VERSION ""

NS_ :

BS_:

BU_: Vector__XXX

BO_ 2566698238 SPOS: 8 Vector__XXX
SG_ SwitchedOutput4 : 0|2@1+ (1,0) [0|3] "" Vector__XXX
SG_ SwitchedOutput3 : 2|2@1+ (1,0) [0|3] "" Vector__XXX
SG_ SwitchedOutput2 : 4|2@1+ (1,0) [0|3] "" Vector__XXX
SG_ SwitchedOutput1 : 6|2@1+ (1,0) [0|3] "" Vector__XXX
SG_ SwitchedOutput8 : 8|2@1+ (1,0) [0|3] "" Vector__XXX
SG_ SwitchedOutput7 : 10|2@1+ (1,0) [0|3] "" Vector__XXX
SG_ SwitchedOutput6 : 12|2@1+ (1,0) [0|3] "" Vector__XXX
SG_ SwitchedOutput5 : 14|2@1+ (1,0) [0|3] "" Vector__XXX
SG_ SwitchedOutput12 : 16|2@1+ (1,0) [0|3] "" Vector__XXX
SG_ SwitchedOutput11 : 18|2@1+ (1,0) [0|3] "" Vector__XXX
SG_ SwitchedOutput10 : 20|2@1+ (1,0) [0|3] "" Vector__XXX
SG_ SwitchedOutput9 : 22|2@1+ (1,0) [0|3] "" Vector__XXX
SG_ SwitchedOutput16 : 24|2@1+ (1,0) [0|3] "" Vector__XXX
SG_ SwitchedOutput15 : 26|2@1+ (1,0) [0|3] "" Vector__XXX
SG_ SwitchedOutput14 : 28|2@1+ (1,0) [0|3] "" Vector__XXX
SG_ SwitchedOutput13 : 30|2@1+ (1,0) [0|3] "" Vector__XXX
SG_ SwitchedOutput20 : 32|2@1+ (1,0) [0|3] "" Vector__XXX
SG_ SwitchedOutput19 : 34|2@1+ (1,0) [0|3] "" Vector__XXX
SG_ SwitchedOutput18 : 36|2@1+ (1,0) [0|3] "" Vector__XXX
SG_ SwitchedOutput17 : 38|2@1+ (1,0) [0|3] "" Vector__XXX
SG_ SwitchedOutput24 : 40|2@1+ (1,0) [0|3] "" Vector__XXX
SG_ SwitchedOutput23 : 42|2@1+ (1,0) [0|3] "" Vector__XXX
SG_ SwitchedOutput22 : 44|2@1+ (1,0) [0|3] "" Vector__XXX
SG_ SwitchedOutput21 : 46|2@1+ (1,0) [0|3] "" Vector__XXX
SG_ SwitchedOutput28 : 48|2@1+ (1,0) [0|3] "" Vector__XXX
SG_ SwitchedOutput27 : 50|2@1+ (1,0) [0|3] "" Vector__XXX
SG_ SwitchedOutput26 : 52|2@1+ (1,0) [0|3] "" Vector__XXX
SG_ SwitchedOutput25 : 54|2@1+ (1,0) [0|3] "" Vector__XXX
SG_ SwitchedOutput32 : 56|2@1+ (1,0) [0|3] "" Vector__XXX
SG_ SwitchedOutput31 : 58|2@1+ (1,0) [0|3] "" Vector__XXX
SG_ SwitchedOutput30 : 60|2@1+ (1,0) [0|3] "" Vector__XXX
SG_ SwitchedOutput29 : 62|2@1+ (1,0) [0|3] "" Vector__XXX

BO_ 2566698494 FPOS: 8 Vector__XXX
SG_ FusedOutput4 : 0|2@1+ (1,0) [0|3] "" Vector__XXX
SG_ FusedOutput3 : 2|2@1+ (1,0) [0|3] "" Vector__XXX
SG_ FusedOutput2 : 4|2@1+ (1,0) [0|3] "" Vector__XXX
SG_ FusedOutput1 : 6|2@1+ (1,0) [0|3] "" Vector__XXX
SG_ FusedOutput8 : 8|2@1+ (1,0) [0|3] "" Vector__XXX
SG_ FusedOutput7 : 10|2@1+ (1,0) [0|3] "" Vector__XXX
SG_ FusedOutput6 : 12|2@1+ (1,0) [0|3] "" Vector__XXX
SG_ FusedOutput5 : 14|2@1+ (1,0) [0|3] "" Vector__XXX
SG_ FusedOutput12 : 16|2@1+ (1,0) [0|3] "" Vector__XXX
SG_ FusedOutput11 : 18|2@1+ (1,0) [0|3] "" Vector__XXX
SG_ FusedOutput10 : 20|2@1+ (1,0) [0|3] "" Vector__XXX
SG_ FusedOutput9 : 22|2@1+ (1,0) [0|3] "" Vector__XXX
SG_ FusedOutput16 : 24|2@1+ (1,0) [0|3] "" Vector__XXX
SG_ FusedOutput15 : 26|2@1+ (1,0) [0|3] "" Vector__XXX
SG_ FusedOutput14 : 28|2@1+ (1,0) [0|3] "" Vector__XXX
SG_ FusedOutput13 : 30|2@1+ (1,0) [0|3] "" Vector__XXX
SG_ FusedOutput20 : 32|2@1+ (1,0) [0|3] "" Vector__XXX
SG_ FusedOutput19 : 34|2@1+ (1,0) [0|3] "" Vector__XXX
SG_ FusedOutput18 : 36|2@1+ (1,0) [0|3] "" Vector__XXX
SG_ FusedOutput17 : 38|2@1+ (1,0) [0|3] "" Vector__XXX
SG_ FusedOutput24 : 40|2@1+ (1,0) [0|3] "" Vector__XXX
SG_ FusedOutput23 : 42|2@1+ (1,0) [0|3] "" Vector__XXX
SG_ FusedOutput22 : 44|2@1+ (1,0) [0|3] "" Vector__XXX
SG_ FusedOutput21 : 46|2@1+ (1,0) [0|3] "" Vector__XXX
SG_ FusedOutput28 : 48|2@1+ (1,0) [0|3] "" Vector__XXX
SG_ FusedOutput27 : 50|2@1+ (1,0) [0|3] "" Vector__XXX
SG_ FusedOutput26 : 52|2@1+ (1,0) [0|3] "" Vector__XXX
SG_ FusedOutput25 : 54|2@1+ (1,0) [0|3] "" Vector__XXX
SG_ FusedOutput32 : 56|2@1+ (1,0) [0|3] "" Vector__XXX
SG_ FusedOutput31 : 58|2@1+ (1,0) [0|3] "" Vector__XXX
SG_ FusedOutput30 : 60|2@1+ (1,0) [0|3] "" Vector__XXX
SG_ FusedOutput29 : 62|2@1+ (1,0) [0|3] "" Vector__XXX

BO_ 2566698750 VEP5: 8 Vector__XXX
SG_ SLIBatteryPackStateOfCharge : 0|16@1+ (0.0025,0) [0|160.6375] "%" Vector__XXX
SG_ SLIBatteryPackCapacity : 16|16@1+ (1,0) [0|64255] "Ah" Vector__XXX
SG_ SLIBatteryPackHealth : 32|8@1+ (0.5,0) [0|125] "%" Vector__XXX
SG_ SLICrnkngPredictMinBattryVoltage : 40|8@1+ (0.2,0) [0|50] "V" Vector__XXX

BO_ 2566699006 HSS2: 8 Vector__XXX
SG_ HybridBatteryPackRemainingCharge : 0|16@1+ (0.0025,0) [0|160.6375] "%" Vector__XXX
SG_ HybridSysEngStopStrtRemnPrcntage : 16|8@1+ (0.4,0) [0|100] "%" Vector__XXX

BO_ 2566699262 AT2S2: 8 Vector__XXX
SG_ Aft2DslPFTmeToNextActvRegen : 0|32@1+ (1,0) [0|4211081215] "s" Vector__XXX
SG_ Aft2SCRSysTmeSncLastSysCleanEvnt : 32|32@1+ (1,0) [0|4211081215] "s" Vector__XXX

BO_ 2566699518 AT1S2: 8 Vector__XXX
SG_ Aft1DslPFTmeToNextActvRegen : 0|32@1+ (1,0) [0|4211081215] "s" Vector__XXX
SG_ Aft1SCRSysTmeSncLastSysCleanEvnt : 32|32@1+ (1,0) [0|4211081215] "s" Vector__XXX

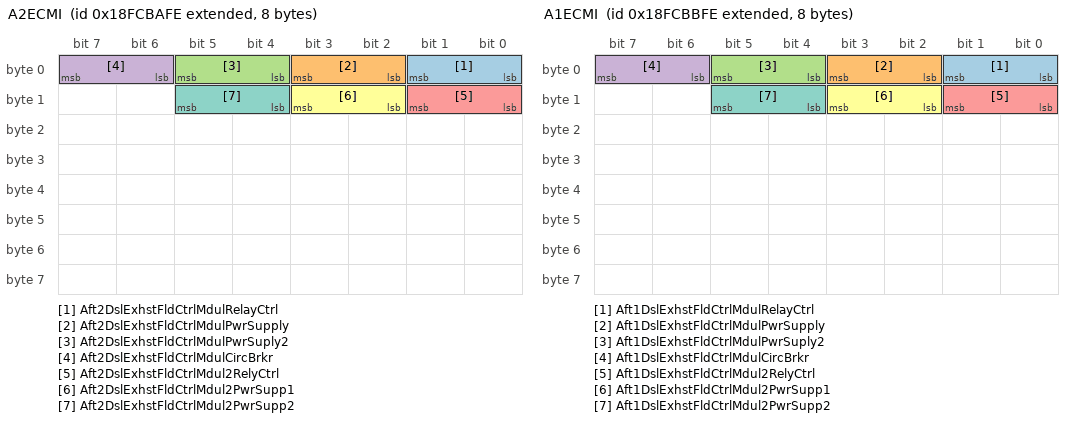
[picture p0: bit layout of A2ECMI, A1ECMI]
BO_ 2566699774 A2ECMI: 8 Vector__XXX
SG_ Aft2DslExhstFldCtrlMdulRelayCtrl : 0|2@1+ (1,0) [0|3] "" Vector__XXX
SG_ Aft2DslExhstFldCtrlMdulPwrSupply : 2|2@1+ (1,0) [0|3] "" Vector__XXX
SG_ Aft2DslExhstFldCtrlMdulPwrSuply2 : 4|2@1+ (1,0) [0|3] "" Vector__XXX
SG_ Aft2DslExhstFldCtrlMdulCircBrkr : 6|2@1+ (1,0) [0|3] "" Vector__XXX
SG_ Aft2DslExhstFldCtrlMdul2RelyCtrl : 8|2@1+ (1,0) [0|3] "" Vector__XXX
SG_ Aft2DslExhstFldCtrlMdul2PwrSupp1 : 10|2@1+ (1,0) [0|3] "" Vector__XXX
SG_ Aft2DslExhstFldCtrlMdul2PwrSupp2 : 12|2@1+ (1,0) [0|3] "" Vector__XXX

BO_ 2566700030 A1ECMI: 8 Vector__XXX
SG_ Aft1DslExhstFldCtrlMdulRelayCtrl : 0|2@1+ (1,0) [0|3] "" Vector__XXX
SG_ Aft1DslExhstFldCtrlMdulPwrSupply : 2|2@1+ (1,0) [0|3] "" Vector__XXX
SG_ Aft1DslExhstFldCtrlMdulPwrSuply2 : 4|2@1+ (1,0) [0|3] "" Vector__XXX
SG_ Aft1DslExhstFldCtrlMdulCircBrkr : 6|2@1+ (1,0) [0|3] "" Vector__XXX
SG_ Aft1DslExhstFldCtrlMdul2RelyCtrl : 8|2@1+ (1,0) [0|3] "" Vector__XXX
SG_ Aft1DslExhstFldCtrlMdul2PwrSupp1 : 10|2@1+ (1,0) [0|3] "" Vector__XXX
SG_ Aft1DslExhstFldCtrlMdul2PwrSupp2 : 12|2@1+ (1,0) [0|3] "" Vector__XXX

BO_ 2566700286 A2SCRSI2: 8 Vector__XXX
SG_ Aftrtrtmnt2TotalDslExhstFldUsed : 0|32@1+ (0.5,0) [0|2105540607.5] "l" Vector__XXX

BO_ 2566700542 A1SCRSI2: 8 Vector__XXX
SG_ Aftrtrtmnt1TotalDslExhstFldUsed : 0|32@1+ (0.5,0) [0|2105540607.5] "l" Vector__XXX
SG_ AftrtrtmntTripDieselExhaustFluid : 32|32@1+ (0.05,0) [0|210554060.75] "l" Vector__XXX

BO_ 2365374206 ETC9: 8 Vector__XXX
SG_ DualCltchTrnsmInputShft1Spd : 0|16@1+ (0.125,0) [0|8031.875] "rpm" Vector__XXX
SG_ DualCltchTrnsmInputShft2Spd : 16|16@1+ (0.125,0) [0|8031.875] "rpm" Vector__XXX
SG_ DualCltchTrnsmSelPreSelctionGear : 32|8@1+ (1,-125) [-125|125] "" Vector__XXX
SG_ DualCltchTrnsmCurrPreSlctionGear : 40|8@1+ (1,-125) [-125|125] "" Vector__XXX

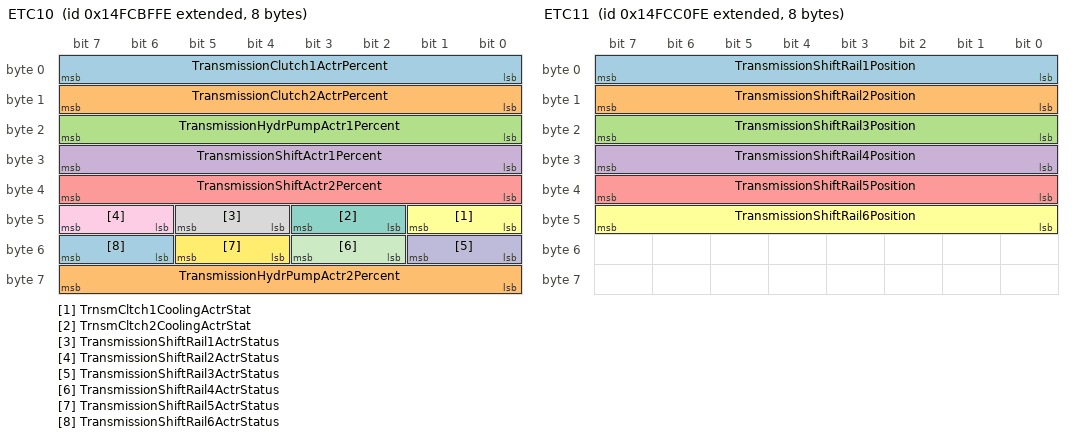
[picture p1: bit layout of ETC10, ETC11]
BO_ 2499592190 ETC10: 8 Vector__XXX
SG_ TransmissionClutch1ActrPercent : 0|8@1+ (0.4,0) [0|100] "%" Vector__XXX
SG_ TransmissionClutch2ActrPercent : 8|8@1+ (0.4,0) [0|100] "%" Vector__XXX
SG_ TransmissionHydrPumpActr1Percent : 16|8@1+ (0.4,0) [0|100] "%" Vector__XXX
SG_ TransmissionShiftActr1Percent : 24|8@1+ (0.4,0) [0|100] "%" Vector__XXX
SG_ TransmissionShiftActr2Percent : 32|8@1+ (0.4,0) [0|100] "%" Vector__XXX
SG_ TrnsmCltch1CoolingActrStat : 40|2@1+ (1,0) [0|3] "" Vector__XXX
SG_ TrnsmCltch2CoolingActrStat : 42|2@1+ (1,0) [0|3] "" Vector__XXX
SG_ TransmissionShiftRail1ActrStatus : 44|2@1+ (1,0) [0|3] "" Vector__XXX
SG_ TransmissionShiftRail2ActrStatus : 46|2@1+ (1,0) [0|3] "" Vector__XXX
SG_ TransmissionShiftRail3ActrStatus : 48|2@1+ (1,0) [0|3] "" Vector__XXX
SG_ TransmissionShiftRail4ActrStatus : 50|2@1+ (1,0) [0|3] "" Vector__XXX
SG_ TransmissionShiftRail5ActrStatus : 52|2@1+ (1,0) [0|3] "" Vector__XXX
SG_ TransmissionShiftRail6ActrStatus : 54|2@1+ (1,0) [0|3] "" Vector__XXX
SG_ TransmissionHydrPumpActr2Percent : 56|8@1+ (0.4,0) [0|100] "%" Vector__XXX

BO_ 2499592446 ETC11: 8 Vector__XXX
SG_ TransmissionShiftRail1Position : 0|8@1+ (0.4,0) [0|100] "%" Vector__XXX
SG_ TransmissionShiftRail2Position : 8|8@1+ (0.4,0) [0|100] "%" Vector__XXX
SG_ TransmissionShiftRail3Position : 16|8@1+ (0.4,0) [0|100] "%" Vector__XXX
SG_ TransmissionShiftRail4Position : 24|8@1+ (0.4,0) [0|100] "%" Vector__XXX
SG_ TransmissionShiftRail5Position : 32|8@1+ (0.4,0) [0|100] "%" Vector__XXX
SG_ TransmissionShiftRail6Position : 40|8@1+ (0.4,0) [0|100] "%" Vector__XXX

BO_ 2566701566 TRF3: 8 Vector__XXX
SG_ TransmissionClutch2Pressure : 0|8@1+ (16,0) [0|4000] "kPa" Vector__XXX
SG_ TrnsmOilTransmissionCoolOtltTemp : 8|8@1+ (1,-40) [-40|210] "deg C" Vector__XXX

BO_ 2566701822 HSS: 8 Vector__XXX
SG_ HybridSystemWarningIndicator : 0|2@1+ (1,0) [0|3] "" Vector__XXX
SG_ HybridSystemOverheatIndicator : 2|2@1+ (1,0) [0|3] "" Vector__XXX
SG_ HybridSystemStopIndicator : 4|2@1+ (1,0) [0|3] "" Vector__XXX
SG_ HybridSystemOBDRelatedDTCStatus : 6|2@1+ (1,0) [0|3] "" Vector__XXX
SG_ PropulsionSystemActive : 8|2@1+ (1,0) [0|3] "" Vector__XXX
SG_ HybridSystemEngineAssistStatus : 10|2@1+ (1,0) [0|3] "" Vector__XXX
SG_ HybridSystemServiceIndicator : 12|2@1+ (1,0) [0|3] "" Vector__XXX
SG_ HybridSystemMtrOverspeedIndictr : 14|2@1+ (1,0) [0|3] "" Vector__XXX
SG_ HybridSysMtrOverspdAudibleAlarm : 16|2@1+ (1,0) [0|3] "" Vector__XXX
SG_ HybridSysElectricAltrntrIndictr : 18|2@1+ (1,0) [0|3] "" Vector__XXX
SG_ HybridSystemRegativeBrkngIndictr : 20|2@1+ (1,0) [0|3] "" Vector__XXX
SG_ HybridSystemInitIndictr : 22|2@1+ (1,0) [0|3] "" Vector__XXX
SG_ HybridSysHghVltgExposureIndictr : 24|2@1+ (1,0) [0|3] "" Vector__XXX
SG_ StoredEnergySourceOnlyModeAllwd : 26|2@1+ (1,0) [0|3] "" Vector__XXX
SG_ StoredEnergySrcIncreasngMdeAllwd : 28|2@1+ (1,0) [0|3] "" Vector__XXX
SG_ StoredEnergySourceLevel : 32|8@1+ (0.4,0) [0|100] "%" Vector__XXX
SG_ HybridPropulsionModeStatus : 40|4@1+ (1,0) [0|15] "" Vector__XXX
SG_ HybridProplsnMdeTransitionStatus : 44|4@1+ (1,0) [0|15] "" Vector__XXX
SG_ ExtEnergySourceConnectnStatus : 48|4@1+ (1,0) [0|15] "" Vector__XXX
SG_ HybridSystemProplsnDisablStatus : 52|2@1+ (1,0) [0|3] "" Vector__XXX

BO_ 2566702078 GFI4: 8 Vector__XXX
SG_ SupplyGasMethanePercentage : 0|16@1+ (0.0025,0) [0|160.6375] "%" Vector__XXX

BO_ 2566702334 A2SCREGT2: 8 Vector__XXX
SG_ Aftrtrtmnt2SCRIntrmedTemperature : 0|16@1+ (0.03125,-273) [-273|1734.96875] "deg C" Vector__XXX
SG_ Aft2SCRIntrmedTempPrelimFMI : 16|5@1+ (1,0) [0|31] "" Vector__XXX

BO_ 2566702590 A1SCREGT2: 8 Vector__XXX
SG_ Aftrtrtmnt1SCRIntrmedTemperature : 0|16@1+ (0.03125,-273) [-273|1734.96875] "deg C" Vector__XXX
SG_ Aft1SCRIntrmedTempPrelimFMI : 16|5@1+ (1,0) [0|31] "" Vector__XXX

BO_ 2566702846 DM57: 1 Vector__XXX
SG_ EngineOBDWarmUpSequence : 0|2@1+ (1,0) [0|3] "" Vector__XXX

BO_ 2566703102 DM56: 200 Vector__XXX
SG_ ModelYear : 7|64@0+ (1,0) [0|0] "ASCII" Vector__XXX
SG_ CertificationEngineFamilyName : 7|1600@0+ (1,0) [0|0] "ASCII" Vector__XXX

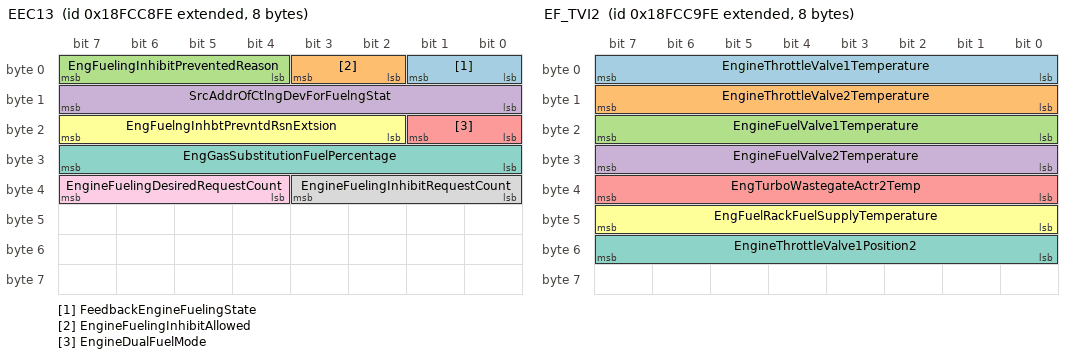
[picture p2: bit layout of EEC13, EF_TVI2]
BO_ 2566703358 EEC13: 8 Vector__XXX
SG_ FeedbackEngineFuelingState : 0|2@1+ (1,0) [0|3] "" Vector__XXX
SG_ EngineFuelingInhibitAllowed : 2|2@1+ (1,0) [0|3] "" Vector__XXX
SG_ EngFuelingInhibitPreventedReason : 4|4@1+ (1,0) [0|15] "" Vector__XXX
SG_ SrcAddrOfCtlngDevForFuelngStat : 8|8@1+ (1,0) [0|255] "" Vector__XXX
SG_ EngineDualFuelMode : 16|2@1+ (1,0) [0|3] "" Vector__XXX
SG_ EngFuelngInhbtPrevntdRsnExtsion : 18|6@1+ (1,0) [0|63] "" Vector__XXX
SG_ EngGasSubstitutionFuelPercentage : 24|8@1+ (0.5,0) [0|125] "%" Vector__XXX
SG_ EngineFuelingInhibitRequestCount : 32|4@1+ (1,0) [0|15] "" Vector__XXX
SG_ EngineFuelingDesiredRequestCount : 36|4@1+ (1,0) [0|15] "" Vector__XXX

BO_ 2566703614 EF_TVI2: 8 Vector__XXX
SG_ EngineThrottleValve1Temperature : 0|8@1+ (1,-40) [-40|210] "deg C" Vector__XXX
SG_ EngineThrottleValve2Temperature : 8|8@1+ (1,-40) [-40|210] "deg C" Vector__XXX
SG_ EngineFuelValve1Temperature : 16|8@1+ (1,-40) [-40|210] "deg C" Vector__XXX
SG_ EngineFuelValve2Temperature : 24|8@1+ (1,-40) [-40|210] "deg C" Vector__XXX
SG_ EngTurboWastegateActr2Temp : 32|8@1+ (1,-40) [-40|210] "deg C" Vector__XXX
SG_ EngFuelRackFuelSupplyTemperature : 40|8@1+ (1,-40) [-40|210] "deg C" Vector__XXX
SG_ EngineThrottleValve1Position2 : 48|8@1+ (0.4,0) [0|100] "%" Vector__XXX

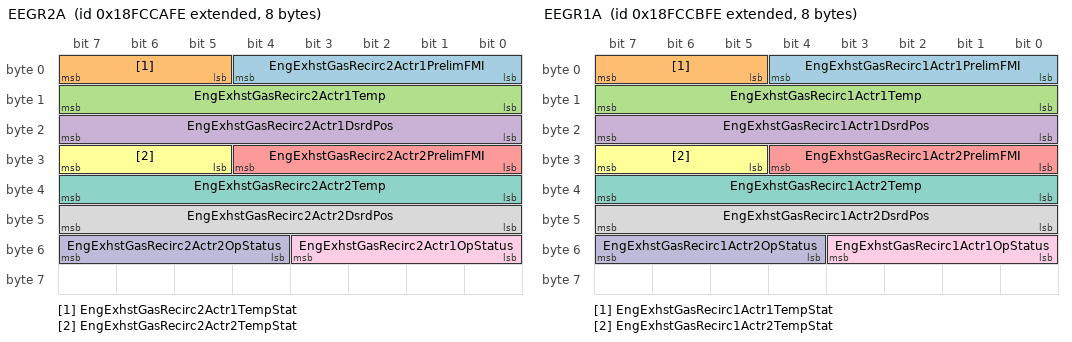
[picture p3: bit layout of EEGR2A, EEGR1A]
BO_ 2566703870 EEGR2A: 8 Vector__XXX
SG_ EngExhstGasRecirc2Actr1PrelimFMI : 0|5@1+ (1,0) [0|31] "" Vector__XXX
SG_ EngExhstGasRecirc2Actr1TempStat : 5|3@1+ (1,0) [0|7] "" Vector__XXX
SG_ EngExhstGasRecirc2Actr1Temp : 8|8@1+ (1,-40) [-40|210] "deg C" Vector__XXX
SG_ EngExhstGasRecirc2Actr1DsrdPos : 16|8@1+ (0.4,0) [0|100] "%" Vector__XXX
SG_ EngExhstGasRecirc2Actr2PrelimFMI : 24|5@1+ (1,0) [0|31] "" Vector__XXX
SG_ EngExhstGasRecirc2Actr2TempStat : 29|3@1+ (1,0) [0|7] "" Vector__XXX
SG_ EngExhstGasRecirc2Actr2Temp : 32|8@1+ (1,-40) [-40|210] "deg C" Vector__XXX
SG_ EngExhstGasRecirc2Actr2DsrdPos : 40|8@1+ (0.4,0) [0|100] "%" Vector__XXX
SG_ EngExhstGasRecirc2Actr1OpStatus : 48|4@1+ (1,0) [0|15] "" Vector__XXX
SG_ EngExhstGasRecirc2Actr2OpStatus : 52|4@1+ (1,0) [0|15] "" Vector__XXX

BO_ 2566704126 EEGR1A: 8 Vector__XXX
SG_ EngExhstGasRecirc1Actr1PrelimFMI : 0|5@1+ (1,0) [0|31] "" Vector__XXX
SG_ EngExhstGasRecirc1Actr1TempStat : 5|3@1+ (1,0) [0|7] "" Vector__XXX
SG_ EngExhstGasRecirc1Actr1Temp : 8|8@1+ (1,-40) [-40|210] "deg C" Vector__XXX
SG_ EngExhstGasRecirc1Actr1DsrdPos : 16|8@1+ (0.4,0) [0|100] "%" Vector__XXX
SG_ EngExhstGasRecirc1Actr2PrelimFMI : 24|5@1+ (1,0) [0|31] "" Vector__XXX
SG_ EngExhstGasRecirc1Actr2TempStat : 29|3@1+ (1,0) [0|7] "" Vector__XXX
SG_ EngExhstGasRecirc1Actr2Temp : 32|8@1+ (1,-40) [-40|210] "deg C" Vector__XXX
SG_ EngExhstGasRecirc1Actr2DsrdPos : 40|8@1+ (0.4,0) [0|100] "%" Vector__XXX
SG_ EngExhstGasRecirc1Actr1OpStatus : 48|4@1+ (1,0) [0|15] "" Vector__XXX
SG_ EngExhstGasRecirc1Actr2OpStatus : 52|4@1+ (1,0) [0|15] "" Vector__XXX

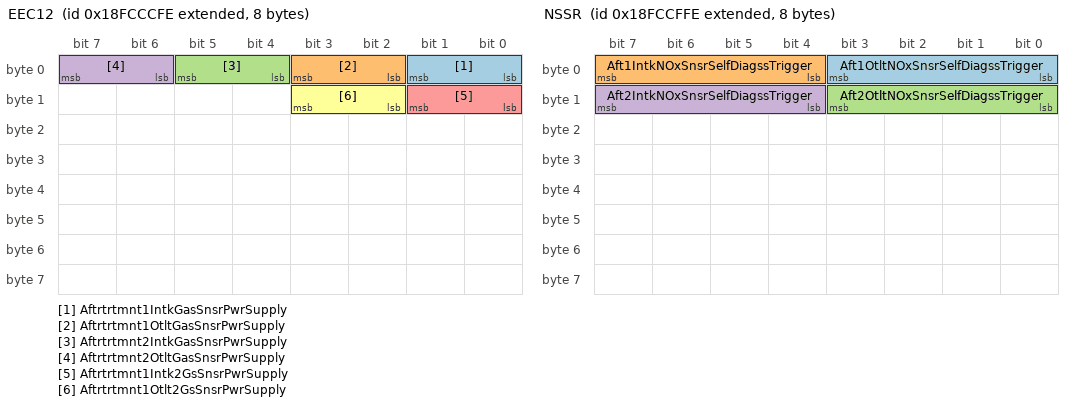
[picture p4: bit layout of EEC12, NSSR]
BO_ 2566704382 EEC12: 8 Vector__XXX
SG_ Aftrtrtmnt1IntkGasSnsrPwrSupply : 0|2@1+ (1,0) [0|3] "" Vector__XXX
SG_ Aftrtrtmnt1OtltGasSnsrPwrSupply : 2|2@1+ (1,0) [0|3] "" Vector__XXX
SG_ Aftrtrtmnt2IntkGasSnsrPwrSupply : 4|2@1+ (1,0) [0|3] "" Vector__XXX
SG_ Aftrtrtmnt2OtltGasSnsrPwrSupply : 6|2@1+ (1,0) [0|3] "" Vector__XXX
SG_ Aftrtrtmnt1Intk2GsSnsrPwrSupply : 8|2@1+ (1,0) [0|3] "" Vector__XXX
SG_ Aftrtrtmnt1Otlt2GsSnsrPwrSupply : 10|2@1+ (1,0) [0|3] "" Vector__XXX

BO_ 2566705150 NSSR: 8 Vector__XXX
SG_ Aft1OtltNOxSnsrSelfDiagssTrigger : 0|4@1+ (1,0) [0|15] "" Vector__XXX
SG_ Aft1IntkNOxSnsrSelfDiagssTrigger : 4|4@1+ (1,0) [0|15] "" Vector__XXX
SG_ Aft2OtltNOxSnsrSelfDiagssTrigger : 8|4@1+ (1,0) [0|15] "" Vector__XXX
SG_ Aft2IntkNOxSnsrSelfDiagssTrigger : 12|4@1+ (1,0) [0|15] "" Vector__XXX

BO_ 2566705406 EPSI: 8 Vector__XXX
SG_ Aftertreatment1ParticulateSensor : 0|16@1+ (0.0125,0) [0|803.1875] "mg/m^3" Vector__XXX
SG_ Aftertreatment2ParticulateSensor : 16|16@1+ (0.0125,0) [0|803.1875] "mg/m^3" Vector__XXX
SG_ Aftrtrtmnt1ParticulateSensorCurr : 32|16@1+ (0.00390625,0) [0|250.99609375] "uA" Vector__XXX

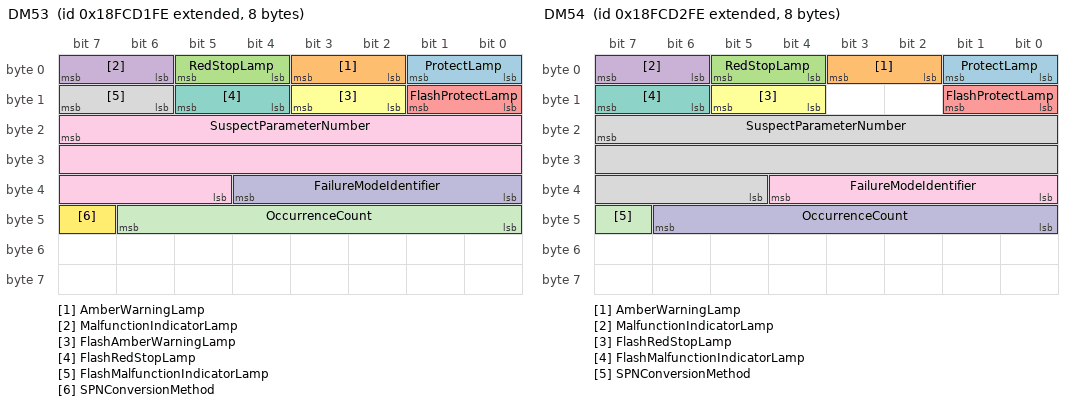
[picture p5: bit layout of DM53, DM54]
BO_ 2566705662 DM53: 8 Vector__XXX
SG_ ProtectLamp : 0|2@1+ (1,0) [0|3] "" Vector__XXX
SG_ AmberWarningLamp : 2|2@1+ (1,0) [0|3] "" Vector__XXX
SG_ RedStopLamp : 4|2@1+ (1,0) [0|3] "" Vector__XXX
SG_ MalfunctionIndicatorLamp : 6|2@1+ (1,0) [0|3] "" Vector__XXX
SG_ FlashProtectLamp : 8|2@1+ (1,0) [0|3] "" Vector__XXX
SG_ FlashAmberWarningLamp : 10|2@1+ (1,0) [0|3] "" Vector__XXX
SG_ FlashRedStopLamp : 12|2@1+ (1,0) [0|3] "" Vector__XXX
SG_ FlashMalfunctionIndicatorLamp : 14|2@1+ (1,0) [0|3] "" Vector__XXX
SG_ SuspectParameterNumber : 23|19@0+ (1,0) [0|524287] "" Vector__XXX
SG_ FailureModeIdentifier : 32|5@1+ (1,0) [0|31] "" Vector__XXX
SG_ OccurrenceCount : 40|7@1+ (1,0) [0|127] "" Vector__XXX
SG_ SPNConversionMethod : 47|1@1+ (1,0) [0|1] "" Vector__XXX

BO_ 2566705918 DM54: 8 Vector__XXX
SG_ ProtectLamp : 0|2@1+ (1,0) [0|3] "" Vector__XXX
SG_ AmberWarningLamp : 2|2@1+ (1,0) [0|3] "" Vector__XXX
SG_ RedStopLamp : 4|2@1+ (1,0) [0|3] "" Vector__XXX
SG_ MalfunctionIndicatorLamp : 6|2@1+ (1,0) [0|3] "" Vector__XXX
SG_ FlashProtectLamp : 8|2@1+ (1,0) [0|3] "" Vector__XXX
SG_ FlashRedStopLamp : 12|2@1+ (1,0) [0|3] "" Vector__XXX
SG_ FlashMalfunctionIndicatorLamp : 14|2@1+ (1,0) [0|3] "" Vector__XXX
SG_ SuspectParameterNumber : 23|19@0+ (1,0) [0|524287] "" Vector__XXX
SG_ FailureModeIdentifier : 32|5@1+ (1,0) [0|31] "" Vector__XXX
SG_ OccurrenceCount : 40|7@1+ (1,0) [0|127] "" Vector__XXX
SG_ SPNConversionMethod : 47|1@1+ (1,0) [0|1] "" Vector__XXX

BO_ 2566706174 DM55: 0 Vector__XXX

BO_ 2566706430 XCP_ID: 0 Vector__XXX

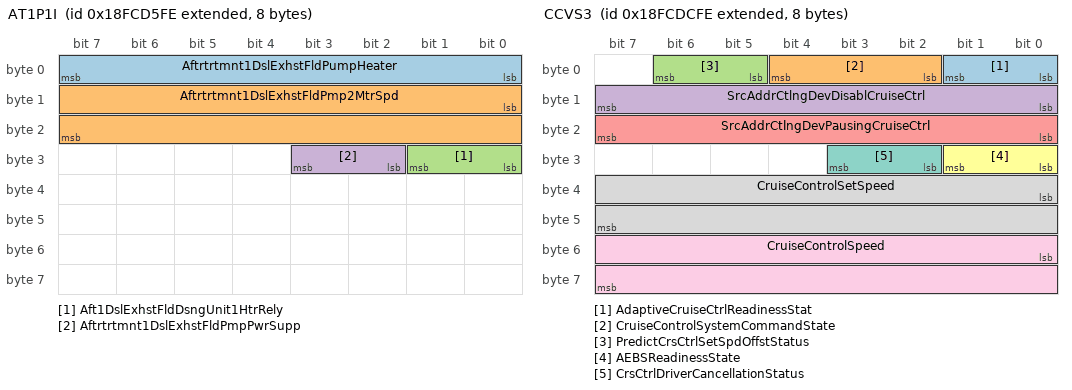
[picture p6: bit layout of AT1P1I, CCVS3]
BO_ 2566706686 AT1P1I: 8 Vector__XXX
SG_ Aftrtrtmnt1DslExhstFldPumpHeater : 0|8@1+ (0.4,0) [0|100] "%" Vector__XXX
SG_ Aftrtrtmnt1DslExhstFldPmp2MtrSpd : 8|16@1+ (0.5,0) [0|32127.5] "rpm" Vector__XXX
SG_ Aft1DslExhstFldDsngUnit1HtrRely : 24|2@1+ (1,0) [0|3] "" Vector__XXX
SG_ Aftrtrtmnt1DslExhstFldPmpPwrSupp : 26|2@1+ (1,0) [0|3] "" Vector__XXX

BO_ 2566706942 AT1DPF2S5: 8 Vector__XXX
SG_ Aft1DslPF2SootSnsrAnalyFreq3 : 0|16@1+ (0.1,0) [0|6425.5] "MHz" Vector__XXX
SG_ Aft1DslPF2SootSnsrFreq3SootSig : 16|16@1+ (0.0025,0) [0|160.6375] "%" Vector__XXX
SG_ Aft1DslPF2SootSnsrAnalyFreq4 : 32|16@1+ (0.1,0) [0|6425.5] "MHz" Vector__XXX
SG_ Aft1DslPF2SootSnsrFreq4SootSig : 48|16@1+ (0.0025,0) [0|160.6375] "%" Vector__XXX

BO_ 2566707198 AT1DPF2S4: 8 Vector__XXX
SG_ Aft1DslPF2SootSnsrAnalyFreq1 : 0|16@1+ (0.1,0) [0|6425.5] "MHz" Vector__XXX
SG_ Aft1DslPF2SootSnsrFreq1SootSig : 16|16@1+ (0.0025,0) [0|160.6375] "%" Vector__XXX
SG_ Aft1DslPF2SootSnsrAnalyFreq2 : 32|16@1+ (0.1,0) [0|6425.5] "MHz" Vector__XXX
SG_ Aft1DslPF2SootSnsrFreq2SootSig : 48|16@1+ (0.0025,0) [0|160.6375] "%" Vector__XXX

BO_ 2566707454 AT1DPF2S3: 8 Vector__XXX
SG_ Aft1DslPF2SootSnsrAnalyRqFreq1 : 0|16@1+ (0.1,0) [0|6425.5] "MHz" Vector__XXX
SG_ Aft1DslPF2SootSnsrAnalyRqFreq2 : 16|16@1+ (0.1,0) [0|6425.5] "MHz" Vector__XXX
SG_ Aft1DslPF2SootSnsrAnalyRqFreq3 : 32|16@1+ (0.1,0) [0|6425.5] "MHz" Vector__XXX
SG_ Aft1DslPF2SootSnsrAnalyRqFreq4 : 48|16@1+ (0.1,0) [0|6425.5] "MHz" Vector__XXX

BO_ 2566707710 AT1DPF1S5: 8 Vector__XXX
SG_ Aft1DslPF1SootSnsrAnalyFreq3 : 0|16@1+ (0.1,0) [0|6425.5] "MHz" Vector__XXX
SG_ Aft1DslPF1SootSnsrFreq3SootSig : 16|16@1+ (0.0025,0) [0|160.6375] "%" Vector__XXX
SG_ Aft1DslPF1SootSnsrAnalyFreq4 : 32|16@1+ (0.1,0) [0|6425.5] "MHz" Vector__XXX
SG_ Aft1DslPF1SootSnsrFreq4SootSig : 48|16@1+ (0.0025,0) [0|160.6375] "%" Vector__XXX

BO_ 2566707966 AT1DPF1S4: 8 Vector__XXX
SG_ Aft1DslPF1SootSnsrAnalyFreq1 : 0|16@1+ (0.1,0) [0|6425.5] "MHz" Vector__XXX
SG_ Aft1DslPF1SootSnsrFreq1SootSig : 16|16@1+ (0.0025,0) [0|160.6375] "%" Vector__XXX
SG_ Aft1DslPF1SootSnsrAnalyFreq2 : 32|16@1+ (0.1,0) [0|6425.5] "MHz" Vector__XXX
SG_ Aft1DslPF1SootSnsrFreq2SootSig : 48|16@1+ (0.0025,0) [0|160.6375] "%" Vector__XXX

BO_ 2566708222 AT1DPF1S3: 8 Vector__XXX
SG_ Aft1DslPF1SootSnsrAnalyRqFreq1 : 0|16@1+ (0.1,0) [0|6425.5] "MHz" Vector__XXX
SG_ Aft1DslPF1SootSnsrAnalyRqFreq2 : 16|16@1+ (0.1,0) [0|6425.5] "MHz" Vector__XXX
SG_ Aft1DslPF1SootSnsrAnalyRqFreq3 : 32|16@1+ (0.1,0) [0|6425.5] "MHz" Vector__XXX
SG_ Aft1DslPF1SootSnsrAnalyRqFreq4 : 48|16@1+ (0.1,0) [0|6425.5] "MHz" Vector__XXX

BO_ 2566708478 CCVS3: 8 Vector__XXX
SG_ AdaptiveCruiseCtrlReadinessStat : 0|2@1+ (1,0) [0|3] "" Vector__XXX
SG_ CruiseControlSystemCommandState : 2|3@1+ (1,0) [0|7] "" Vector__XXX
SG_ PredictCrsCtrlSetSpdOffstStatus : 5|2@1+ (1,0) [0|3] "" Vector__XXX
SG_ SrcAddrCtlngDevDisablCruiseCtrl : 8|8@1+ (1,0) [0|255] "" Vector__XXX
SG_ SrcAddrCtlngDevPausingCruiseCtrl : 16|8@1+ (1,0) [0|255] "" Vector__XXX
SG_ AEBSReadinessState : 24|2@1+ (1,0) [0|3] "" Vector__XXX
SG_ CrsCtrlDriverCancellationStatus : 26|2@1+ (1,0) [0|3] "" Vector__XXX
SG_ CruiseControlSetSpeed : 32|16@1+ (0.00390625,0) [0|250.996] "km/h" Vector__XXX
SG_ CruiseControlSpeed : 48|16@1+ (0.00390625,0) [0|250.996] "km/h" Vector__XXX

BO_ 2566708734 AT2AC3: 8 Vector__XXX
SG_ Aftrtrtmnt2SecondaryAirAbsPress : 0|16@1+ (0.1,0) [0|6425.5] "kPa" Vector__XXX

BO_ 2566708990 AT1AC3: 8 Vector__XXX
SG_ Aftrtrtmnt1SecondaryAirAbsPress : 0|16@1+ (0.1,0) [0|6425.5] "kPa" Vector__XXX

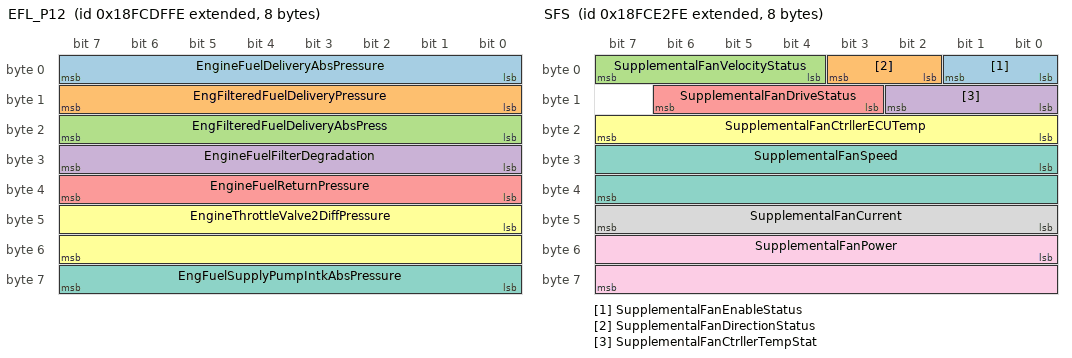
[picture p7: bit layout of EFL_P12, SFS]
BO_ 2566709246 EFL_P12: 8 Vector__XXX
SG_ EngineFuelDeliveryAbsPressure : 0|8@1+ (4,0) [0|1000] "kPa" Vector__XXX
SG_ EngFilteredFuelDeliveryPressure : 8|8@1+ (4,0) [0|1000] "kPa" Vector__XXX
SG_ EngFilteredFuelDeliveryAbsPress : 16|8@1+ (4,0) [0|1000] "kPa" Vector__XXX
SG_ EngineFuelFilterDegradation : 24|8@1+ (1,0) [0|250] "%" Vector__XXX
SG_ EngineFuelReturnPressure : 32|8@1+ (1.64,-7) [-7|403] "kPa" Vector__XXX
SG_ EngineThrottleValve2DiffPressure : 40|16@1+ (0.1,0) [0|6425.5] "kPa" Vector__XXX
SG_ EngFuelSupplyPumpIntkAbsPressure : 56|8@1+ (5,0) [0|1250] "kPa" Vector__XXX

BO_ 2566709502 DPFC2: 8 Vector__XXX
SG_ Aft1DslPFIntkTemperatuRstPoint : 0|16@1+ (0.03125,-273) [-273|1734.96875] "deg C" Vector__XXX
SG_ EngineUnburnedFuelPercentage : 16|16@1+ (0.0025,0) [0|160.6375] "%" Vector__XXX
SG_ Aftertreatment1FuelMassRate : 32|16@1+ (0.05,0) [0|3212.75] "g/m" Vector__XXX
SG_ Aftertreatment2FuelMassRate : 48|16@1+ (0.05,0) [0|3212.75] "g/m" Vector__XXX

BO_ 2566709758 LFE2: 8 Vector__XXX
SG_ EngineFuelRate : 0|32@1+ (0.001,0) [0|4211081.215] "l/h" Vector__XXX
SG_ EngineDieselFuelDemandRate : 32|16@1+ (0.05,0) [0|3212.75] "l/h" Vector__XXX

BO_ 2566710014 SFS: 8 Vector__XXX
SG_ SupplementalFanEnableStatus : 0|2@1+ (1,0) [0|3] "" Vector__XXX
SG_ SupplementalFanDirectionStatus : 2|2@1+ (1,0) [0|3] "" Vector__XXX
SG_ SupplementalFanVelocityStatus : 4|4@1+ (1,0) [0|15] "" Vector__XXX
SG_ SupplementalFanCtrllerTempStat : 8|3@1+ (1,0) [0|7] "" Vector__XXX
SG_ SupplementalFanDriveStatus : 11|4@1+ (1,0) [0|15] "" Vector__XXX
SG_ SupplementalFanCtrllerECUTemp : 16|8@1+ (1,-40) [-40|210] "deg C" Vector__XXX
SG_ SupplementalFanSpeed : 24|16@1+ (0.5,0) [0|32127.5] "rpm" Vector__XXX
SG_ SupplementalFanCurrent : 40|8@1+ (1,-125) [-125|125] "A" Vector__XXX
SG_ SupplementalFanPower : 48|16@1+ (0.5,0) [0|32127.5] "W" Vector__XXX

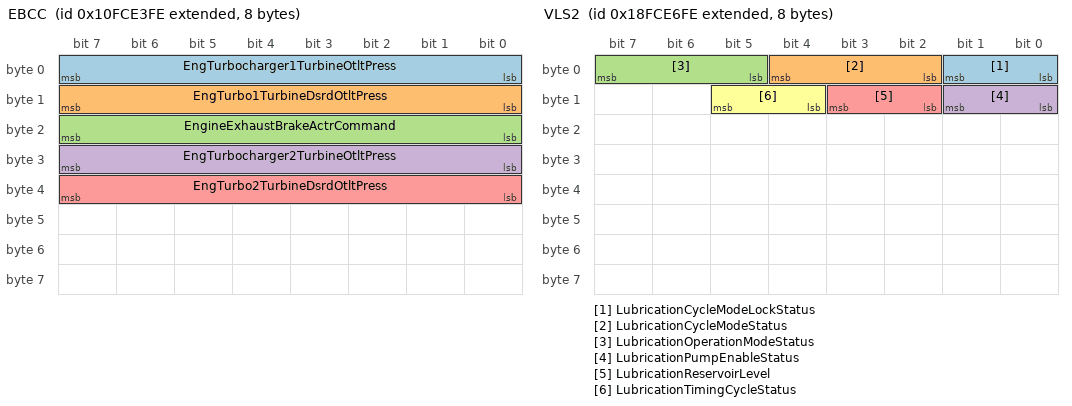
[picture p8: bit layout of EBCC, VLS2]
BO_ 2432492542 EBCC: 8 Vector__XXX
SG_ EngTurbocharger1TurbineOtltPress : 0|8@1+ (2,0) [0|500] "kPa" Vector__XXX
SG_ EngTurbo1TurbineDsrdOtltPress : 8|8@1+ (2,0) [0|500] "kPa" Vector__XXX
SG_ EngineExhaustBrakeActrCommand : 16|8@1+ (0.4,0) [0|100] "%" Vector__XXX
SG_ EngTurbocharger2TurbineOtltPress : 24|8@1+ (2,0) [0|500] "kPa" Vector__XXX
SG_ EngTurbo2TurbineDsrdOtltPress : 32|8@1+ (2,0) [0|500] "kPa" Vector__XXX

BO_ 2566710526 EFP: 8 Vector__XXX
SG_ EngineFuelDynamicViscosity : 0|16@1+ (0.015625,0) [0|1003.984375] "Cp" Vector__XXX
SG_ EngineFuelDensity : 16|16@1+ (3.052E-005,0) [0|1.961] "g/cc" Vector__XXX
SG_ EngineFuelDielectricity : 32|16@1+ (0.0001220703125,0) [0|7.844] "" Vector__XXX
SG_ EngineFuelTemperature : 48|16@1+ (0.03125,-273) [-273|1734.96875] "deg C" Vector__XXX

BO_ 2566710782 HOP: 8 Vector__XXX
SG_ HydraulicOilDynamicViscosity : 0|16@1+ (0.015625,0) [0|1003.984375] "Cp" Vector__XXX
SG_ HydraulicOilDensity : 16|16@1+ (3.052E-005,0) [0|1.961] "g/cc" Vector__XXX
SG_ HydrOilRelativeDielectricity : 32|16@1+ (0.0001220703125,0) [0|7.844] "" Vector__XXX
SG_ HydraulicOilTemperature : 48|16@1+ (0.03125,-273) [-273|1734.96875] "deg C" Vector__XXX

BO_ 2566711038 VLS2: 8 Vector__XXX
SG_ LubricationCycleModeLockStatus : 0|2@1+ (1,0) [0|3] "" Vector__XXX
SG_ LubricationCycleModeStatus : 2|3@1+ (1,0) [0|7] "" Vector__XXX
SG_ LubricationOperationModeStatus : 5|3@1+ (1,0) [0|7] "" Vector__XXX
SG_ LubricationPumpEnableStatus : 8|2@1+ (1,0) [0|3] "" Vector__XXX
SG_ LubricationReservoirLevel : 10|2@1+ (1,0) [0|3] "" Vector__XXX
SG_ LubricationTimingCycleStatus : 12|2@1+ (1,0) [0|3] "" Vector__XXX

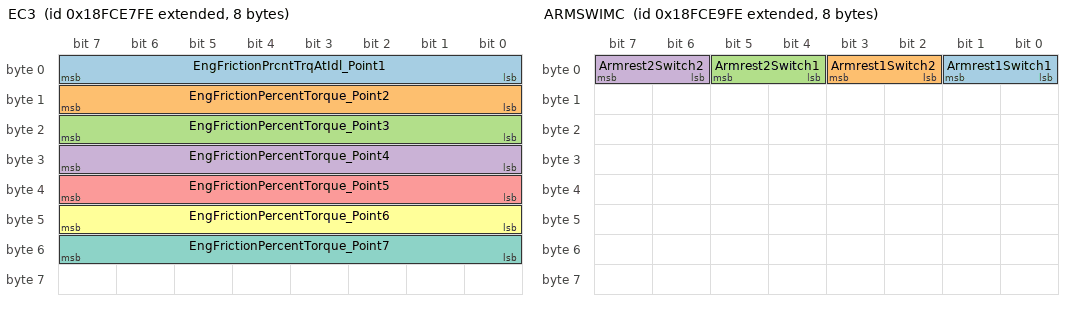
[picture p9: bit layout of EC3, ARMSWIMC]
BO_ 2566711294 EC3: 8 Vector__XXX
SG_ EngFrictionPrcntTrqAtIdl_Point1 : 0|8@1+ (1,-125) [-125|125] "%" Vector__XXX
SG_ EngFrictionPercentTorque_Point2 : 8|8@1+ (1,-125) [-125|125] "%" Vector__XXX
SG_ EngFrictionPercentTorque_Point3 : 16|8@1+ (1,-125) [-125|125] "%" Vector__XXX
SG_ EngFrictionPercentTorque_Point4 : 24|8@1+ (1,-125) [-125|125] "%" Vector__XXX
SG_ EngFrictionPercentTorque_Point5 : 32|8@1+ (1,-125) [-125|125] "%" Vector__XXX
SG_ EngFrictionPercentTorque_Point6 : 40|8@1+ (1,-125) [-125|125] "%" Vector__XXX
SG_ EngFrictionPercentTorque_Point7 : 48|8@1+ (1,-125) [-125|125] "%" Vector__XXX

BO_ 2566711550 IVAC: 8 Vector__XXX
SG_ IntkVlvActSysOilPrs1SolenoidCtrl : 0|2@1+ (1,0) [0|3] "" Vector__XXX
SG_ IntkVlvActSysOilPrs2SolenoidCtrl : 2|2@1+ (1,0) [0|3] "" Vector__XXX

BO_ 2566711806 ARMSWIMC: 8 Vector__XXX
SG_ Armrest1Switch1 : 0|2@1+ (1,0) [0|3] "" Vector__XXX
SG_ Armrest1Switch2 : 2|2@1+ (1,0) [0|3] "" Vector__XXX
SG_ Armrest2Switch1 : 4|2@1+ (1,0) [0|3] "" Vector__XXX
SG_ Armrest2Switch2 : 6|2@1+ (1,0) [0|3] "" Vector__XXX

BO_ 2566712318 AFT2NAI: 8 Vector__XXX
SG_ Aftrtrtmnt2NOxAdsorberRegenStat : 0|2@1+ (1,0) [0|3] "" Vector__XXX
SG_ Aft2NOxAdsorberDesulfationStat : 2|2@1+ (1,0) [0|3] "" Vector__XXX

BO_ 2566712574 AFT1NAI: 8 Vector__XXX
SG_ Aftrtrtmnt1NOxAdsorberRegenStat : 0|2@1+ (1,0) [0|3] "" Vector__XXX
SG_ Aft1NOxAdsorberDesulfationStat : 2|2@1+ (1,0) [0|3] "" Vector__XXX

BO_ 2566712830 AT2WUDOC: 8 Vector__XXX
SG_ Aft2WarmUpDslOxidtnCtlystIntkTmp : 0|16@1+ (0.03125,-273) [-273|1734.96875] "deg C" Vector__XXX
SG_ Aft2WarmUpDslOxidtnCtlystOtltTmp : 16|16@1+ (0.03125,-273) [-273|1734.96875] "deg C" Vector__XXX

BO_ 2499604222 LLRE: 8 Vector__XXX
SG_ BladeElevationDeviationLeft : 0|16@1+ (1,-32000) [-32000|32255] "mm" Vector__XXX
SG_ BladeElevationDeviationRight : 16|16@1+ (1,-32000) [-32000|32255] "mm" Vector__XXX
SG_ BldReferenceElevationOffsetLeft : 32|16@1+ (1,-32000) [-32000|32255] "mm" Vector__XXX
SG_ BldReferenceElevationOffsetRight : 48|16@1+ (1,-32000) [-32000|32255] "mm" Vector__XXX

BO_ 2499604478 EFL_P11: 8 Vector__XXX
SG_ EngExhstGasRecirc1IntkAbsPress : 0|16@1+ (0.1,0) [0|6425.5] "kPa" Vector__XXX
SG_ EngExhstGasRecirc1OtltAbsPress : 16|16@1+ (0.1,0) [0|6425.5] "kPa" Vector__XXX
SG_ EngineOilPressure : 32|16@1+ (0.1,0) [0|6425.5] "kPa" Vector__XXX
SG_ EngineFuelDeliveryPressure : 48|16@1+ (0.1,0) [0|6425.5] "kPa" Vector__XXX

BO_ 2566713598 EFS2: 8 Vector__XXX
SG_ EngFuelFilterIntakeAbsPressure : 0|8@1+ (2,0) [0|500] "kPa" Vector__XXX
SG_ EngineFuelFilterDegradation : 8|8@1+ (1,0) [0|250] "%" Vector__XXX
SG_ FuelTankTransferPump : 16|2@1+ (1,0) [0|3] "" Vector__XXX
SG_ FuelTankTransferPumpPressure : 24|16@1+ (0.1,0) [0|6425.5] "kPa" Vector__XXX

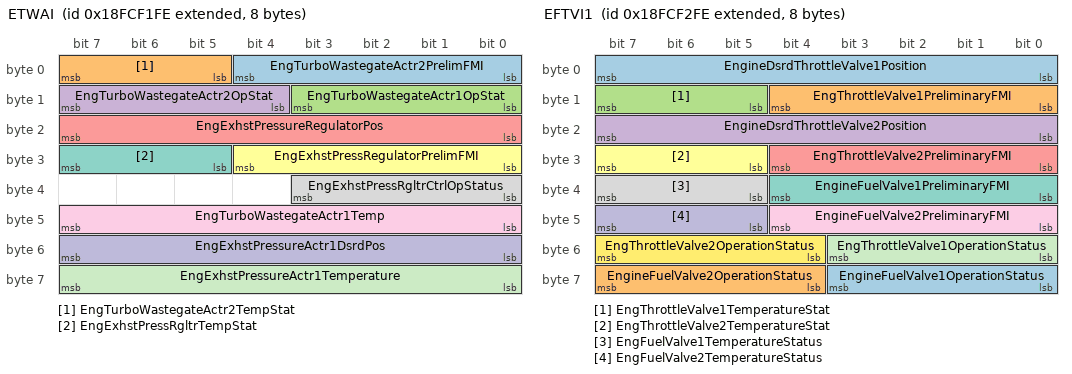
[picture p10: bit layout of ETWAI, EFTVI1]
BO_ 2566713854 ETWAI: 8 Vector__XXX
SG_ EngTurboWastegateActr2PrelimFMI : 0|5@1+ (1,0) [0|31] "" Vector__XXX
SG_ EngTurboWastegateActr2TempStat : 5|3@1+ (1,0) [0|7] "" Vector__XXX
SG_ EngTurboWastegateActr1OpStat : 8|4@1+ (1,0) [0|15] "" Vector__XXX
SG_ EngTurboWastegateActr2OpStat : 12|4@1+ (1,0) [0|15] "" Vector__XXX
SG_ EngExhstPressureRegulatorPos : 16|8@1+ (0.4,0) [0|100] "%" Vector__XXX
SG_ EngExhstPressRegulatorPrelimFMI : 24|5@1+ (1,0) [0|31] "" Vector__XXX
SG_ EngExhstPressRgltrTempStat : 29|3@1+ (1,0) [0|7] "" Vector__XXX
SG_ EngExhstPressRgltrCtrlOpStatus : 32|4@1+ (1,0) [0|15] "" Vector__XXX
SG_ EngTurboWastegateActr1Temp : 40|8@1+ (1,-40) [-40|210] "deg C" Vector__XXX
SG_ EngExhstPressureActr1DsrdPos : 48|8@1+ (0.4,0) [0|100] "%" Vector__XXX
SG_ EngExhstPressureActr1Temperature : 56|8@1+ (1,-40) [-40|210] "deg C" Vector__XXX

BO_ 2566714110 EFTVI1: 8 Vector__XXX
SG_ EngineDsrdThrottleValve1Position : 0|8@1+ (0.4,0) [0|100] "%" Vector__XXX
SG_ EngThrottleValve1PreliminaryFMI : 8|5@1+ (1,0) [0|31] "" Vector__XXX
SG_ EngThrottleValve1TemperatureStat : 13|3@1+ (1,0) [0|7] "" Vector__XXX
SG_ EngineDsrdThrottleValve2Position : 16|8@1+ (0.4,0) [0|100] "%" Vector__XXX
SG_ EngThrottleValve2PreliminaryFMI : 24|5@1+ (1,0) [0|31] "" Vector__XXX
SG_ EngThrottleValve2TemperatureStat : 29|3@1+ (1,0) [0|7] "" Vector__XXX
SG_ EngineFuelValve1PreliminaryFMI : 32|5@1+ (1,0) [0|31] "" Vector__XXX
SG_ EngFuelValve1TemperatureStatus : 37|3@1+ (1,0) [0|7] "" Vector__XXX
SG_ EngineFuelValve2PreliminaryFMI : 40|5@1+ (1,0) [0|31] "" Vector__XXX
SG_ EngFuelValve2TemperatureStatus : 45|3@1+ (1,0) [0|7] "" Vector__XXX
SG_ EngThrottleValve1OperationStatus : 48|4@1+ (1,0) [0|15] "" Vector__XXX
SG_ EngThrottleValve2OperationStatus : 52|4@1+ (1,0) [0|15] "" Vector__XXX
SG_ EngineFuelValve1OperationStatus : 56|4@1+ (1,0) [0|15] "" Vector__XXX
SG_ EngineFuelValve2OperationStatus : 60|4@1+ (1,0) [0|15] "" Vector__XXX

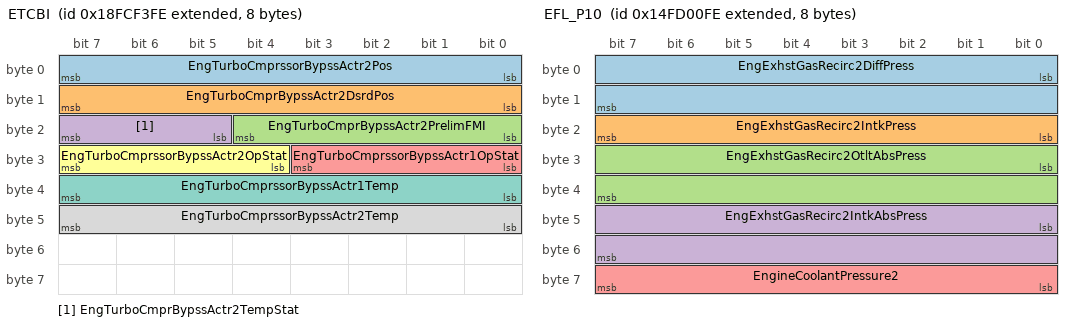
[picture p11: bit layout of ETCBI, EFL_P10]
BO_ 2566714366 ETCBI: 8 Vector__XXX
SG_ EngTurboCmprssorBypssActr2Pos : 0|8@1+ (0.4,0) [0|100] "%" Vector__XXX
SG_ EngTurboCmprBypssActr2DsrdPos : 8|8@1+ (0.4,0) [0|100] "%" Vector__XXX
SG_ EngTurboCmprBypssActr2PrelimFMI : 16|5@1+ (1,0) [0|31] "" Vector__XXX
SG_ EngTurboCmprBypssActr2TempStat : 21|3@1+ (1,0) [0|7] "" Vector__XXX
SG_ EngTurboCmprssorBypssActr1OpStat : 24|4@1+ (1,0) [0|15] "" Vector__XXX
SG_ EngTurboCmprssorBypssActr2OpStat : 28|4@1+ (1,0) [0|15] "" Vector__XXX
SG_ EngTurboCmprssorBypssActr1Temp : 32|8@1+ (1,-40) [-40|210] "deg C" Vector__XXX
SG_ EngTurboCmprssorBypssActr2Temp : 40|8@1+ (1,-40) [-40|210] "deg C" Vector__XXX

BO_ 2566714622 CAC2: 8 Vector__XXX
SG_ EngChargeAirCool2IntkTemperature : 0|16@1+ (0.03125,-273) [-273|1734.96875] "deg C" Vector__XXX
SG_ EngChargeAirCool2OtltTemperature : 16|16@1+ (0.03125,-273) [-273|1734.96875] "deg C" Vector__XXX
SG_ EngChargeAirCool2AmbientAirTemp : 32|16@1+ (0.03125,-273) [-273|1734.96875] "deg C" Vector__XXX
SG_ EngineChargeAirCooler2Efficiency : 48|8@1+ (0.4,0) [0|100] "%" Vector__XXX

BO_ 2566714878 CAC2P: 8 Vector__XXX
SG_ EngChargeAirCool2PreCoolIntkTemp : 0|16@1+ (0.03125,-273) [-273|1734.96875] "deg C" Vector__XXX
SG_ EngChargeAirCool2PreCoolOtltTemp : 16|16@1+ (0.03125,-273) [-273|1734.96875] "deg C" Vector__XXX
SG_ EngineChargeAirCool2PreCoolEff : 32|8@1+ (0.4,0) [0|100] "%" Vector__XXX

BO_ 2566715134 CAC1: 8 Vector__XXX
SG_ EngChargeAirCool1IntkTemperature : 0|16@1+ (0.03125,-273) [-273|1734.96875] "deg C" Vector__XXX
SG_ EngChargeAirCool1AmbientAirTemp : 16|16@1+ (0.03125,-273) [-273|1734.96875] "deg C" Vector__XXX
SG_ EngineChargeAirCooler1Efficiency : 32|8@1+ (0.4,0) [0|100] "%" Vector__XXX

BO_ 2566715390 CAC1P: 8 Vector__XXX
SG_ EngChargeAirCool1PreCoolIntkTemp : 0|16@1+ (0.03125,-273) [-273|1734.96875] "deg C" Vector__XXX
SG_ EngChargeAirCool1PreCoolOtltTemp : 16|16@1+ (0.03125,-273) [-273|1734.96875] "deg C" Vector__XXX
SG_ EngineChargeAirCool1PreCoolEff : 32|8@1+ (0.4,0) [0|100] "%" Vector__XXX

BO_ 2566715646 DPF2S2: 8 Vector__XXX
SG_ Aftrtrtmnt2DslPFSootSigStdDviat : 0|16@1+ (0.0025,0) [0|160.6375] "%" Vector__XXX
SG_ Aftrtrtmnt2DslPFSootSignalMax : 16|16@1+ (0.0025,0) [0|160.6375] "%" Vector__XXX
SG_ Aftrtrtmnt2DslPFSootSignalMin : 32|16@1+ (0.0025,0) [0|160.6375] "%" Vector__XXX

BO_ 2566715902 DPF1S2: 8 Vector__XXX
SG_ Aftrtrtmnt1DslPFSootSigStdDviat : 0|16@1+ (0.0025,0) [0|160.6375] "%" Vector__XXX
SG_ Aftrtrtmnt1DslPFSootSignalMax : 16|16@1+ (0.0025,0) [0|160.6375] "%" Vector__XXX
SG_ Aftrtrtmnt1DslPFSootSignalMin : 32|16@1+ (0.0025,0) [0|160.6375] "%" Vector__XXX

BO_ 2633825022 EEC11: 8 Vector__XXX
SG_ EngExhstGasRecirc2Valve1Ctrl : 0|16@1+ (0.0025,0) [0|160.6375] "%" Vector__XXX
SG_ EngExhstGasRecirc2Valve2Ctrl : 16|16@1+ (0.0025,0) [0|160.6375] "%" Vector__XXX
SG_ EngExhstGasRecirc2Valve1PosError : 32|16@1+ (0.004,-125) [-125|132.02] "%" Vector__XXX
SG_ EngExhstGasRecirc2Valve2PosError : 48|16@1+ (0.004,-125) [-125|132.02] "%" Vector__XXX

BO_ 2499607550 EMAP: 8 Vector__XXX
SG_ EngExhstMnfldBnk1FlwBalVlvActrPs : 0|16@1+ (0.0025,0) [0|160.6375] "%" Vector__XXX
SG_ EngExhstMnfldBnk2FlwBalVlvActrPs : 16|16@1+ (0.0025,0) [0|160.6375] "%" Vector__XXX

BO_ 2633825534 EMAC: 8 Vector__XXX
SG_ EngExhstMfBnk1FlwBalVlvActrCtrl : 0|16@1+ (0.0025,0) [0|160.6375] "%" Vector__XXX
SG_ EngExhstMfBnk2FlwBalVlvActrCtrl : 16|16@1+ (0.0025,0) [0|160.6375] "%" Vector__XXX

BO_ 2432499198 EEC9: 8 Vector__XXX
SG_ EngExhstGasRecirc2ValvePos : 0|16@1+ (0.0025,0) [0|160.6375] "%" Vector__XXX
SG_ EngExhstGasRecirc2Valve2Pos : 16|16@1+ (0.0025,0) [0|160.6375] "%" Vector__XXX
SG_ CommandedEngineFuelRailPressure : 32|16@1+ (0.00390625,0) [0|250.996] "MPa" Vector__XXX
SG_ CmdedEngFuelInjectionCtrlPress : 48|16@1+ (0.00390625,0) [0|250.996] "MPa" Vector__XXX

BO_ 2633826046 EEC10: 8 Vector__XXX
SG_ EngExhstGasRecirc2CoolIntkTemp : 0|16@1+ (0.03125,-273) [-273|1734.96875] "deg C" Vector__XXX
SG_ EngExhstGsRecirc2ClIntkGsAbsPrs : 16|16@1+ (0.5,0) [0|32127.5] "kPa" Vector__XXX
SG_ EngExhstGasRecirculation2CoolEff : 32|8@1+ (0.4,0) [0|100] "%" Vector__XXX
SG_ EngExhstGasRecirc2ClBypssActrPos : 40|8@1+ (0.4,0) [0|100] "%" Vector__XXX

BO_ 2566717438 ET5: 8 Vector__XXX
SG_ EngExhstGasRecirc2Temperature : 0|16@1+ (0.03125,-273) [-273|1734.96875] "deg C" Vector__XXX
SG_ EngExhstGasRecirc2MixerIntkTemp : 16|16@1+ (0.03125,-273) [-273|1734.96875] "deg C" Vector__XXX

BO_ 2499608830 EFL_P10: 8 Vector__XXX
SG_ EngExhstGasRecirc2DiffPress : 0|16@1+ (0.0078125,-250) [-250|251.99] "kPa" Vector__XXX
SG_ EngExhstGasRecirc2IntkPress : 16|8@1+ (2,0) [0|500] "kPa" Vector__XXX
SG_ EngExhstGasRecirc2OtltAbsPress : 24|16@1+ (0.1,0) [0|6425.5] "kPa" Vector__XXX
SG_ EngExhstGasRecirc2IntkAbsPress : 40|16@1+ (0.1,0) [0|6425.5] "kPa" Vector__XXX
SG_ EngineCoolantPressure2 : 56|8@1+ (2,0) [0|500] "kPa" Vector__XXX

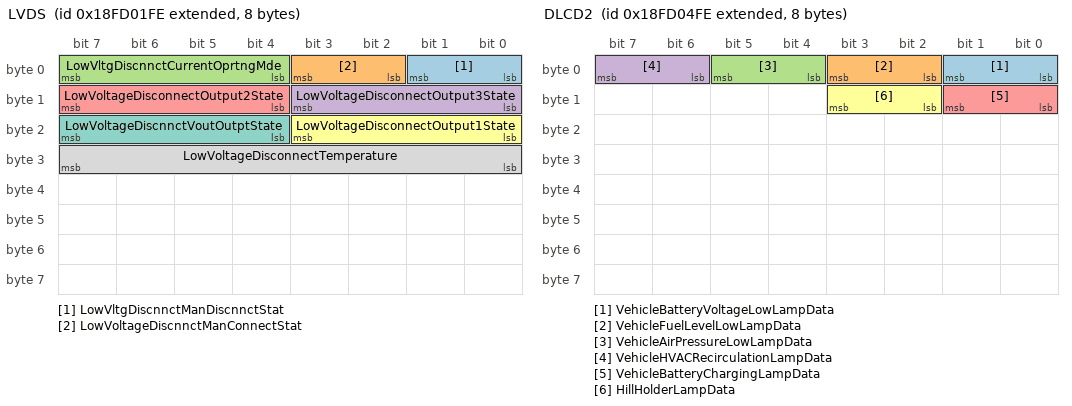
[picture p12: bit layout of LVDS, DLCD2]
BO_ 2566717950 LVDS: 8 Vector__XXX
SG_ LowVltgDiscnnctManDiscnnctStat : 0|2@1+ (1,0) [0|3] "" Vector__XXX
SG_ LowVoltageDiscnnctManConnectStat : 2|2@1+ (1,0) [0|3] "" Vector__XXX
SG_ LowVltgDiscnnctCurrentOprtngMde : 4|4@1+ (1,0) [0|15] "" Vector__XXX
SG_ LowVoltageDisconnectOutput3State : 8|4@1+ (1,0) [0|15] "" Vector__XXX
SG_ LowVoltageDisconnectOutput2State : 12|4@1+ (1,0) [0|15] "" Vector__XXX
SG_ LowVoltageDisconnectOutput1State : 16|4@1+ (1,0) [0|15] "" Vector__XXX
SG_ LowVoltageDiscnnctVoutOutptState : 20|4@1+ (1,0) [0|15] "" Vector__XXX
SG_ LowVoltageDisconnectTemperature : 24|8@1+ (1,-40) [-40|210] "deg C" Vector__XXX

BO_ 2566718718 DLCD2: 8 Vector__XXX
SG_ VehicleBatteryVoltageLowLampData : 0|2@1+ (1,0) [0|3] "" Vector__XXX
SG_ VehicleFuelLevelLowLampData : 2|2@1+ (1,0) [0|3] "" Vector__XXX
SG_ VehicleAirPressureLowLampData : 4|2@1+ (1,0) [0|3] "" Vector__XXX
SG_ VehicleHVACRecirculationLampData : 6|2@1+ (1,0) [0|3] "" Vector__XXX
SG_ VehicleBatteryChargingLampData : 8|2@1+ (1,0) [0|3] "" Vector__XXX
SG_ HillHolderLampData : 10|2@1+ (1,0) [0|3] "" Vector__XXX

BO_ 2566718974 DLCD1: 8 Vector__XXX
SG_ EngineProtectLampData : 0|2@1+ (1,0) [0|3] "" Vector__XXX
SG_ EngineAmberWarningLampData : 2|2@1+ (1,0) [0|3] "" Vector__XXX
SG_ EngineRedStopLampData : 4|2@1+ (1,0) [0|3] "" Vector__XXX
SG_ OBDMalfunctionIndicatorLampData : 6|2@1+ (1,0) [0|3] "" Vector__XXX
SG_ EngineBrakeActiveLampData : 8|2@1+ (1,0) [0|3] "" Vector__XXX
SG_ ComPrsionBrkEnblSwIndictrLampDat : 10|2@1+ (1,0) [0|3] "" Vector__XXX
SG_ EngineOilPressureLowLampData : 12|2@1+ (1,0) [0|3] "" Vector__XXX
SG_ EngCoolntTemperatureHighLampDat : 14|2@1+ (1,0) [0|3] "" Vector__XXX
SG_ EngineCoolantLevelLowLampData : 16|2@1+ (1,0) [0|3] "" Vector__XXX
SG_ EngineIdleManagementActvLampData : 18|2@1+ (1,0) [0|3] "" Vector__XXX
SG_ EngAirFilterRestrictionLampDat : 20|2@1+ (1,0) [0|3] "" Vector__XXX
SG_ EngFuelFilterRestrictedLampDat : 22|2@1+ (1,0) [0|3] "" Vector__XXX
SG_ EngCtrlModule1ReadyForUseLampDat : 24|2@1+ (1,0) [0|3] "" Vector__XXX
SG_ EngCtrlModule2ReadyForUseLampDat : 26|2@1+ (1,0) [0|3] "" Vector__XXX
SG_ EngCtrlModule3ReadyForUseLampDat : 28|2@1+ (1,0) [0|3] "" Vector__XXX
SG_ EngineSpeedHighLampData : 30|2@1+ (1,0) [0|3] "" Vector__XXX
SG_ EngineSpeedVeryHighLampData : 32|2@1+ (1,0) [0|3] "" Vector__XXX
SG_ VehicleAccltnRateLimitLampData : 34|2@1+ (1,0) [0|3] "" Vector__XXX
SG_ EngineWaitToStartLampData : 62|2@1+ (1,0) [0|3] "" Vector__XXX

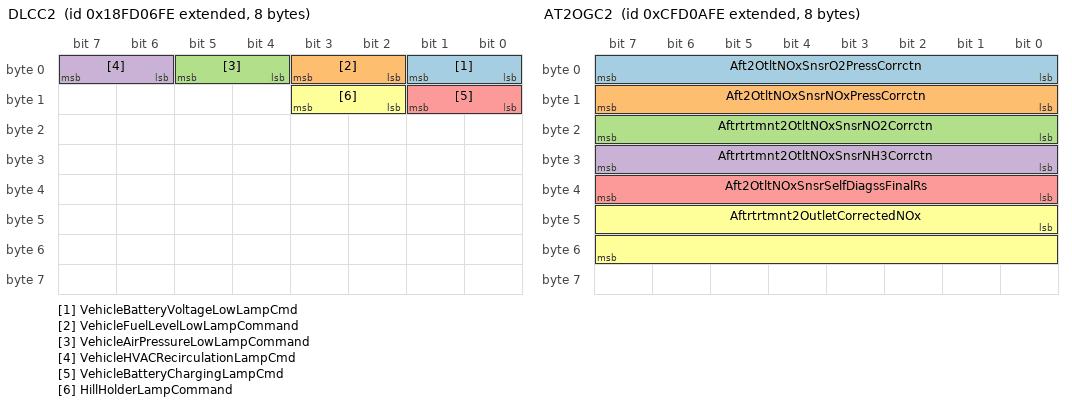
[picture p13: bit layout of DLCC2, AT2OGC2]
BO_ 2566719230 DLCC2: 8 Vector__XXX
SG_ VehicleBatteryVoltageLowLampCmd : 0|2@1+ (1,0) [0|3] "" Vector__XXX
SG_ VehicleFuelLevelLowLampCommand : 2|2@1+ (1,0) [0|3] "" Vector__XXX
SG_ VehicleAirPressureLowLampCommand : 4|2@1+ (1,0) [0|3] "" Vector__XXX
SG_ VehicleHVACRecirculationLampCmd : 6|2@1+ (1,0) [0|3] "" Vector__XXX
SG_ VehicleBatteryChargingLampCmd : 8|2@1+ (1,0) [0|3] "" Vector__XXX
SG_ HillHolderLampCommand : 10|2@1+ (1,0) [0|3] "" Vector__XXX

BO_ 2566719486 DLCC1: 8 Vector__XXX
SG_ EngineProtectLampCommand : 0|2@1+ (1,0) [0|3] "" Vector__XXX
SG_ EngineAmberWarningLampCommand : 2|2@1+ (1,0) [0|3] "" Vector__XXX
SG_ EngineRedStopLampCommand : 4|2@1+ (1,0) [0|3] "" Vector__XXX
SG_ OBDMalfunctionIndicatorLampCmd : 6|2@1+ (1,0) [0|3] "" Vector__XXX
SG_ EngineBrakeActiveLampCommand : 8|2@1+ (1,0) [0|3] "" Vector__XXX
SG_ ComPrsionBrkEnblSwIndictrLampCmd : 10|2@1+ (1,0) [0|3] "" Vector__XXX
SG_ EngineOilPressureLowLampCommand : 12|2@1+ (1,0) [0|3] "" Vector__XXX
SG_ EngCoolntTemperatureHighLampCmd : 14|2@1+ (1,0) [0|3] "" Vector__XXX
SG_ EngineCoolantLevelLowLampCommand : 16|2@1+ (1,0) [0|3] "" Vector__XXX
SG_ EngineIdleManagementActvLampCmd : 18|2@1+ (1,0) [0|3] "" Vector__XXX
SG_ EngAirFilterRestrictionLampCmd : 20|2@1+ (1,0) [0|3] "" Vector__XXX
SG_ EngFuelFilterRestrictedLampCmd : 22|2@1+ (1,0) [0|3] "" Vector__XXX
SG_ EngCtrlModule1ReadyForUseLampCmd : 24|2@1+ (1,0) [0|3] "" Vector__XXX
SG_ EngCtrlModule2ReadyForUseLampCmd : 26|2@1+ (1,0) [0|3] "" Vector__XXX
SG_ EngCtrlModule3ReadyForUseLampCmd : 28|2@1+ (1,0) [0|3] "" Vector__XXX
SG_ EngineSpeedHighLampCommand : 30|2@1+ (1,0) [0|3] "" Vector__XXX
SG_ EngineSpeedVeryHighLampCommand : 32|2@1+ (1,0) [0|3] "" Vector__XXX
SG_ VehicleAccltnRateLimitLampCmd : 34|2@1+ (1,0) [0|3] "" Vector__XXX

BO_ 2633828606 EOM: 8 Vector__XXX
SG_ EngineOilViscosity : 0|16@1+ (0.015625,0) [0|1003.984375] "Cp" Vector__XXX
SG_ EngineOilDensity : 16|16@1+ (3.052E-005,0) [0|1.961] "g/cc" Vector__XXX
SG_ EngineOilRelativeDielectricity : 32|16@1+ (0.0001220703125,0) [0|7.844] "" Vector__XXX
SG_ EngineOilTemperature3 : 48|16@1+ (0.03125,-273) [-273|1734.96875] "deg C" Vector__XXX

BO_ 2566719998 HRLFC: 8 Vector__XXX
SG_ EngineTripFuel : 0|32@1+ (0.001,0) [0|4211081.215] "l" Vector__XXX
SG_ EngineTotalFuelUsed : 32|32@1+ (0.001,0) [0|4211081.215] "l" Vector__XXX

BO_ 2365393662 AT2OGC2: 8 Vector__XXX
SG_ Aft2OtltNOxSnsrO2PressCorrctn : 0|8@1+ (0.5,0) [0|125] "%/bar" Vector__XXX
SG_ Aft2OtltNOxSnsrNOxPressCorrctn : 8|8@1+ (0.5,0) [0|125] "%/bar" Vector__XXX
SG_ Aftrtrtmnt2OtltNOxSnsrNO2Corrctn : 16|8@1+ (0.5,0) [0|125] "%" Vector__XXX
SG_ Aftrtrtmnt2OtltNOxSnsrNH3Corrctn : 24|8@1+ (0.5,0) [0|125] "%" Vector__XXX
SG_ Aft2OtltNOxSnsrSelfDiagssFinalRs : 32|8@1+ (1,0) [0|250] "" Vector__XXX
SG_ Aftrtrtmnt2OutletCorrectedNOx : 40|16@1+ (0.05,-200) [-200|3012.75] "ppm" Vector__XXX

BO_ 2365393918 AT2OGC1: 8 Vector__XXX
SG_ Aftrtrtmnt2OtltNOxSensorHtrRatio : 0|16@1+ (0.001,0) [0|64.255] "" Vector__XXX
SG_ Aft2OtltNOxSnsrNwPrtDviatNOxGain : 16|16@1+ (0.1,-100) [-100|6325.5] "%" Vector__XXX
SG_ Aft2OtltNOxSnsrNPDviatNOxOffst : 32|8@1+ (1,-125) [-125|125] "ppm" Vector__XXX
SG_ Aftrtrtmnt2OtltNOxSensorOpHours : 40|16@1+ (1,0) [0|64255] "h" Vector__XXX

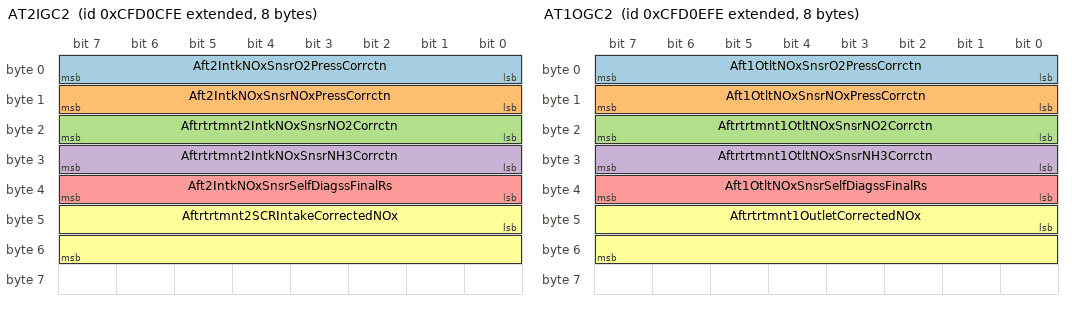
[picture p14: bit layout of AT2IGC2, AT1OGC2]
BO_ 2365394174 AT2IGC2: 8 Vector__XXX
SG_ Aft2IntkNOxSnsrO2PressCorrctn : 0|8@1+ (0.5,0) [0|125] "%/bar" Vector__XXX
SG_ Aft2IntkNOxSnsrNOxPressCorrctn : 8|8@1+ (0.5,0) [0|125] "%/bar" Vector__XXX
SG_ Aftrtrtmnt2IntkNOxSnsrNO2Corrctn : 16|8@1+ (0.5,0) [0|125] "%" Vector__XXX
SG_ Aftrtrtmnt2IntkNOxSnsrNH3Corrctn : 24|8@1+ (0.5,0) [0|125] "%" Vector__XXX
SG_ Aft2IntkNOxSnsrSelfDiagssFinalRs : 32|8@1+ (1,0) [0|250] "" Vector__XXX
SG_ Aftrtrtmnt2SCRIntakeCorrectedNOx : 40|16@1+ (0.05,-200) [-200|3012.75] "ppm" Vector__XXX

BO_ 2365394430 AT2IGC1: 8 Vector__XXX
SG_ Aftrtrtmnt2IntkNOxSensorHtrRatio : 0|16@1+ (0.001,0) [0|64.255] "" Vector__XXX
SG_ Aft2IntkNOxSnsrNwPrtDviatNOxGain : 16|16@1+ (0.1,-100) [-100|6325.5] "%" Vector__XXX
SG_ Aft2IntkNOxSnsrNPDviatNOxOffst : 32|8@1+ (1,-125) [-125|125] "ppm" Vector__XXX
SG_ Aftrtrtmnt2IntkNOxSensorOpHours : 40|16@1+ (1,0) [0|64255] "h" Vector__XXX

BO_ 2365394686 AT1OGC2: 8 Vector__XXX
SG_ Aft1OtltNOxSnsrO2PressCorrctn : 0|8@1+ (0.5,0) [0|125] "%/bar" Vector__XXX
SG_ Aft1OtltNOxSnsrNOxPressCorrctn : 8|8@1+ (0.5,0) [0|125] "%/bar" Vector__XXX
SG_ Aftrtrtmnt1OtltNOxSnsrNO2Corrctn : 16|8@1+ (0.5,0) [0|125] "%" Vector__XXX
SG_ Aftrtrtmnt1OtltNOxSnsrNH3Corrctn : 24|8@1+ (0.5,0) [0|125] "%" Vector__XXX
SG_ Aft1OtltNOxSnsrSelfDiagssFinalRs : 32|8@1+ (1,0) [0|250] "" Vector__XXX
SG_ Aftrtrtmnt1OutletCorrectedNOx : 40|16@1+ (0.05,-200) [-200|3012.75] "ppm" Vector__XXX

BO_ 2365394942 AT1OGC1: 8 Vector__XXX
SG_ Aftrtrtmnt1OtltNOxSensorHtrRatio : 0|16@1+ (0.001,0) [0|64.255] "" Vector__XXX
SG_ Aft1OtltNOxSnsrNwPrtDviatNOxGain : 16|16@1+ (0.1,-100) [-100|6325.5] "%" Vector__XXX
SG_ Aft1OtltNOxSnsrNPDviatNOxOffst : 32|8@1+ (1,-125) [-125|125] "ppm" Vector__XXX
SG_ Aftrtrtmnt1OtltNOxSensorOpHours : 40|16@1+ (1,0) [0|64255] "h" Vector__XXX

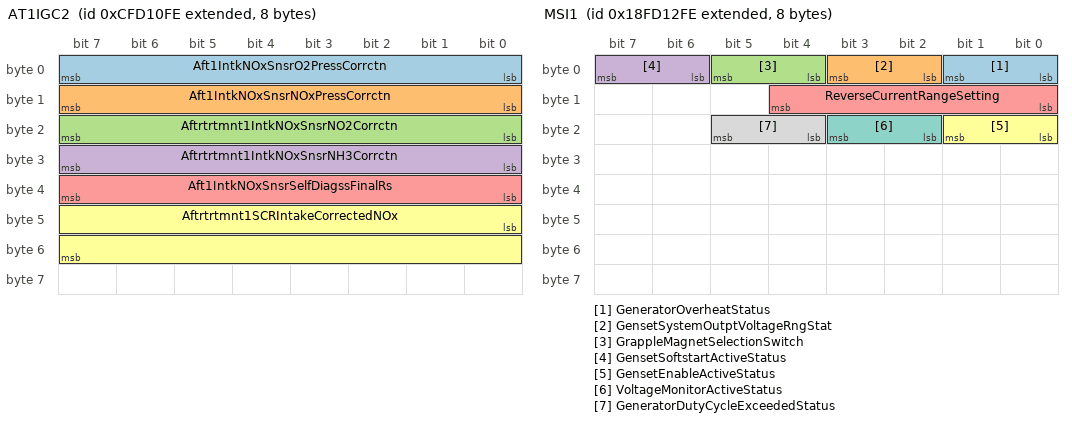
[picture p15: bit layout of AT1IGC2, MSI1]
BO_ 2365395198 AT1IGC2: 8 Vector__XXX
SG_ Aft1IntkNOxSnsrO2PressCorrctn : 0|8@1+ (0.5,0) [0|125] "%/bar" Vector__XXX
SG_ Aft1IntkNOxSnsrNOxPressCorrctn : 8|8@1+ (0.5,0) [0|125] "%/bar" Vector__XXX
SG_ Aftrtrtmnt1IntkNOxSnsrNO2Corrctn : 16|8@1+ (0.5,0) [0|125] "%" Vector__XXX
SG_ Aftrtrtmnt1IntkNOxSnsrNH3Corrctn : 24|8@1+ (0.5,0) [0|125] "%" Vector__XXX
SG_ Aft1IntkNOxSnsrSelfDiagssFinalRs : 32|8@1+ (1,0) [0|250] "" Vector__XXX
SG_ Aftrtrtmnt1SCRIntakeCorrectedNOx : 40|16@1+ (0.05,-200) [-200|3012.75] "ppm" Vector__XXX

BO_ 2365395454 AT1IGC1: 8 Vector__XXX
SG_ Aftrtrtmnt1IntkNOxSensorHtrRatio : 0|16@1+ (0.001,0) [0|64.255] "" Vector__XXX
SG_ Aft1IntkNOxSnsrNwPrtDviatNOxGain : 16|16@1+ (0.1,-100) [-100|6325.5] "%" Vector__XXX
SG_ Aft1IntkNOxSnsrNPDviatNOxOffst : 32|8@1+ (1,-125) [-125|125] "ppm" Vector__XXX
SG_ Aftrtrtmnt1IntkNOxSensorOpHours : 40|16@1+ (1,0) [0|64255] "h" Vector__XXX

BO_ 2566722302 MSI1: 8 Vector__XXX
SG_ GeneratorOverheatStatus : 0|2@1+ (1,0) [0|3] "" Vector__XXX
SG_ GensetSystemOutptVoltageRngStat : 2|2@1+ (1,0) [0|3] "" Vector__XXX
SG_ GrappleMagnetSelectionSwitch : 4|2@1+ (1,0) [0|3] "" Vector__XXX
SG_ GensetSoftstartActiveStatus : 6|2@1+ (1,0) [0|3] "" Vector__XXX
SG_ ReverseCurrentRangeSetting : 8|5@1+ (1,0) [0|31] "" Vector__XXX
SG_ GensetEnableActiveStatus : 16|2@1+ (1,0) [0|3] "" Vector__XXX
SG_ VoltageMonitorActiveStatus : 18|2@1+ (1,0) [0|3] "" Vector__XXX
SG_ GeneratorDutyCycleExceededStatus : 20|2@1+ (1,0) [0|3] "" Vector__XXX

BO_ 2566722558 MSCI: 8 Vector__XXX
SG_ MagnetBoostTime : 0|8@1+ (0.25,0) [0|62.5] "s" Vector__XXX
SG_ MagnetRatedPower : 8|16@1+ (0.5,0) [0|32127.5] "kW" Vector__XXX

BO_ 2566722814 BCH2: 8 Vector__XXX
SG_ BatteryCharger2State : 0|4@1+ (1,0) [0|15] "" Vector__XXX
SG_ BatteryCharger2PowerLineState : 4|2@1+ (1,0) [0|3] "" Vector__XXX
SG_ BatteryCharger2OutputVoltage : 8|16@1+ (0.05,0) [0|3212.75] "V" Vector__XXX
SG_ BatteryCharger2OutputCurrent : 24|16@1+ (0.05,-1600) [-1600|1612.75] "A" Vector__XXX

BO_ 2566723070 BCH1: 8 Vector__XXX
SG_ BatteryCharger1State : 0|4@1+ (1,0) [0|15] "" Vector__XXX
SG_ BatteryCharger1PowerLineState : 4|2@1+ (1,0) [0|3] "" Vector__XXX
SG_ BatteryCharger1OutputVoltage : 8|16@1+ (0.05,0) [0|3212.75] "V" Vector__XXX
SG_ BatteryCharger1OutputCurrent : 24|16@1+ (0.05,-1600) [-1600|1612.75] "A" Vector__XXX

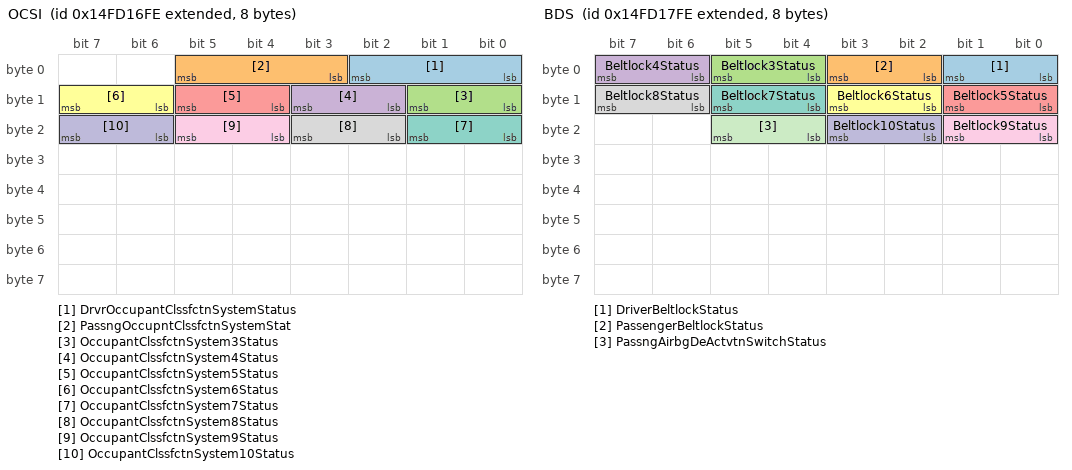
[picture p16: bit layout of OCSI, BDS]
BO_ 2499614462 OCSI: 8 Vector__XXX
SG_ DrvrOccupantClssfctnSystemStatus : 0|3@1+ (1,0) [0|7] "" Vector__XXX
SG_ PassngOccupntClssfctnSystemStat : 3|3@1+ (1,0) [0|7] "" Vector__XXX
SG_ OccupantClssfctnSystem3Status : 8|2@1+ (1,0) [0|3] "" Vector__XXX
SG_ OccupantClssfctnSystem4Status : 10|2@1+ (1,0) [0|3] "" Vector__XXX
SG_ OccupantClssfctnSystem5Status : 12|2@1+ (1,0) [0|3] "" Vector__XXX
SG_ OccupantClssfctnSystem6Status : 14|2@1+ (1,0) [0|3] "" Vector__XXX
SG_ OccupantClssfctnSystem7Status : 16|2@1+ (1,0) [0|3] "" Vector__XXX
SG_ OccupantClssfctnSystem8Status : 18|2@1+ (1,0) [0|3] "" Vector__XXX
SG_ OccupantClssfctnSystem9Status : 20|2@1+ (1,0) [0|3] "" Vector__XXX
SG_ OccupantClssfctnSystem10Status : 22|2@1+ (1,0) [0|3] "" Vector__XXX

BO_ 2499614718 BDS: 8 Vector__XXX
SG_ DriverBeltlockStatus : 0|2@1+ (1,0) [0|3] "" Vector__XXX
SG_ PassengerBeltlockStatus : 2|2@1+ (1,0) [0|3] "" Vector__XXX
SG_ Beltlock3Status : 4|2@1+ (1,0) [0|3] "" Vector__XXX
SG_ Beltlock4Status : 6|2@1+ (1,0) [0|3] "" Vector__XXX
SG_ Beltlock5Status : 8|2@1+ (1,0) [0|3] "" Vector__XXX
SG_ Beltlock6Status : 10|2@1+ (1,0) [0|3] "" Vector__XXX
SG_ Beltlock7Status : 12|2@1+ (1,0) [0|3] "" Vector__XXX
SG_ Beltlock8Status : 14|2@1+ (1,0) [0|3] "" Vector__XXX
SG_ Beltlock9Status : 16|2@1+ (1,0) [0|3] "" Vector__XXX
SG_ Beltlock10Status : 18|2@1+ (1,0) [0|3] "" Vector__XXX
SG_ PassngAirbgDeActvtnSwitchStatus : 20|2@1+ (1,0) [0|3] "" Vector__XXX

BO_ 2633832702 CSI: 9 Vector__XXX
SG_ FrontalCollisionSensor1Type : 0|4@1+ (1,0) [0|15] "" Vector__XXX
SG_ FrontalCollisionSensor2Type : 4|4@1+ (1,0) [0|15] "" Vector__XXX
SG_ FrontalCollisionSensor3Type : 8|4@1+ (1,0) [0|15] "" Vector__XXX
SG_ FrontalCollisionSensor4Type : 12|4@1+ (1,0) [0|15] "" Vector__XXX
SG_ SideCollisionSensorFrontLeftType : 16|4@1+ (1,0) [0|15] "" Vector__XXX
SG_ SideCollsnSensorMidFrontLeftType : 20|4@1+ (1,0) [0|15] "" Vector__XXX
SG_ SideCollsnSensorMidRearLeftType : 24|4@1+ (1,0) [0|15] "" Vector__XXX
SG_ SideCollisionSensorRearLeftType : 28|4@1+ (1,0) [0|15] "" Vector__XXX
SG_ SideCollsnSensorFrontRightType : 32|4@1+ (1,0) [0|15] "" Vector__XXX
SG_ SideCollsnSensorMidFrntRightType : 36|4@1+ (1,0) [0|15] "" Vector__XXX
SG_ SideCollsnSensorMidRearRightType : 40|4@1+ (1,0) [0|15] "" Vector__XXX
SG_ SideCollisionSensorRearRightType : 44|4@1+ (1,0) [0|15] "" Vector__XXX
SG_ RearCollisionSensor1Type : 48|4@1+ (1,0) [0|15] "" Vector__XXX
SG_ RearCollisionSensor2Type : 52|4@1+ (1,0) [0|15] "" Vector__XXX
SG_ RearCollisionSensor3Type : 56|4@1+ (1,0) [0|15] "" Vector__XXX
SG_ RearCollisionSensor4Type : 60|4@1+ (1,0) [0|15] "" Vector__XXX
SG_ RolloverSensorType : 64|4@1+ (1,0) [0|15] "" Vector__XXX

BO_ 2633832958 ILI: 200 Vector__XXX
SG_ DrvrAirbgIgntrLp1stStageResist : 0|16@1+ (0.1,0) [0|6425.5] "ohm" Vector__XXX
SG_ PassngAirbgIgntrLp1stStageResist : 16|16@1+ (0.1,0) [0|6425.5] "ohm" Vector__XXX
SG_ DrvrAirbgIgntrLp2ndStageResist : 32|16@1+ (0.1,0) [0|6425.5] "ohm" Vector__XXX
SG_ PassngAirbgIgntrLp2ndStageResist : 48|16@1+ (0.1,0) [0|6425.5] "ohm" Vector__XXX
SG_ DrvrBeltTensionerIgntrLpResist : 64|16@1+ (0.1,0) [0|6425.5] "ohm" Vector__XXX
SG_ PassngBeltTensionerIgntrLpResist : 80|16@1+ (0.1,0) [0|6425.5] "ohm" Vector__XXX
SG_ SideBagIgntrLoop1LeftResistance : 96|16@1+ (0.1,0) [0|6425.5] "ohm" Vector__XXX
SG_ SideBagIgntrLoop2LeftResistance : 112|16@1+ (0.1,0) [0|6425.5] "ohm" Vector__XXX
SG_ SideBagIgntrLoop1RightResistance : 128|16@1+ (0.1,0) [0|6425.5] "ohm" Vector__XXX
SG_ SideBagIgntrLoop2RightResistance : 144|16@1+ (0.1,0) [0|6425.5] "ohm" Vector__XXX
SG_ SpecialIgnitorLoop1Resistance : 160|16@1+ (0.1,0) [0|6425.5] "ohm" Vector__XXX
SG_ SpecialIgnitorLoop2Resistance : 176|16@1+ (0.1,0) [0|6425.5] "ohm" Vector__XXX
SG_ SpecialIgnitorLoop3Resistance : 192|16@1+ (0.1,0) [0|6425.5] "ohm" Vector__XXX
SG_ SpecialIgnitorLoop4Resistance : 208|16@1+ (0.1,0) [0|6425.5] "ohm" Vector__XXX
SG_ SpecialIgnitorLoop5Resistance : 224|16@1+ (0.1,0) [0|6425.5] "ohm" Vector__XXX
SG_ SpecialIgnitorLoop6Resistance : 240|16@1+ (0.1,0) [0|6425.5] "ohm" Vector__XXX
SG_ SpecialIgnitorLoop7Resistance : 256|16@1+ (0.1,0) [0|6425.5] "ohm" Vector__XXX
SG_ SpecialIgnitorLoop8Resistance : 272|16@1+ (0.1,0) [0|6425.5] "ohm" Vector__XXX
SG_ SpecialIgnitorLoop9Resistance : 288|16@1+ (0.1,0) [0|6425.5] "ohm" Vector__XXX
SG_ SpecialIgnitorLoop10Resistance : 304|16@1+ (0.1,0) [0|6425.5] "ohm" Vector__XXX
SG_ SpecialIgnitorLoop11Resistance : 320|16@1+ (0.1,0) [0|6425.5] "ohm" Vector__XXX
SG_ SpecialIgnitorLoop12Resistance : 336|16@1+ (0.1,0) [0|6425.5] "ohm" Vector__XXX
SG_ SpecialIgnitorLoop13Resistance : 352|16@1+ (0.1,0) [0|6425.5] "ohm" Vector__XXX
SG_ SpecialIgnitorLoop14Resistance : 368|16@1+ (0.1,0) [0|6425.5] "ohm" Vector__XXX
SG_ SpecialIgnitorLoop15Resistance : 384|16@1+ (0.1,0) [0|6425.5] "ohm" Vector__XXX
SG_ SpecialIgnitorLoop16Resistance : 400|16@1+ (0.1,0) [0|6425.5] "ohm" Vector__XXX
SG_ SpecialIgnitorLoop17Resistance : 416|16@1+ (0.1,0) [0|6425.5] "ohm" Vector__XXX
SG_ SpecialIgnitorLoop18Resistance : 432|16@1+ (0.1,0) [0|6425.5] "ohm" Vector__XXX
SG_ SpecialIgnitorLoop19Resistance : 448|16@1+ (0.1,0) [0|6425.5] "ohm" Vector__XXX
SG_ SpecialIgnitorLoop20Resistance : 464|16@1+ (0.1,0) [0|6425.5] "ohm" Vector__XXX
SG_ SpecialIgnitorLoop21Resistance : 480|16@1+ (0.1,0) [0|6425.5] "ohm" Vector__XXX
SG_ SpecialIgnitorLoop22Resistance : 496|16@1+ (0.1,0) [0|6425.5] "ohm" Vector__XXX
SG_ SpecialIgnitorLoop23Resistance : 512|16@1+ (0.1,0) [0|6425.5] "ohm" Vector__XXX
SG_ SpecialIgnitorLoop24Resistance : 528|16@1+ (0.1,0) [0|6425.5] "ohm" Vector__XXX
SG_ SpecialIgnitorLoop25Resistance : 544|16@1+ (0.1,0) [0|6425.5] "ohm" Vector__XXX
SG_ SpecialIgnitorLoop26Resistance : 560|16@1+ (0.1,0) [0|6425.5] "ohm" Vector__XXX
SG_ SpecialIgnitorLoop27Resistance : 576|16@1+ (0.1,0) [0|6425.5] "ohm" Vector__XXX
SG_ SpecialIgnitorLoop28Resistance : 592|16@1+ (0.1,0) [0|6425.5] "ohm" Vector__XXX
SG_ SpecialIgnitorLoop29Resistance : 608|16@1+ (0.1,0) [0|6425.5] "ohm" Vector__XXX
SG_ SpecialIgnitorLoop30Resistance : 624|16@1+ (0.1,0) [0|6425.5] "ohm" Vector__XXX
SG_ SpecialIgnitorLoop31Resistance : 640|16@1+ (0.1,0) [0|6425.5] "ohm" Vector__XXX
SG_ SpecialIgnitorLoop32Resistance : 656|16@1+ (0.1,0) [0|6425.5] "ohm" Vector__XXX
SG_ SpecialIgnitorLoop33Resistance : 672|16@1+ (0.1,0) [0|6425.5] "ohm" Vector__XXX
SG_ SpecialIgnitorLoop34Resistance : 688|16@1+ (0.1,0) [0|6425.5] "ohm" Vector__XXX
SG_ SpecialIgnitorLoop35Resistance : 704|16@1+ (0.1,0) [0|6425.5] "ohm" Vector__XXX
SG_ SpecialIgnitorLoop36Resistance : 720|16@1+ (0.1,0) [0|6425.5] "ohm" Vector__XXX
SG_ SpecialIgnitorLoop37Resistance : 736|16@1+ (0.1,0) [0|6425.5] "ohm" Vector__XXX
SG_ SpecialIgnitorLoop38Resistance : 752|16@1+ (0.1,0) [0|6425.5] "ohm" Vector__XXX
SG_ SpecialIgnitorLoop39Resistance : 768|16@1+ (0.1,0) [0|6425.5] "ohm" Vector__XXX
SG_ SpecialIgnitorLoop40Resistance : 784|16@1+ (0.1,0) [0|6425.5] "ohm" Vector__XXX
SG_ SpecialIgnitorLoop41Resistance : 800|16@1+ (0.1,0) [0|6425.5] "ohm" Vector__XXX
SG_ SpecialIgnitorLoop42Resistance : 816|16@1+ (0.1,0) [0|6425.5] "ohm" Vector__XXX
SG_ SpecialIgnitorLoop43Resistance : 832|16@1+ (0.1,0) [0|6425.5] "ohm" Vector__XXX
SG_ SpecialIgnitorLoop44Resistance : 848|16@1+ (0.1,0) [0|6425.5] "ohm" Vector__XXX
SG_ SpecialIgnitorLoop45Resistance : 864|16@1+ (0.1,0) [0|6425.5] "ohm" Vector__XXX
SG_ SpecialIgnitorLoop46Resistance : 880|16@1+ (0.1,0) [0|6425.5] "ohm" Vector__XXX
SG_ SpecialIgnitorLoop47Resistance : 896|16@1+ (0.1,0) [0|6425.5] "ohm" Vector__XXX
SG_ SpecialIgnitorLoop48Resistance : 912|16@1+ (0.1,0) [0|6425.5] "ohm" Vector__XXX
SG_ SpecialIgnitorLoop49Resistance : 928|16@1+ (0.1,0) [0|6425.5] "ohm" Vector__XXX
SG_ SpecialIgnitorLoop50Resistance : 944|16@1+ (0.1,0) [0|6425.5] "ohm" Vector__XXX
SG_ SpecialIgnitorLoop51Resistance : 960|16@1+ (0.1,0) [0|6425.5] "ohm" Vector__XXX
SG_ SpecialIgnitorLoop52Resistance : 976|16@1+ (0.1,0) [0|6425.5] "ohm" Vector__XXX
SG_ SpecialIgnitorLoop53Resistance : 992|16@1+ (0.1,0) [0|6425.5] "ohm" Vector__XXX
SG_ SpecialIgnitorLoop54Resistance : 1008|16@1+ (0.1,0) [0|6425.5] "ohm" Vector__XXX
SG_ SpecialIgnitorLoop55Resistance : 1024|16@1+ (0.1,0) [0|6425.5] "ohm" Vector__XXX
SG_ SpecialIgnitorLoop56Resistance : 1040|16@1+ (0.1,0) [0|6425.5] "ohm" Vector__XXX
SG_ SpecialIgnitorLoop57Resistance : 1056|16@1+ (0.1,0) [0|6425.5] "ohm" Vector__XXX
SG_ SpecialIgnitorLoop58Resistance : 1072|16@1+ (0.1,0) [0|6425.5] "ohm" Vector__XXX
SG_ SpecialIgnitorLoop59Resistance : 1088|16@1+ (0.1,0) [0|6425.5] "ohm" Vector__XXX
SG_ SpecialIgnitorLoop60Resistance : 1104|16@1+ (0.1,0) [0|6425.5] "ohm" Vector__XXX
SG_ SpecialIgnitorLoop61Resistance : 1120|16@1+ (0.1,0) [0|6425.5] "ohm" Vector__XXX
SG_ SpecialIgnitorLoop62Resistance : 1136|16@1+ (0.1,0) [0|6425.5] "ohm" Vector__XXX
SG_ SpecialIgnitorLoop63Resistance : 1152|16@1+ (0.1,0) [0|6425.5] "ohm" Vector__XXX
SG_ SpecialIgnitorLoop64Resistance : 1168|16@1+ (0.1,0) [0|6425.5] "ohm" Vector__XXX
SG_ SpecialIgnitorLoop65Resistance : 1184|16@1+ (0.1,0) [0|6425.5] "ohm" Vector__XXX
SG_ SpecialIgnitorLoop66Resistance : 1200|16@1+ (0.1,0) [0|6425.5] "ohm" Vector__XXX
SG_ SpecialIgnitorLoop67Resistance : 1216|16@1+ (0.1,0) [0|6425.5] "ohm" Vector__XXX
SG_ SpecialIgnitorLoop68Resistance : 1232|16@1+ (0.1,0) [0|6425.5] "ohm" Vector__XXX
SG_ SpecialIgnitorLoop69Resistance : 1248|16@1+ (0.1,0) [0|6425.5] "ohm" Vector__XXX
SG_ SpecialIgnitorLoop70Resistance : 1264|16@1+ (0.1,0) [0|6425.5] "ohm" Vector__XXX
SG_ SpecialIgnitorLoop71Resistance : 1280|16@1+ (0.1,0) [0|6425.5] "ohm" Vector__XXX
SG_ SpecialIgnitorLoop72Resistance : 1296|16@1+ (0.1,0) [0|6425.5] "ohm" Vector__XXX
SG_ SpecialIgnitorLoop73Resistance : 1312|16@1+ (0.1,0) [0|6425.5] "ohm" Vector__XXX
SG_ SpecialIgnitorLoop74Resistance : 1328|16@1+ (0.1,0) [0|6425.5] "ohm" Vector__XXX
SG_ SpecialIgnitorLoop75Resistance : 1344|16@1+ (0.1,0) [0|6425.5] "ohm" Vector__XXX
SG_ SpecialIgnitorLoop76Resistance : 1360|16@1+ (0.1,0) [0|6425.5] "ohm" Vector__XXX
SG_ SpecialIgnitorLoop77Resistance : 1376|16@1+ (0.1,0) [0|6425.5] "ohm" Vector__XXX
SG_ SpecialIgnitorLoop78Resistance : 1392|16@1+ (0.1,0) [0|6425.5] "ohm" Vector__XXX
SG_ SpecialIgnitorLoop79Resistance : 1408|16@1+ (0.1,0) [0|6425.5] "ohm" Vector__XXX
SG_ SpecialIgnitorLoop80Resistance : 1424|16@1+ (0.1,0) [0|6425.5] "ohm" Vector__XXX
SG_ SpecialIgnitorLoop81Resistance : 1440|16@1+ (0.1,0) [0|6425.5] "ohm" Vector__XXX
SG_ SpecialIgnitorLoop82Resistance : 1456|16@1+ (0.1,0) [0|6425.5] "ohm" Vector__XXX
SG_ SpecialIgnitorLoop83Resistance : 1472|16@1+ (0.1,0) [0|6425.5] "ohm" Vector__XXX
SG_ SpecialIgnitorLoop84Resistance : 1488|16@1+ (0.1,0) [0|6425.5] "ohm" Vector__XXX
SG_ SpecialIgnitorLoop85Resistance : 1504|16@1+ (0.1,0) [0|6425.5] "ohm" Vector__XXX
SG_ SpecialIgnitorLoop86Resistance : 1520|16@1+ (0.1,0) [0|6425.5] "ohm" Vector__XXX
SG_ SpecialIgnitorLoop87Resistance : 1536|16@1+ (0.1,0) [0|6425.5] "ohm" Vector__XXX
SG_ SpecialIgnitorLoop88Resistance : 1552|16@1+ (0.1,0) [0|6425.5] "ohm" Vector__XXX
SG_ SpecialIgnitorLoop89Resistance : 1568|16@1+ (0.1,0) [0|6425.5] "ohm" Vector__XXX
SG_ SpecialIgnitorLoop90Resistance : 1584|16@1+ (0.1,0) [0|6425.5] "ohm" Vector__XXX

BO_ 2566724350 AT1WUDOC: 8 Vector__XXX
SG_ Aft1WarmUpDslOxidtnCtlystIntkTmp : 0|16@1+ (0.03125,-273) [-273|1734.96875] "deg C" Vector__XXX
SG_ Aft1WarmUpDslOxidtnCtlystOtltTmp : 16|16@1+ (0.03125,-273) [-273|1734.96875] "deg C" Vector__XXX

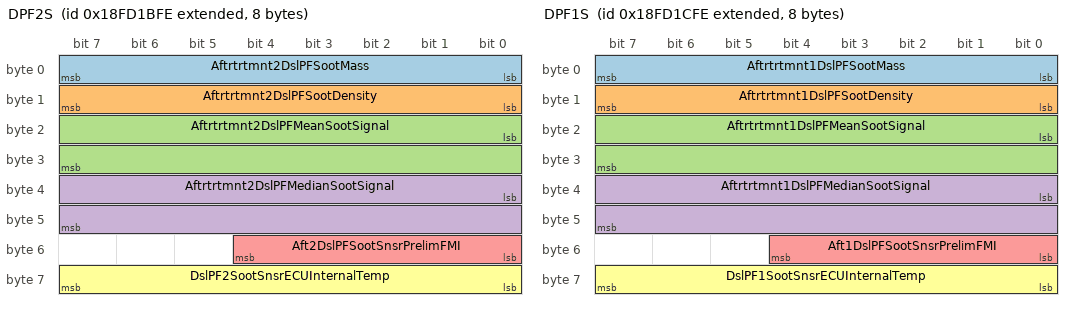
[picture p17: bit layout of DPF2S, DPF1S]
BO_ 2566724606 DPF2S: 8 Vector__XXX
SG_ Aftrtrtmnt2DslPFSootMass : 0|8@1+ (4,0) [0|1000] "g" Vector__XXX
SG_ Aftrtrtmnt2DslPFSootDensity : 8|8@1+ (0.08,0) [0|20] "g/L" Vector__XXX
SG_ Aftrtrtmnt2DslPFMeanSootSignal : 16|16@1+ (0.0025,0) [0|160.6375] "%" Vector__XXX
SG_ Aftrtrtmnt2DslPFMedianSootSignal : 32|16@1+ (0.0025,0) [0|160.6375] "%" Vector__XXX
SG_ Aft2DslPFSootSnsrPrelimFMI : 48|5@1+ (1,0) [0|31] "" Vector__XXX
SG_ DslPF2SootSnsrECUInternalTemp : 56|8@1+ (1,-40) [-40|210] "deg C" Vector__XXX

BO_ 2566724862 DPF1S: 8 Vector__XXX
SG_ Aftrtrtmnt1DslPFSootMass : 0|8@1+ (4,0) [0|1000] "g" Vector__XXX
SG_ Aftrtrtmnt1DslPFSootDensity : 8|8@1+ (0.08,0) [0|20] "g/L" Vector__XXX
SG_ Aftrtrtmnt1DslPFMeanSootSignal : 16|16@1+ (0.0025,0) [0|160.6375] "%" Vector__XXX
SG_ Aftrtrtmnt1DslPFMedianSootSignal : 32|16@1+ (0.0025,0) [0|160.6375] "%" Vector__XXX
SG_ Aft1DslPFSootSnsrPrelimFMI : 48|5@1+ (1,0) [0|31] "" Vector__XXX
SG_ DslPF1SootSnsrECUInternalTemp : 56|8@1+ (1,-40) [-40|210] "deg C" Vector__XXX

BO_ 2566725118 ATDT2: 8 Vector__XXX
SG_ Aftrtrtmnt13WyCtlystDiffTemp : 0|16@1+ (0.03125,-273) [-273|1734.96875] "deg C" Vector__XXX
SG_ Aftrtrtmnt23WyCtlystDiffTemp : 16|16@1+ (0.03125,-273) [-273|1734.96875] "deg C" Vector__XXX

BO_ 2566725374 ATDT1: 8 Vector__XXX
SG_ Aft1GasOxidtnCtlystDiffTemp : 0|16@1+ (0.03125,-273) [-273|1734.96875] "deg C" Vector__XXX
SG_ Aft2GasOxidtnCtlystDiffTemp : 16|16@1+ (0.03125,-273) [-273|1734.96875] "deg C" Vector__XXX

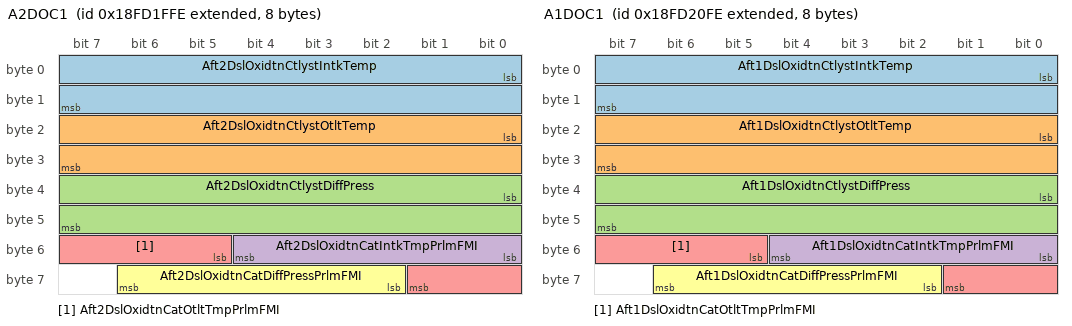
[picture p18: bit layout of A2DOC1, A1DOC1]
BO_ 2566725630 A2DOC1: 8 Vector__XXX
SG_ Aft2DslOxidtnCtlystIntkTemp : 0|16@1+ (0.03125,-273) [-273|1734.96875] "deg C" Vector__XXX
SG_ Aft2DslOxidtnCtlystOtltTemp : 16|16@1+ (0.03125,-273) [-273|1734.96875] "deg C" Vector__XXX
SG_ Aft2DslOxidtnCtlystDiffPress : 32|16@1+ (0.5,0) [0|32127.5] "kPa" Vector__XXX
SG_ Aft2DslOxidtnCatIntkTmpPrlmFMI : 48|5@1+ (1,0) [0|31] "" Vector__XXX
SG_ Aft2DslOxidtnCatOtltTmpPrlmFMI : 53|5@1+ (1,0) [0|31] "" Vector__XXX
SG_ Aft2DslOxidtnCatDiffPressPrlmFMI : 58|5@1+ (1,0) [0|31] "" Vector__XXX

BO_ 2566725886 A1DOC1: 8 Vector__XXX
SG_ Aft1DslOxidtnCtlystIntkTemp : 0|16@1+ (0.03125,-273) [-273|1734.96875] "deg C" Vector__XXX
SG_ Aft1DslOxidtnCtlystOtltTemp : 16|16@1+ (0.03125,-273) [-273|1734.96875] "deg C" Vector__XXX
SG_ Aft1DslOxidtnCtlystDiffPress : 32|16@1+ (0.1,0) [0|6425.5] "kPa" Vector__XXX
SG_ Aft1DslOxidtnCatIntkTmpPrlmFMI : 48|5@1+ (1,0) [0|31] "" Vector__XXX
SG_ Aft1DslOxidtnCatOtltTmpPrlmFMI : 53|5@1+ (1,0) [0|31] "" Vector__XXX
SG_ Aft1DslOxidtnCatDiffPressPrlmFMI : 58|5@1+ (1,0) [0|31] "" Vector__XXX

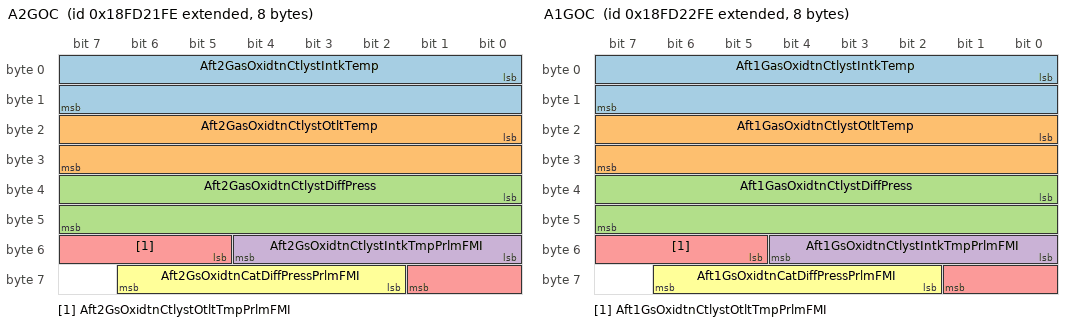
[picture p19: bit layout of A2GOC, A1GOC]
BO_ 2566726142 A2GOC: 8 Vector__XXX
SG_ Aft2GasOxidtnCtlystIntkTemp : 0|16@1+ (0.03125,-273) [-273|1734.96875] "deg C" Vector__XXX
SG_ Aft2GasOxidtnCtlystOtltTemp : 16|16@1+ (0.03125,-273) [-273|1734.96875] "deg C" Vector__XXX
SG_ Aft2GasOxidtnCtlystDiffPress : 32|16@1+ (0.1,0) [0|6425.5] "kPa" Vector__XXX
SG_ Aft2GsOxidtnCtlystIntkTmpPrlmFMI : 48|5@1+ (1,0) [0|31] "" Vector__XXX
SG_ Aft2GsOxidtnCtlystOtltTmpPrlmFMI : 53|5@1+ (1,0) [0|31] "" Vector__XXX
SG_ Aft2GsOxidtnCatDiffPressPrlmFMI : 58|5@1+ (1,0) [0|31] "" Vector__XXX

BO_ 2566726398 A1GOC: 8 Vector__XXX
SG_ Aft1GasOxidtnCtlystIntkTemp : 0|16@1+ (0.03125,-273) [-273|1734.96875] "deg C" Vector__XXX
SG_ Aft1GasOxidtnCtlystOtltTemp : 16|16@1+ (0.03125,-273) [-273|1734.96875] "deg C" Vector__XXX
SG_ Aft1GasOxidtnCtlystDiffPress : 32|16@1+ (0.1,0) [0|6425.5] "kPa" Vector__XXX
SG_ Aft1GsOxidtnCtlystIntkTmpPrlmFMI : 48|5@1+ (1,0) [0|31] "" Vector__XXX
SG_ Aft1GsOxidtnCtlystOtltTmpPrlmFMI : 53|5@1+ (1,0) [0|31] "" Vector__XXX
SG_ Aft1GsOxidtnCatDiffPressPrlmFMI : 58|5@1+ (1,0) [0|31] "" Vector__XXX

BO_ 2365400062 EJM10: 8 Vector__XXX
SG_ Jystck10GrpXAxsNtrlPosStatus : 0|2@1+ (1,0) [0|3] "" Vector__XXX
SG_ Jystck10GrpXAxsLvrLftNegPosStat : 2|2@1+ (1,0) [0|3] "" Vector__XXX
SG_ Jystck10GrpXAxsLvrRghtPstvPsStat : 4|2@1+ (1,0) [0|3] "" Vector__XXX
SG_ Joystick10GripXAxisPosition : 6|10@1+ (0.1,0) [0|102] "%" Vector__XXX
SG_ Jystck10GrpYAxsNtrlPosStatus : 16|2@1+ (1,0) [0|3] "" Vector__XXX
SG_ Jystck10GrpYAxsLvrBackNegPosStat : 18|2@1+ (1,0) [0|3] "" Vector__XXX
SG_ Jystck10GrpYAxsLvrFrwdPstvPsStat : 20|2@1+ (1,0) [0|3] "" Vector__XXX
SG_ Joystick10GripYAxisPosition : 22|10@1+ (0.1,0) [0|102] "%" Vector__XXX
SG_ Jystck10ThetaAxsNtrlPosStatus : 32|2@1+ (1,0) [0|3] "" Vector__XXX
SG_ Jystck10ThtAxsCntrClckwsNgPsStat : 34|2@1+ (1,0) [0|3] "" Vector__XXX
SG_ Jystck10ThtAxsClckwsPstvPosStat : 36|2@1+ (1,0) [0|3] "" Vector__XXX
SG_ Joystick10ThetaAxisPosition : 38|10@1+ (0.1,0) [0|102] "%" Vector__XXX
SG_ Jystck10ThetaAxsDetentPosStatus : 50|2@1+ (1,0) [0|3] "" Vector__XXX
SG_ Jystck10GrpYAxsDetentPosStatus : 52|2@1+ (1,0) [0|3] "" Vector__XXX
SG_ Jystck10GrpXAxsDetentPosStatus : 54|2@1+ (1,0) [0|3] "" Vector__XXX
SG_ Joystick10Button16PressedStatus : 56|2@1+ (1,0) [0|3] "" Vector__XXX
SG_ Joystick10Button15PressedStatus : 58|2@1+ (1,0) [0|3] "" Vector__XXX
SG_ Joystick10Button14PressedStatus : 60|2@1+ (1,0) [0|3] "" Vector__XXX
SG_ Joystick10Button13PressedStatus : 62|2@1+ (1,0) [0|3] "" Vector__XXX

BO_ 2365400318 BJM10: 8 Vector__XXX
SG_ Jystck10XAxsNtrlPositionStatus : 0|2@1+ (1,0) [0|3] "" Vector__XXX
SG_ Jystck10XAxsLvrLftNegPosStatus : 2|2@1+ (1,0) [0|3] "" Vector__XXX
SG_ Jystck10XAxsLvrRghtPstvPosStatus : 4|2@1+ (1,0) [0|3] "" Vector__XXX
SG_ Joystick10XAxisPosition : 6|10@1+ (0.1,0) [0|102] "%" Vector__XXX
SG_ Jystck10YAxsNtrlPositionStatus : 16|2@1+ (1,0) [0|3] "" Vector__XXX
SG_ Jystck10YAxsLvrBackNegPosStatus : 18|2@1+ (1,0) [0|3] "" Vector__XXX
SG_ Jystck10YAxsLvrFrwdPstvPosStatus : 20|2@1+ (1,0) [0|3] "" Vector__XXX
SG_ Joystick10YAxisPosition : 22|10@1+ (0.1,0) [0|102] "%" Vector__XXX
SG_ Jystck10YAxsDetentPositionStatus : 36|2@1+ (1,0) [0|3] "" Vector__XXX
SG_ Jystck10XAxsDetentPositionStatus : 38|2@1+ (1,0) [0|3] "" Vector__XXX
SG_ Joystick10Button4PressedStatus : 40|2@1+ (1,0) [0|3] "" Vector__XXX
SG_ Joystick10Button3PressedStatus : 42|2@1+ (1,0) [0|3] "" Vector__XXX
SG_ Joystick10Button2PressedStatus : 44|2@1+ (1,0) [0|3] "" Vector__XXX
SG_ Joystick10Button1PressedStatus : 46|2@1+ (1,0) [0|3] "" Vector__XXX
SG_ Joystick10Button8PressedStatus : 48|2@1+ (1,0) [0|3] "" Vector__XXX
SG_ Joystick10Button7PressedStatus : 50|2@1+ (1,0) [0|3] "" Vector__XXX
SG_ Joystick10Button6PressedStatus : 52|2@1+ (1,0) [0|3] "" Vector__XXX
SG_ Joystick10Button5PressedStatus : 54|2@1+ (1,0) [0|3] "" Vector__XXX
SG_ Joystick10Button12PressedStatus : 56|2@1+ (1,0) [0|3] "" Vector__XXX
SG_ Joystick10Button11PressedStatus : 58|2@1+ (1,0) [0|3] "" Vector__XXX
SG_ Joystick10Button10PressedStatus : 60|2@1+ (1,0) [0|3] "" Vector__XXX
SG_ Joystick10Button9PressedStatus : 62|2@1+ (1,0) [0|3] "" Vector__XXX

BO_ 2365400574 EJM9: 8 Vector__XXX
SG_ Jystck9GrpXAxsNtrlPositionStatus : 0|2@1+ (1,0) [0|3] "" Vector__XXX
SG_ Jystck9GrpXAxsLvrLftNegPosStatus : 2|2@1+ (1,0) [0|3] "" Vector__XXX
SG_ Jystck9GrpXAxsLvrRghtPstvPosStat : 4|2@1+ (1,0) [0|3] "" Vector__XXX
SG_ Joystick9GripXAxisPosition : 6|10@1+ (0.1,0) [0|102] "%" Vector__XXX
SG_ Jystck9GrpYAxsNtrlPositionStatus : 16|2@1+ (1,0) [0|3] "" Vector__XXX
SG_ Jystck9GrpYAxsLvrBackNegPosStat : 18|2@1+ (1,0) [0|3] "" Vector__XXX
SG_ Jystck9GrpYAxsLvrFrwdPstvPosStat : 20|2@1+ (1,0) [0|3] "" Vector__XXX
SG_ Joystick9GripYAxisPosition : 22|10@1+ (0.1,0) [0|102] "%" Vector__XXX
SG_ Jystck9ThetaAxsNtrlPosStatus : 32|2@1+ (1,0) [0|3] "" Vector__XXX
SG_ Jystck9ThtAxsCntrClckwsNegPsStat : 34|2@1+ (1,0) [0|3] "" Vector__XXX
SG_ Jystck9ThetaAxsClckwsPstvPosStat : 36|2@1+ (1,0) [0|3] "" Vector__XXX
SG_ Joystick9ThetaAxisPosition : 38|10@1+ (0.1,0) [0|102] "%" Vector__XXX
SG_ Jystck9ThetaAxsDetentPosStatus : 50|2@1+ (1,0) [0|3] "" Vector__XXX
SG_ Jystck9GrpYAxsDetentPosStatus : 52|2@1+ (1,0) [0|3] "" Vector__XXX
SG_ Jystck9GrpXAxsDetentPosStatus : 54|2@1+ (1,0) [0|3] "" Vector__XXX
SG_ Joystick9Button16PressedStatus : 56|2@1+ (1,0) [0|3] "" Vector__XXX
SG_ Joystick9Button15PressedStatus : 58|2@1+ (1,0) [0|3] "" Vector__XXX
SG_ Joystick9Button14PressedStatus : 60|2@1+ (1,0) [0|3] "" Vector__XXX
SG_ Joystick9Button13PressedStatus : 62|2@1+ (1,0) [0|3] "" Vector__XXX

BO_ 2365400830 BJM9: 8 Vector__XXX
SG_ Jystck9XAxsNeutralPositionStatus : 0|2@1+ (1,0) [0|3] "" Vector__XXX
SG_ Jystck9XAxsLvrLftNegPosStatus : 2|2@1+ (1,0) [0|3] "" Vector__XXX
SG_ Jystck9XAxsLvrRightPstvPosStatus : 4|2@1+ (1,0) [0|3] "" Vector__XXX
SG_ Joystick9XAxisPosition : 6|10@1+ (0.1,0) [0|102] "%" Vector__XXX
SG_ Jystck9YAxsNeutralPositionStatus : 16|2@1+ (1,0) [0|3] "" Vector__XXX
SG_ Jystck9YAxsLvrBackNegPosStatus : 18|2@1+ (1,0) [0|3] "" Vector__XXX
SG_ Jystck9YAxsLvrFrwdPstvPosStatus : 20|2@1+ (1,0) [0|3] "" Vector__XXX
SG_ Joystick9YAxisPosition : 22|10@1+ (0.1,0) [0|102] "%" Vector__XXX
SG_ Jystck9YAxsDetentPositionStatus : 36|2@1+ (1,0) [0|3] "" Vector__XXX
SG_ Jystck9XAxsDetentPositionStatus : 38|2@1+ (1,0) [0|3] "" Vector__XXX
SG_ Joystick9Button4PressedStatus : 40|2@1+ (1,0) [0|3] "" Vector__XXX
SG_ Joystick9Button3PressedStatus : 42|2@1+ (1,0) [0|3] "" Vector__XXX
SG_ Joystick9Button2PressedStatus : 44|2@1+ (1,0) [0|3] "" Vector__XXX
SG_ Joystick9Button1PressedStatus : 46|2@1+ (1,0) [0|3] "" Vector__XXX
SG_ Joystick9Button8PressedStatus : 48|2@1+ (1,0) [0|3] "" Vector__XXX
SG_ Joystick9Button7PressedStatus : 50|2@1+ (1,0) [0|3] "" Vector__XXX
SG_ Joystick9Button6PressedStatus : 52|2@1+ (1,0) [0|3] "" Vector__XXX
SG_ Joystick9Button5PressedStatus : 54|2@1+ (1,0) [0|3] "" Vector__XXX
SG_ Joystick9Button12PressedStatus : 56|2@1+ (1,0) [0|3] "" Vector__XXX
SG_ Joystick9Button11PressedStatus : 58|2@1+ (1,0) [0|3] "" Vector__XXX
SG_ Joystick9Button10PressedStatus : 60|2@1+ (1,0) [0|3] "" Vector__XXX
SG_ Joystick9Button9PressedStatus : 62|2@1+ (1,0) [0|3] "" Vector__XXX

BO_ 2365401086 EJM8: 8 Vector__XXX
SG_ Jystck8GrpXAxsNtrlPositionStatus : 0|2@1+ (1,0) [0|3] "" Vector__XXX
SG_ Jystck8GrpXAxsLvrLftNegPosStatus : 2|2@1+ (1,0) [0|3] "" Vector__XXX
SG_ Jystck8GrpXAxsLvrRghtPstvPosStat : 4|2@1+ (1,0) [0|3] "" Vector__XXX
SG_ Joystick8GripXAxisPosition : 6|10@1+ (0.1,0) [0|102] "%" Vector__XXX
SG_ Jystck8GrpYAxsNtrlPositionStatus : 16|2@1+ (1,0) [0|3] "" Vector__XXX
SG_ Jystck8GrpYAxsLvrBackNegPosStat : 18|2@1+ (1,0) [0|3] "" Vector__XXX
SG_ Jystck8GrpYAxsLvrFrwdPstvPosStat : 20|2@1+ (1,0) [0|3] "" Vector__XXX
SG_ Joystick8GripYAxisPosition : 22|10@1+ (0.1,0) [0|102] "%" Vector__XXX
SG_ Jystck8ThetaAxsNtrlPosStatus : 32|2@1+ (1,0) [0|3] "" Vector__XXX
SG_ Jystck8ThtAxsCntrClckwsNegPsStat : 34|2@1+ (1,0) [0|3] "" Vector__XXX
SG_ Jystck8ThetaAxsClckwsPstvPosStat : 36|2@1+ (1,0) [0|3] "" Vector__XXX
SG_ Joystick8ThetaAxisPosition : 38|10@1+ (0.1,0) [0|102] "%" Vector__XXX
SG_ Jystck8ThetaAxsDetentPosStatus : 50|2@1+ (1,0) [0|3] "" Vector__XXX
SG_ Jystck8GrpYAxsDetentPosStatus : 52|2@1+ (1,0) [0|3] "" Vector__XXX
SG_ Jystck8GrpXAxsDetentPosStatus : 54|2@1+ (1,0) [0|3] "" Vector__XXX
SG_ Joystick8Button16PressedStatus : 56|2@1+ (1,0) [0|3] "" Vector__XXX
SG_ Joystick8Button15PressedStatus : 58|2@1+ (1,0) [0|3] "" Vector__XXX
SG_ Joystick8Button14PressedStatus : 60|2@1+ (1,0) [0|3] "" Vector__XXX
SG_ Joystick8Button13PressedStatus : 62|2@1+ (1,0) [0|3] "" Vector__XXX

BO_ 2365401342 BJM8: 8 Vector__XXX
SG_ Jystck8XAxsNeutralPositionStatus : 0|2@1+ (1,0) [0|3] "" Vector__XXX
SG_ Jystck8XAxsLvrLftNegPosStatus : 2|2@1+ (1,0) [0|3] "" Vector__XXX
SG_ Jystck8XAxsLvrRightPstvPosStatus : 4|2@1+ (1,0) [0|3] "" Vector__XXX
SG_ Joystick8XAxisPosition : 6|10@1+ (0.1,0) [0|102] "%" Vector__XXX
SG_ Jystck8YAxsNeutralPositionStatus : 16|2@1+ (1,0) [0|3] "" Vector__XXX
SG_ Jystck8YAxsLvrBackNegPosStatus : 18|2@1+ (1,0) [0|3] "" Vector__XXX
SG_ Jystck8YAxsLvrFrwdPstvPosStatus : 20|2@1+ (1,0) [0|3] "" Vector__XXX
SG_ Joystick8YAxisPosition : 22|10@1+ (0.1,0) [0|102] "%" Vector__XXX
SG_ Jystck8YAxsDetentPositionStatus : 36|2@1+ (1,0) [0|3] "" Vector__XXX
SG_ Jystck8XAxsDetentPositionStatus : 38|2@1+ (1,0) [0|3] "" Vector__XXX
SG_ Joystick8Button4PressedStatus : 40|2@1+ (1,0) [0|3] "" Vector__XXX
SG_ Joystick8Button3PressedStatus : 42|2@1+ (1,0) [0|3] "" Vector__XXX
SG_ Joystick8Button2PressedStatus : 44|2@1+ (1,0) [0|3] "" Vector__XXX
SG_ Joystick8Button1PressedStatus : 46|2@1+ (1,0) [0|3] "" Vector__XXX
SG_ Joystick8Button8PressedStatus : 48|2@1+ (1,0) [0|3] "" Vector__XXX
SG_ Joystick8Button7PressedStatus : 50|2@1+ (1,0) [0|3] "" Vector__XXX
SG_ Joystick8Button6PressedStatus : 52|2@1+ (1,0) [0|3] "" Vector__XXX
SG_ Joystick8Button5PressedStatus : 54|2@1+ (1,0) [0|3] "" Vector__XXX
SG_ Joystick8Button12PressedStatus : 56|2@1+ (1,0) [0|3] "" Vector__XXX
SG_ Joystick8Button11PressedStatus : 58|2@1+ (1,0) [0|3] "" Vector__XXX
SG_ Joystick8Button10PressedStatus : 60|2@1+ (1,0) [0|3] "" Vector__XXX
SG_ Joystick8Button9PressedStatus : 62|2@1+ (1,0) [0|3] "" Vector__XXX

BO_ 2365401598 EJM7: 8 Vector__XXX
SG_ Jystck7GrpXAxsNtrlPositionStatus : 0|2@1+ (1,0) [0|3] "" Vector__XXX
SG_ Jystck7GrpXAxsLvrLftNegPosStatus : 2|2@1+ (1,0) [0|3] "" Vector__XXX
SG_ Jystck7GrpXAxsLvrRghtPstvPosStat : 4|2@1+ (1,0) [0|3] "" Vector__XXX
SG_ Joystick7GripXAxisPosition : 6|10@1+ (0.1,0) [0|102] "%" Vector__XXX
SG_ Jystck7GrpYAxsNtrlPositionStatus : 16|2@1+ (1,0) [0|3] "" Vector__XXX
SG_ Jystck7GrpYAxsLvrBackNegPosStat : 18|2@1+ (1,0) [0|3] "" Vector__XXX
SG_ Jystck7GrpYAxsLvrFrwdPstvPosStat : 20|2@1+ (1,0) [0|3] "" Vector__XXX
SG_ Joystick7GripYAxisPosition : 22|10@1+ (0.1,0) [0|102] "%" Vector__XXX
SG_ Jystck7ThetaAxsNtrlPosStatus : 32|2@1+ (1,0) [0|3] "" Vector__XXX
SG_ Jystck7ThtAxsCntrClckwsNegPsStat : 34|2@1+ (1,0) [0|3] "" Vector__XXX
SG_ Jystck7ThetaAxsClckwsPstvPosStat : 36|2@1+ (1,0) [0|3] "" Vector__XXX
SG_ Joystick7ThetaAxisPosition : 38|10@1+ (0.1,0) [0|102] "%" Vector__XXX
SG_ Jystck7ThetaAxsDetentPosStatus : 50|2@1+ (1,0) [0|3] "" Vector__XXX
SG_ Jystck7GrpYAxsDetentPosStatus : 52|2@1+ (1,0) [0|3] "" Vector__XXX
SG_ Jystck7GrpXAxsDetentPosStatus : 54|2@1+ (1,0) [0|3] "" Vector__XXX
SG_ Joystick7Button16PressedStatus : 56|2@1+ (1,0) [0|3] "" Vector__XXX
SG_ Joystick7Button15PressedStatus : 58|2@1+ (1,0) [0|3] "" Vector__XXX
SG_ Joystick7Button14PressedStatus : 60|2@1+ (1,0) [0|3] "" Vector__XXX
SG_ Joystick7Button13PressedStatus : 62|2@1+ (1,0) [0|3] "" Vector__XXX

BO_ 2365401854 BJM7: 8 Vector__XXX
SG_ Jystck7XAxsNeutralPositionStatus : 0|2@1+ (1,0) [0|3] "" Vector__XXX
SG_ Jystck7XAxsLvrLftNegPosStatus : 2|2@1+ (1,0) [0|3] "" Vector__XXX
SG_ Jystck7XAxsLvrRightPstvPosStatus : 4|2@1+ (1,0) [0|3] "" Vector__XXX
SG_ Joystick7XAxisPosition : 6|10@1+ (0.1,0) [0|102] "%" Vector__XXX
SG_ Jystck7YAxsNeutralPositionStatus : 16|2@1+ (1,0) [0|3] "" Vector__XXX
SG_ Jystck7YAxsLvrBackNegPosStatus : 18|2@1+ (1,0) [0|3] "" Vector__XXX
SG_ Jystck7YAxsLvrFrwdPstvPosStatus : 20|2@1+ (1,0) [0|3] "" Vector__XXX
SG_ Joystick7YAxisPosition : 22|10@1+ (0.1,0) [0|102] "%" Vector__XXX
SG_ Jystck7YAxsDetentPositionStatus : 36|2@1+ (1,0) [0|3] "" Vector__XXX
SG_ Jystck7XAxsDetentPositionStatus : 38|2@1+ (1,0) [0|3] "" Vector__XXX
SG_ Joystick7Button4PressedStatus : 40|2@1+ (1,0) [0|3] "" Vector__XXX
SG_ Joystick7Button3PressedStatus : 42|2@1+ (1,0) [0|3] "" Vector__XXX
SG_ Joystick7Button2PressedStatus : 44|2@1+ (1,0) [0|3] "" Vector__XXX
SG_ Joystick7Button1PressedStatus : 46|2@1+ (1,0) [0|3] "" Vector__XXX
SG_ Joystick7Button8PressedStatus : 48|2@1+ (1,0) [0|3] "" Vector__XXX
SG_ Joystick7Button7PressedStatus : 50|2@1+ (1,0) [0|3] "" Vector__XXX
SG_ Joystick7Button6PressedStatus : 52|2@1+ (1,0) [0|3] "" Vector__XXX
SG_ Joystick7Button5PressedStatus : 54|2@1+ (1,0) [0|3] "" Vector__XXX
SG_ Joystick7Button12PressedStatus : 56|2@1+ (1,0) [0|3] "" Vector__XXX
SG_ Joystick7Button11PressedStatus : 58|2@1+ (1,0) [0|3] "" Vector__XXX
SG_ Joystick7Button10PressedStatus : 60|2@1+ (1,0) [0|3] "" Vector__XXX
SG_ Joystick7Button9PressedStatus : 62|2@1+ (1,0) [0|3] "" Vector__XXX

CM_ BO_ 2566698238 "Switched Power Output Status";
CM_ BO_ 2566698494 "Fused Power Output Status";
CM_ BO_ 2566698750 "Vehicle Electrical Power 5";
CM_ BO_ 2566699006 "Hybrid System Status 2";
CM_ BO_ 2566699262 "Aftertreatment 2 Service 2";
CM_ BO_ 2566699518 "Aftertreatment 1 Service 2";
CM_ BO_ 2566699774 "Aftertreatment 2 SCR Electronic Control Module Information";
CM_ BO_ 2566700030 "Aftertreatment 1 SCR Electronic Control Module Information";
CM_ BO_ 2566700286 "Aftertreatment 2 SCR Service Information 2";
CM_ BO_ 2566700542 "Aftertreatment 1 SCR Service Information 2";
CM_ BO_ 2365374206 "Electronic Transmission Controller #9";
CM_ BO_ 2499592190 "Electronic Transmission Controller #10";
CM_ BO_ 2499592446 "Electronic Transmission Controller #11";
CM_ BO_ 2566701566 "Transmission Fluids 3";
CM_ BO_ 2566701822 "Hybrid System Status 1";
CM_ BO_ 2566702078 "Fuel Information 4 (Gaseous)";
CM_ BO_ 2566702334 "Aftertreatment 2 SCR Exhaust Gas Temperature 2";
CM_ BO_ 2566702590 "Aftertreatment 1 SCR Exhaust Gas Temperature 2";
CM_ BO_ 2566702846 "OBD Information";
CM_ BO_ 2566703102 "Model Year and Certification Engine Family";
CM_ BO_ 2566703358 "Electronic Engine Controller 13";
CM_ BO_ 2566703614 "Engine Fuel/Throttle Valve Information 2";
CM_ BO_ 2566703870 "Engine Exhaust Gas Recirculation 2 Actuator";
CM_ BO_ 2566704126 "Engine Exhaust Gas Recirculation 1 Actuator";
CM_ BO_ 2566704382 "Electronic Engine Controller 12";
CM_ BO_ 2566705150 "NOx Sensor Self-Diagnosis Request";
CM_ BO_ 2566705406 "Engine Particulate Sensor Information";
CM_ BO_ 2566705662 "Active Service Only DTCs";
CM_ BO_ 2566705918 "Previously Active Service Only DTCs";
CM_ BO_ 2566706174 "Diagnostic Data Clear/Reset for All Service Only DTCs";
CM_ BO_ 2566706430 "XCP Get Slave ID";
CM_ BO_ 2566706686 "Aftertreatment 1 Diesel Exhaust Fluid Pump 1 Information";
CM_ BO_ 2566706942 "Aftertreatment 1 Diesel Particulate Filter 2 Soot 5";
CM_ BO_ 2566707198 "Aftertreatment 1 Diesel Particulate Filter 2 Soot 4";
CM_ BO_ 2566707454 "Aftertreatment 1 Diesel Particulate Filter 2 Soot 3";
CM_ BO_ 2566707710 "Aftertreatment 1 Diesel Particulate Filter 1 Soot 5";
CM_ BO_ 2566707966 "Aftertreatment 1 Diesel Particulate Filter 1 Soot 4";
CM_ BO_ 2566708222 "Aftertreatment 1 Diesel Particulate Filter 1 Soot 3";
CM_ BO_ 2566708478 "Cruise Control / Vehicle Speed 3";
CM_ BO_ 2566708734 "Aftertreatment 2 Air Control 3";
CM_ BO_ 2566708990 "Aftertreatment 1 Air Control 3";
CM_ BO_ 2566709246 "Engine Fluid Level/Pressure 12";
CM_ BO_ 2566709502 "Diesel Particulate Filter Control 2";
CM_ BO_ 2566709758 "Fuel Economy 2 (Liquid)";
CM_ BO_ 2566710014 "Supplemental Fan Status";
CM_ BO_ 2432492542 "Engine Exhaust Brake Control";
CM_ BO_ 2566710526 "Engine Fuel Properties";
CM_ BO_ 2566710782 "Hydraulic Oil Properties";
CM_ BO_ 2566711038 "Vehicle/Chassis Lubrication System 2";
CM_ BO_ 2566711294 "Engine Configuration 3";
CM_ BO_ 2566711550 "Intake Valve Actuation Control";
CM_ BO_ 2566711806 "Armrest Switch Matrix Commands";
CM_ BO_ 2566712318 "Aftertreatment 2 NOx Adsorber Information";
CM_ BO_ 2566712574 "Aftertreatment 1 NOx Adsorber Information";
CM_ BO_ 2566712830 "Aftertreatment 2 Warm Up Diesel Oxidation Catalyst Information";
CM_ BO_ 2499604222 "Land Leveling System Reference Elevation Data";
CM_ BO_ 2499604478 "Engine Fluid Level/Pressure 11";
CM_ BO_ 2566713598 "Engine Fuel/lube systems 2";
CM_ BO_ 2566713854 "Engine Turbocharger Wastegate Actuator and Exhaust Back Pressure Regulator Information";
CM_ BO_ 2566714110 "Engine Fuel/Throttle Valve Information 1";
CM_ BO_ 2566714366 "Engine Turbocharger Compressor Bypass Information";
CM_ BO_ 2566714622 "Charge Air Cooler 2";
CM_ BO_ 2566714878 "Charge Air Cooler 2 Precooler";
CM_ BO_ 2566715134 "Charge Air Cooler 1";
CM_ BO_ 2566715390 "Charge Air Cooler 1 Precooler";
CM_ BO_ 2566715646 "Diesel Particulate Filter 2 Soot 2";
CM_ BO_ 2566715902 "Diesel Particulate Filter 1 Soot 2";
CM_ BO_ 2633825022 "Electronic Engine Controller 11";
CM_ BO_ 2499607550 "Engine Manifold Actuator Position";
CM_ BO_ 2633825534 "Engine Manifold Actuator Control";
CM_ BO_ 2432499198 "Electronic Engine Controller 9";
CM_ BO_ 2633826046 "Electronic Engine Controller 10";
CM_ BO_ 2566717438 "Engine Temperature 5";
CM_ BO_ 2499608830 "Engine Fluid Level/Pressure 10";
CM_ BO_ 2566717950 "Low Voltage Disconnect  Status";
CM_ BO_ 2566718718 "Direct Lamp Control Data 2";
CM_ BO_ 2566718974 "Direct Lamp Control Data 1";
CM_ BO_ 2566719230 "Direct Lamp Control Command 2";
CM_ BO_ 2566719486 "Direct Lamp Control Command 1";
CM_ BO_ 2633828606 "Engine oil message";
CM_ BO_ 2566719998 "High Resolution Fuel Consumption (Liquid)";
CM_ BO_ 2365393662 "Aftertreatment 2 Outlet Gas NOx Sensor correction data 2";
CM_ BO_ 2365393918 "Aftertreatment 2 Outlet Gas NOx Sensor correction data 1";
CM_ BO_ 2365394174 "Aftertreatment 2 Intake Gas NOx Sensor correction data 2";
CM_ BO_ 2365394430 "Aftertreatment 2 Intake Gas NOx Sensor correction data 1";
CM_ BO_ 2365394686 "Aftertreatment 1 Outlet Gas NOx Sensor correction data 2";
CM_ BO_ 2365394942 "Aftertreatment 1 Outlet Gas NOx Sensor correction data 1";
CM_ BO_ 2365395198 "Aftertreatment 1 Intake Gas NOx Sensor correction data 2";
CM_ BO_ 2365395454 "Aftertreatment 1 Intake Gas NOx Sensor Correction Data 1";
CM_ BO_ 2566722302 "Magnet Status Information 1";
CM_ BO_ 2566722558 "Magnet System Configuration Information";
CM_ BO_ 2566722814 "Battery Charger 2";
CM_ BO_ 2566723070 "Battery Charger 1";
CM_ BO_ 2499614462 "Occupant Classification System Information";
CM_ BO_ 2499614718 "Beltlock and Airbag Deactivation Switch Information";
CM_ BO_ 2633832702 "Collision Sensor Information";
CM_ BO_ 2633832958 "Ignitor Loop Information";
CM_ BO_ 2566724350 "Aftertreatment 1 Warm Up Diesel Oxidation Catalyst Information";
CM_ BO_ 2566724606 "Diesel Particulate Filter 2 Soot";
CM_ BO_ 2566724862 "Diesel Particulate Filter 1 Soot";
CM_ BO_ 2566725118 "Aftertreatment Differential Temperature 2";
CM_ BO_ 2566725374 "Aftertreatment Differential Temperature 1";
CM_ BO_ 2566725630 "Aftertreatment 2 Diesel Oxidation Catalyst 1";
CM_ BO_ 2566725886 "Aftertreatment 1 Diesel Oxidation Catalyst 1";
CM_ BO_ 2566726142 "Aftertreatment 2 Gas Oxidation Catalyst";
CM_ BO_ 2566726398 "Aftertreatment 1 Gas Oxidation Catalyst";
CM_ BO_ 2365400062 "Extended Joystick Message 10";
CM_ BO_ 2365400318 "Basic Joystick Message 10";
CM_ BO_ 2365400574 "Extended Joystick Message 9";
CM_ BO_ 2365400830 "Basic Joystick Message 9";
CM_ BO_ 2365401086 "Extended Joystick Message 8";
CM_ BO_ 2365401342 "Basic Joystick Message 8";
CM_ BO_ 2365401598 "Extended Joystick Message 7";
CM_ BO_ 2365401854 "Basic Joystick Message 7";
BA_DEF_ BO_  "VFrameFormat" ENUM  "StandardCAN","ExtendedCAN","reserved","J1939PG";
BA_DEF_ BO_  "GenMsgCycleTime" INT 0 65535;
BA_DEF_ SG_  "GenSigStartValue" FLOAT -3.4E+038 3.4E+038;
BA_DEF_ SG_  "SPN" INT ;
BA_DEF_ SG_  "SigType" ENUM "Default","Range","RangeSigned","ASCII","Discrete","Control","ReferencePGN","DTC","StringDelimiter","StringLength","StringLengthControl","MessageCounter","MessageChecksum";
BA_DEF_DEF_  "VFrameFormat" "J1939PG";
BA_DEF_DEF_  "GenMsgCycleTime" 0;
BA_DEF_DEF_  "GenSigStartValue" 0;
BA_DEF_DEF_  "SPN" 0;
BA_DEF_DEF_  "SigType" "Default";
BA_ "GenMsgCycleTime" BO_ 2566698238 1000;
BA_ "GenMsgCycleTime" BO_ 2566698494 1000;
BA_ "GenMsgCycleTime" BO_ 2566698750 1000;
BA_ "GenMsgCycleTime" BO_ 2566699006 1000;
BA_ "GenMsgCycleTime" BO_ 2566699774 1000;
BA_ "GenMsgCycleTime" BO_ 2566700030 1000;
BA_ "GenMsgCycleTime" BO_ 2365374206 20;
BA_ "GenMsgCycleTime" BO_ 2499592190 100;
BA_ "GenMsgCycleTime" BO_ 2499592446 100;
BA_ "GenMsgCycleTime" BO_ 2566701566 1000;
BA_ "GenMsgCycleTime" BO_ 2566701822 1000;
BA_ "GenMsgCycleTime" BO_ 2566702078 200;
BA_ "GenMsgCycleTime" BO_ 2566702334 500;
BA_ "GenMsgCycleTime" BO_ 2566702590 500;
BA_ "GenMsgCycleTime" BO_ 2566703358 1000;
BA_ "GenMsgCycleTime" BO_ 2566703614 100;
BA_ "GenMsgCycleTime" BO_ 2566703870 100;
BA_ "GenMsgCycleTime" BO_ 2566704126 100;
BA_ "GenMsgCycleTime" BO_ 2566706686 500;
BA_ "GenMsgCycleTime" BO_ 2566706942 1000;
BA_ "GenMsgCycleTime" BO_ 2566707198 1000;
BA_ "GenMsgCycleTime" BO_ 2566707454 1000;
BA_ "GenMsgCycleTime" BO_ 2566707710 1000;
BA_ "GenMsgCycleTime" BO_ 2566707966 1000;
BA_ "GenMsgCycleTime" BO_ 2566708222 1000;
BA_ "GenMsgCycleTime" BO_ 2566708478 1000;
BA_ "GenMsgCycleTime" BO_ 2566708734 500;
BA_ "GenMsgCycleTime" BO_ 2566708990 500;
BA_ "GenMsgCycleTime" BO_ 2566709246 500;
BA_ "GenMsgCycleTime" BO_ 2566709502 100;
BA_ "GenMsgCycleTime" BO_ 2566709758 100;
BA_ "GenMsgCycleTime" BO_ 2566710014 1000;
BA_ "GenMsgCycleTime" BO_ 2432492542 100;
BA_ "GenMsgCycleTime" BO_ 2566710526 30000;
BA_ "GenMsgCycleTime" BO_ 2566710782 30000;
BA_ "GenMsgCycleTime" BO_ 2566711038 500;
BA_ "GenMsgCycleTime" BO_ 2566711294 5000;
BA_ "GenMsgCycleTime" BO_ 2566711550 500;
BA_ "GenMsgCycleTime" BO_ 2566711806 100;
BA_ "GenMsgCycleTime" BO_ 2566712318 1000;
BA_ "GenMsgCycleTime" BO_ 2566712574 1000;
BA_ "GenMsgCycleTime" BO_ 2566712830 500;
BA_ "GenMsgCycleTime" BO_ 2499604222 200;
BA_ "GenMsgCycleTime" BO_ 2499604478 500;
BA_ "GenMsgCycleTime" BO_ 2566713598 500;
BA_ "GenMsgCycleTime" BO_ 2566713854 100;
BA_ "GenMsgCycleTime" BO_ 2566714110 100;
BA_ "GenMsgCycleTime" BO_ 2566714366 100;
BA_ "GenMsgCycleTime" BO_ 2566714622 1000;
BA_ "GenMsgCycleTime" BO_ 2566714878 1000;
BA_ "GenMsgCycleTime" BO_ 2566715134 1000;
BA_ "GenMsgCycleTime" BO_ 2566715390 1000;
BA_ "GenMsgCycleTime" BO_ 2566715646 1000;
BA_ "GenMsgCycleTime" BO_ 2566715902 1000;
BA_ "GenMsgCycleTime" BO_ 2432499198 100;
BA_ "GenMsgCycleTime" BO_ 2566717438 1000;
BA_ "GenMsgCycleTime" BO_ 2499608830 500;
BA_ "GenMsgCycleTime" BO_ 2566717950 500;
BA_ "GenMsgCycleTime" BO_ 2566718718 1000;
BA_ "GenMsgCycleTime" BO_ 2566718974 1000;
BA_ "GenMsgCycleTime" BO_ 2566719230 1000;
BA_ "GenMsgCycleTime" BO_ 2566719486 1000;
BA_ "GenMsgCycleTime" BO_ 2633828606 30000;
BA_ "GenMsgCycleTime" BO_ 2566719998 1000;
BA_ "GenMsgCycleTime" BO_ 2365393918 1000;
BA_ "GenMsgCycleTime" BO_ 2365394430 1000;
BA_ "GenMsgCycleTime" BO_ 2365394942 1000;
BA_ "GenMsgCycleTime" BO_ 2365395454 1000;
BA_ "GenMsgCycleTime" BO_ 2566722302 500;
BA_ "GenMsgCycleTime" BO_ 2566722814 1000;
BA_ "GenMsgCycleTime" BO_ 2566723070 1000;
BA_ "GenMsgCycleTime" BO_ 2499614462 5000;
BA_ "GenMsgCycleTime" BO_ 2499614718 250;
BA_ "GenMsgCycleTime" BO_ 2566724350 500;
BA_ "GenMsgCycleTime" BO_ 2566724606 1000;
BA_ "GenMsgCycleTime" BO_ 2566724862 1000;
BA_ "GenMsgCycleTime" BO_ 2566725630 500;
BA_ "GenMsgCycleTime" BO_ 2566725886 500;
BA_ "GenMsgCycleTime" BO_ 2566726142 500;
BA_ "GenMsgCycleTime" BO_ 2566726398 500;
BA_ "GenMsgCycleTime" BO_ 2365400062 100;
BA_ "GenMsgCycleTime" BO_ 2365400318 100;
BA_ "GenMsgCycleTime" BO_ 2365400574 100;
BA_ "GenMsgCycleTime" BO_ 2365400830 100;
BA_ "GenMsgCycleTime" BO_ 2365401086 100;
BA_ "GenMsgCycleTime" BO_ 2365401342 100;
BA_ "GenMsgCycleTime" BO_ 2365401598 100;
BA_ "GenMsgCycleTime" BO_ 2365401854 100;
BA_ "SPN" SG_ 2566698238 SwitchedOutput4 6048;
BA_ "SPN" SG_ 2566698238 SwitchedOutput3 6049;
BA_ "SPN" SG_ 2566698238 SwitchedOutput2 6050;
BA_ "SPN" SG_ 2566698238 SwitchedOutput1 6051;
BA_ "SPN" SG_ 2566698238 SwitchedOutput8 6052;
BA_ "SPN" SG_ 2566698238 SwitchedOutput7 6053;
BA_ "SPN" SG_ 2566698238 SwitchedOutput6 6054;
BA_ "SPN" SG_ 2566698238 SwitchedOutput5 6055;
BA_ "SPN" SG_ 2566698238 SwitchedOutput12 6056;
BA_ "SPN" SG_ 2566698238 SwitchedOutput11 6057;
BA_ "SPN" SG_ 2566698238 SwitchedOutput10 6058;
BA_ "SPN" SG_ 2566698238 SwitchedOutput9 6059;
BA_ "SPN" SG_ 2566698238 SwitchedOutput16 6060;
BA_ "SPN" SG_ 2566698238 SwitchedOutput15 6061;
BA_ "SPN" SG_ 2566698238 SwitchedOutput14 6062;
BA_ "SPN" SG_ 2566698238 SwitchedOutput13 6063;
BA_ "SPN" SG_ 2566698238 SwitchedOutput20 6064;
BA_ "SPN" SG_ 2566698238 SwitchedOutput19 6065;
BA_ "SPN" SG_ 2566698238 SwitchedOutput18 6066;
BA_ "SPN" SG_ 2566698238 SwitchedOutput17 6067;
BA_ "SPN" SG_ 2566698238 SwitchedOutput24 6068;
BA_ "SPN" SG_ 2566698238 SwitchedOutput23 6069;
BA_ "SPN" SG_ 2566698238 SwitchedOutput22 6070;
BA_ "SPN" SG_ 2566698238 SwitchedOutput21 6071;
BA_ "SPN" SG_ 2566698238 SwitchedOutput28 6072;
BA_ "SPN" SG_ 2566698238 SwitchedOutput27 6073;
BA_ "SPN" SG_ 2566698238 SwitchedOutput26 6074;
BA_ "SPN" SG_ 2566698238 SwitchedOutput25 6075;
BA_ "SPN" SG_ 2566698238 SwitchedOutput32 6076;
BA_ "SPN" SG_ 2566698238 SwitchedOutput31 6077;
BA_ "SPN" SG_ 2566698238 SwitchedOutput30 6078;
BA_ "SPN" SG_ 2566698238 SwitchedOutput29 6079;
BA_ "SPN" SG_ 2566698494 FusedOutput4 6016;
BA_ "SPN" SG_ 2566698494 FusedOutput3 6017;
BA_ "SPN" SG_ 2566698494 FusedOutput2 6018;
BA_ "SPN" SG_ 2566698494 FusedOutput1 6019;
BA_ "SPN" SG_ 2566698494 FusedOutput8 6020;
BA_ "SPN" SG_ 2566698494 FusedOutput7 6021;
BA_ "SPN" SG_ 2566698494 FusedOutput6 6022;
BA_ "SPN" SG_ 2566698494 FusedOutput5 6023;
BA_ "SPN" SG_ 2566698494 FusedOutput12 6024;
BA_ "SPN" SG_ 2566698494 FusedOutput11 6025;
BA_ "SPN" SG_ 2566698494 FusedOutput10 6026;
BA_ "SPN" SG_ 2566698494 FusedOutput9 6027;
BA_ "SPN" SG_ 2566698494 FusedOutput16 6028;
BA_ "SPN" SG_ 2566698494 FusedOutput15 6029;
BA_ "SPN" SG_ 2566698494 FusedOutput14 6030;
BA_ "SPN" SG_ 2566698494 FusedOutput13 6031;
BA_ "SPN" SG_ 2566698494 FusedOutput20 6032;
BA_ "SPN" SG_ 2566698494 FusedOutput19 6033;
BA_ "SPN" SG_ 2566698494 FusedOutput18 6034;
BA_ "SPN" SG_ 2566698494 FusedOutput17 6035;
BA_ "SPN" SG_ 2566698494 FusedOutput24 6036;
BA_ "SPN" SG_ 2566698494 FusedOutput23 6037;
BA_ "SPN" SG_ 2566698494 FusedOutput22 6038;
BA_ "SPN" SG_ 2566698494 FusedOutput21 6039;
BA_ "SPN" SG_ 2566698494 FusedOutput28 6040;
BA_ "SPN" SG_ 2566698494 FusedOutput27 6041;
BA_ "SPN" SG_ 2566698494 FusedOutput26 6042;
BA_ "SPN" SG_ 2566698494 FusedOutput25 6043;
BA_ "SPN" SG_ 2566698494 FusedOutput32 6044;
BA_ "SPN" SG_ 2566698494 FusedOutput31 6045;
BA_ "SPN" SG_ 2566698494 FusedOutput30 6046;
BA_ "SPN" SG_ 2566698494 FusedOutput29 6047;
BA_ "SPN" SG_ 2566698750 SLIBatteryPackStateOfCharge 5981;
BA_ "SPN" SG_ 2566698750 SLIBatteryPackCapacity 5982;
BA_ "SPN" SG_ 2566698750 SLIBatteryPackHealth 5983;
BA_ "SPN" SG_ 2566698750 SLICrnkngPredictMinBattryVoltage 7497;
BA_ "SPN" SG_ 2566699006 HybridBatteryPackRemainingCharge 5464;
BA_ "SPN" SG_ 2566699006 HybridSysEngStopStrtRemnPrcntage 8558;
BA_ "SPN" SG_ 2566699262 Aft2DslPFTmeToNextActvRegen 5979;
BA_ "SPN" SG_ 2566699262 Aft2SCRSysTmeSncLastSysCleanEvnt 6948;
BA_ "SPN" SG_ 2566699518 Aft1DslPFTmeToNextActvRegen 5978;
BA_ "SPN" SG_ 2566699518 Aft1SCRSysTmeSncLastSysCleanEvnt 6941;
BA_ "SPN" SG_ 2566699774 Aft2DslExhstFldCtrlMdulRelayCtrl 5967;
BA_ "SPN" SG_ 2566699774 Aft2DslExhstFldCtrlMdulPwrSupply 5968;
BA_ "SPN" SG_ 2566699774 Aft2DslExhstFldCtrlMdulPwrSuply2 6310;
BA_ "SPN" SG_ 2566699774 Aft2DslExhstFldCtrlMdulCircBrkr 8483;
BA_ "SPN" SG_ 2566699774 Aft2DslExhstFldCtrlMdul2RelyCtrl 7532;
BA_ "SPN" SG_ 2566699774 Aft2DslExhstFldCtrlMdul2PwrSupp1 7533;
BA_ "SPN" SG_ 2566699774 Aft2DslExhstFldCtrlMdul2PwrSupp2 7534;
BA_ "SPN" SG_ 2566700030 Aft1DslExhstFldCtrlMdulRelayCtrl 5965;
BA_ "SPN" SG_ 2566700030 Aft1DslExhstFldCtrlMdulPwrSupply 5966;
BA_ "SPN" SG_ 2566700030 Aft1DslExhstFldCtrlMdulPwrSuply2 6309;
BA_ "SPN" SG_ 2566700030 Aft1DslExhstFldCtrlMdulCircBrkr 7417;
BA_ "SPN" SG_ 2566700030 Aft1DslExhstFldCtrlMdul2RelyCtrl 7521;
BA_ "SPN" SG_ 2566700030 Aft1DslExhstFldCtrlMdul2PwrSupp1 7522;
BA_ "SPN" SG_ 2566700030 Aft1DslExhstFldCtrlMdul2PwrSupp2 7523;
BA_ "SPN" SG_ 2566700286 Aftrtrtmnt2TotalDslExhstFldUsed 5964;
BA_ "SPN" SG_ 2566700542 Aftrtrtmnt1TotalDslExhstFldUsed 5963;
BA_ "SPN" SG_ 2566700542 AftrtrtmntTripDieselExhaustFluid 6563;
BA_ "SPN" SG_ 2365374206 DualCltchTrnsmInputShft1Spd 5960;
BA_ "SPN" SG_ 2365374206 DualCltchTrnsmInputShft2Spd 5961;
BA_ "SPN" SG_ 2365374206 DualCltchTrnsmSelPreSelctionGear 5957;
BA_ "SPN" SG_ 2365374206 DualCltchTrnsmCurrPreSlctionGear 5958;
BA_ "SPN" SG_ 2499592190 TransmissionClutch1ActrPercent 5944;
BA_ "SPN" SG_ 2499592190 TransmissionClutch2ActrPercent 5945;
BA_ "SPN" SG_ 2499592190 TransmissionHydrPumpActr1Percent 5946;
BA_ "SPN" SG_ 2499592190 TransmissionShiftActr1Percent 5947;
BA_ "SPN" SG_ 2499592190 TransmissionShiftActr2Percent 5948;
BA_ "SPN" SG_ 2499592190 TrnsmCltch1CoolingActrStat 5949;
BA_ "SPN" SG_ 2499592190 TrnsmCltch2CoolingActrStat 5950;
BA_ "SPN" SG_ 2499592190 TransmissionShiftRail1ActrStatus 5951;
BA_ "SPN" SG_ 2499592190 TransmissionShiftRail2ActrStatus 5952;
BA_ "SPN" SG_ 2499592190 TransmissionShiftRail3ActrStatus 5953;
BA_ "SPN" SG_ 2499592190 TransmissionShiftRail4ActrStatus 5954;
BA_ "SPN" SG_ 2499592190 TransmissionShiftRail5ActrStatus 5955;
BA_ "SPN" SG_ 2499592190 TransmissionShiftRail6ActrStatus 5956;
BA_ "SPN" SG_ 2499592190 TransmissionHydrPumpActr2Percent 6582;
BA_ "SPN" SG_ 2499592446 TransmissionShiftRail1Position 4218;
BA_ "SPN" SG_ 2499592446 TransmissionShiftRail2Position 4219;
BA_ "SPN" SG_ 2499592446 TransmissionShiftRail3Position 4220;
BA_ "SPN" SG_ 2499592446 TransmissionShiftRail4Position 5941;
BA_ "SPN" SG_ 2499592446 TransmissionShiftRail5Position 5942;
BA_ "SPN" SG_ 2499592446 TransmissionShiftRail6Position 5943;
BA_ "SPN" SG_ 2566701566 TransmissionClutch2Pressure 5937;
BA_ "SPN" SG_ 2566701566 TrnsmOilTransmissionCoolOtltTemp 5938;
BA_ "SPN" SG_ 2566701822 HybridSystemWarningIndicator 5872;
BA_ "SPN" SG_ 2566701822 HybridSystemOverheatIndicator 5873;
BA_ "SPN" SG_ 2566701822 HybridSystemStopIndicator 5874;
BA_ "SPN" SG_ 2566701822 HybridSystemOBDRelatedDTCStatus 6810;
BA_ "SPN" SG_ 2566701822 PropulsionSystemActive 7315;
BA_ "SPN" SG_ 2566701822 HybridSystemEngineAssistStatus 7418;
BA_ "SPN" SG_ 2566701822 HybridSystemServiceIndicator 7448;
BA_ "SPN" SG_ 2566701822 HybridSystemMtrOverspeedIndictr 7449;
BA_ "SPN" SG_ 2566701822 HybridSysMtrOverspdAudibleAlarm 7450;
BA_ "SPN" SG_ 2566701822 HybridSysElectricAltrntrIndictr 7451;
BA_ "SPN" SG_ 2566701822 HybridSystemRegativeBrkngIndictr 7452;
BA_ "SPN" SG_ 2566701822 HybridSystemInitIndictr 7453;
BA_ "SPN" SG_ 2566701822 HybridSysHghVltgExposureIndictr 7454;
BA_ "SPN" SG_ 2566701822 StoredEnergySourceOnlyModeAllwd 7893;
BA_ "SPN" SG_ 2566701822 StoredEnergySrcIncreasngMdeAllwd 7894;
BA_ "SPN" SG_ 2566701822 StoredEnergySourceLevel 7895;
BA_ "SPN" SG_ 2566701822 HybridPropulsionModeStatus 7896;
BA_ "SPN" SG_ 2566701822 HybridProplsnMdeTransitionStatus 7897;
BA_ "SPN" SG_ 2566701822 ExtEnergySourceConnectnStatus 7898;
BA_ "SPN" SG_ 2566701822 HybridSystemProplsnDisablStatus 8267;
BA_ "SPN" SG_ 2566702078 SupplyGasMethanePercentage 5867;
BA_ "SPN" SG_ 2566702334 Aftrtrtmnt2SCRIntrmedTemperature 5864;
BA_ "SPN" SG_ 2566702334 Aft2SCRIntrmedTempPrelimFMI 5865;
BA_ "SPN" SG_ 2566702590 Aftrtrtmnt1SCRIntrmedTemperature 5862;
BA_ "SPN" SG_ 2566702590 Aft1SCRIntrmedTempPrelimFMI 5863;
BA_ "SPN" SG_ 2566702846 EngineOBDWarmUpSequence 5843;
BA_ "SPN" SG_ 2566703102 ModelYear 5844;
BA_ "SPN" SG_ 2566703102 CertificationEngineFamilyName 5845;
BA_ "SPN" SG_ 2566703358 FeedbackEngineFuelingState 5794;
BA_ "SPN" SG_ 2566703358 EngineFuelingInhibitAllowed 5795;
BA_ "SPN" SG_ 2566703358 EngFuelingInhibitPreventedReason 5866;
BA_ "SPN" SG_ 2566703358 SrcAddrOfCtlngDevForFuelngStat 6307;
BA_ "SPN" SG_ 2566703358 EngineDualFuelMode 6791;
BA_ "SPN" SG_ 2566703358 EngFuelngInhbtPrevntdRsnExtsion 8145;
BA_ "SPN" SG_ 2566703358 EngGasSubstitutionFuelPercentage 6333;
BA_ "SPN" SG_ 2566703358 EngineFuelingInhibitRequestCount 6896;
BA_ "SPN" SG_ 2566703358 EngineFuelingDesiredRequestCount 6897;
BA_ "SPN" SG_ 2566703614 EngineThrottleValve1Temperature 5783;
BA_ "SPN" SG_ 2566703614 EngineThrottleValve2Temperature 5784;
BA_ "SPN" SG_ 2566703614 EngineFuelValve1Temperature 5785;
BA_ "SPN" SG_ 2566703614 EngineFuelValve2Temperature 5786;
BA_ "SPN" SG_ 2566703614 EngTurboWastegateActr2Temp 5787;
BA_ "SPN" SG_ 2566703614 EngFuelRackFuelSupplyTemperature 7314;
BA_ "SPN" SG_ 2566703614 EngineThrottleValve1Position2 6650;
BA_ "SPN" SG_ 2566703870 EngExhstGasRecirc2Actr1PrelimFMI 5773;
BA_ "SPN" SG_ 2566703870 EngExhstGasRecirc2Actr1TempStat 5774;
BA_ "SPN" SG_ 2566703870 EngExhstGasRecirc2Actr1Temp 5775;
BA_ "SPN" SG_ 2566703870 EngExhstGasRecirc2Actr1DsrdPos 5776;
BA_ "SPN" SG_ 2566703870 EngExhstGasRecirc2Actr2PrelimFMI 5777;
BA_ "SPN" SG_ 2566703870 EngExhstGasRecirc2Actr2TempStat 5778;
BA_ "SPN" SG_ 2566703870 EngExhstGasRecirc2Actr2Temp 5779;
BA_ "SPN" SG_ 2566703870 EngExhstGasRecirc2Actr2DsrdPos 5780;
BA_ "SPN" SG_ 2566703870 EngExhstGasRecirc2Actr1OpStatus 5781;
BA_ "SPN" SG_ 2566703870 EngExhstGasRecirc2Actr2OpStatus 5782;
BA_ "SPN" SG_ 2566704126 EngExhstGasRecirc1Actr1PrelimFMI 5763;
BA_ "SPN" SG_ 2566704126 EngExhstGasRecirc1Actr1TempStat 5764;
BA_ "SPN" SG_ 2566704126 EngExhstGasRecirc1Actr1Temp 5765;
BA_ "SPN" SG_ 2566704126 EngExhstGasRecirc1Actr1DsrdPos 5766;
BA_ "SPN" SG_ 2566704126 EngExhstGasRecirc1Actr2PrelimFMI 5767;
BA_ "SPN" SG_ 2566704126 EngExhstGasRecirc1Actr2TempStat 5768;
BA_ "SPN" SG_ 2566704126 EngExhstGasRecirc1Actr2Temp 5769;
BA_ "SPN" SG_ 2566704126 EngExhstGasRecirc1Actr2DsrdPos 5770;
BA_ "SPN" SG_ 2566704126 EngExhstGasRecirc1Actr1OpStatus 5771;
BA_ "SPN" SG_ 2566704126 EngExhstGasRecirc1Actr2OpStatus 5772;
BA_ "SPN" SG_ 2566704382 Aftrtrtmnt1IntkGasSnsrPwrSupply 5758;
BA_ "SPN" SG_ 2566704382 Aftrtrtmnt1OtltGasSnsrPwrSupply 5759;
BA_ "SPN" SG_ 2566704382 Aftrtrtmnt2IntkGasSnsrPwrSupply 5760;
BA_ "SPN" SG_ 2566704382 Aftrtrtmnt2OtltGasSnsrPwrSupply 5761;
BA_ "SPN" SG_ 2566704382 Aftrtrtmnt1Intk2GsSnsrPwrSupply 8146;
BA_ "SPN" SG_ 2566704382 Aftrtrtmnt1Otlt2GsSnsrPwrSupply 8147;
BA_ "SPN" SG_ 2566705150 Aft1OtltNOxSnsrSelfDiagssTrigger 5709;
BA_ "SPN" SG_ 2566705150 Aft1IntkNOxSnsrSelfDiagssTrigger 5710;
BA_ "SPN" SG_ 2566705150 Aft2OtltNOxSnsrSelfDiagssTrigger 5711;
BA_ "SPN" SG_ 2566705150 Aft2IntkNOxSnsrSelfDiagssTrigger 5712;
BA_ "SPN" SG_ 2566705406 Aftertreatment1ParticulateSensor 5835;
BA_ "SPN" SG_ 2566705406 Aftertreatment2ParticulateSensor 5836;
BA_ "SPN" SG_ 2566705406 Aftrtrtmnt1ParticulateSensorCurr 7393;
BA_ "SPN" SG_ 2566705662 ProtectLamp 987;
BA_ "SPN" SG_ 2566705662 AmberWarningLamp 624;
BA_ "SPN" SG_ 2566705662 RedStopLamp 623;
BA_ "SPN" SG_ 2566705662 MalfunctionIndicatorLamp 1213;
BA_ "SPN" SG_ 2566705662 FlashProtectLamp 3041;
BA_ "SPN" SG_ 2566705662 FlashAmberWarningLamp 3040;
BA_ "SPN" SG_ 2566705662 FlashRedStopLamp 3039;
BA_ "SPN" SG_ 2566705662 FlashMalfunctionIndicatorLamp 3038;
BA_ "SPN" SG_ 2566705662 SuspectParameterNumber 1214;
BA_ "SPN" SG_ 2566705662 FailureModeIdentifier 1215;
BA_ "SPN" SG_ 2566705662 OccurrenceCount 1216;
BA_ "SPN" SG_ 2566705662 SPNConversionMethod 1706;
BA_ "SPN" SG_ 2566705918 ProtectLamp 987;
BA_ "SPN" SG_ 2566705918 AmberWarningLamp 624;
BA_ "SPN" SG_ 2566705918 RedStopLamp 623;
BA_ "SPN" SG_ 2566705918 MalfunctionIndicatorLamp 1213;
BA_ "SPN" SG_ 2566705918 FlashProtectLamp 3041;
BA_ "SPN" SG_ 2566705918 FlashRedStopLamp 3039;
BA_ "SPN" SG_ 2566705918 FlashMalfunctionIndicatorLamp 3038;
BA_ "SPN" SG_ 2566705918 SuspectParameterNumber 1214;
BA_ "SPN" SG_ 2566705918 FailureModeIdentifier 1215;
BA_ "SPN" SG_ 2566705918 OccurrenceCount 1216;
BA_ "SPN" SG_ 2566705918 SPNConversionMethod 1706;
BA_ "SPN" SG_ 2566706686 Aftrtrtmnt1DslExhstFldPumpHeater 5706;
BA_ "SPN" SG_ 2566706686 Aftrtrtmnt1DslExhstFldPmp2MtrSpd 7461;
BA_ "SPN" SG_ 2566706686 Aft1DslExhstFldDsngUnit1HtrRely 5746;
BA_ "SPN" SG_ 2566706686 Aftrtrtmnt1DslExhstFldPmpPwrSupp 8474;
BA_ "SPN" SG_ 2566706942 Aft1DslPF2SootSnsrAnalyFreq3 5652;
BA_ "SPN" SG_ 2566706942 Aft1DslPF2SootSnsrFreq3SootSig 5653;
BA_ "SPN" SG_ 2566706942 Aft1DslPF2SootSnsrAnalyFreq4 5654;
BA_ "SPN" SG_ 2566706942 Aft1DslPF2SootSnsrFreq4SootSig 5655;
BA_ "SPN" SG_ 2566707198 Aft1DslPF2SootSnsrAnalyFreq1 5648;
BA_ "SPN" SG_ 2566707198 Aft1DslPF2SootSnsrFreq1SootSig 5649;
BA_ "SPN" SG_ 2566707198 Aft1DslPF2SootSnsrAnalyFreq2 5650;
BA_ "SPN" SG_ 2566707198 Aft1DslPF2SootSnsrFreq2SootSig 5651;
BA_ "SPN" SG_ 2566707454 Aft1DslPF2SootSnsrAnalyRqFreq1 5644;
BA_ "SPN" SG_ 2566707454 Aft1DslPF2SootSnsrAnalyRqFreq2 5645;
BA_ "SPN" SG_ 2566707454 Aft1DslPF2SootSnsrAnalyRqFreq3 5646;
BA_ "SPN" SG_ 2566707454 Aft1DslPF2SootSnsrAnalyRqFreq4 5647;
BA_ "SPN" SG_ 2566707710 Aft1DslPF1SootSnsrAnalyFreq3 5640;
BA_ "SPN" SG_ 2566707710 Aft1DslPF1SootSnsrFreq3SootSig 5641;
BA_ "SPN" SG_ 2566707710 Aft1DslPF1SootSnsrAnalyFreq4 5642;
BA_ "SPN" SG_ 2566707710 Aft1DslPF1SootSnsrFreq4SootSig 5643;
BA_ "SPN" SG_ 2566707966 Aft1DslPF1SootSnsrAnalyFreq1 5636;
BA_ "SPN" SG_ 2566707966 Aft1DslPF1SootSnsrFreq1SootSig 5637;
BA_ "SPN" SG_ 2566707966 Aft1DslPF1SootSnsrAnalyFreq2 5638;
BA_ "SPN" SG_ 2566707966 Aft1DslPF1SootSnsrFreq2SootSig 5639;
BA_ "SPN" SG_ 2566708222 Aft1DslPF1SootSnsrAnalyRqFreq1 5632;
BA_ "SPN" SG_ 2566708222 Aft1DslPF1SootSnsrAnalyRqFreq2 5633;
BA_ "SPN" SG_ 2566708222 Aft1DslPF1SootSnsrAnalyRqFreq3 5634;
BA_ "SPN" SG_ 2566708222 Aft1DslPF1SootSnsrAnalyRqFreq4 5635;
BA_ "SPN" SG_ 2566708478 AdaptiveCruiseCtrlReadinessStat 5606;
BA_ "SPN" SG_ 2566708478 CruiseControlSystemCommandState 5607;
BA_ "SPN" SG_ 2566708478 PredictCrsCtrlSetSpdOffstStatus 7318;
BA_ "SPN" SG_ 2566708478 SrcAddrCtlngDevDisablCruiseCtrl 5608;
BA_ "SPN" SG_ 2566708478 SrcAddrCtlngDevPausingCruiseCtrl 5609;
BA_ "SPN" SG_ 2566708478 AEBSReadinessState 6208;
BA_ "SPN" SG_ 2566708478 CrsCtrlDriverCancellationStatus 7836;
BA_ "SPN" SG_ 2566708478 CruiseControlSetSpeed 6809;
BA_ "SPN" SG_ 2566708478 CruiseControlSpeed 7319;
BA_ "SPN" SG_ 2566708734 Aftrtrtmnt2SecondaryAirAbsPress 5590;
BA_ "SPN" SG_ 2566708990 Aftrtrtmnt1SecondaryAirAbsPress 5589;
BA_ "SPN" SG_ 2566709246 EngineFuelDeliveryAbsPressure 5578;
BA_ "SPN" SG_ 2566709246 EngFilteredFuelDeliveryPressure 5579;
BA_ "SPN" SG_ 2566709246 EngFilteredFuelDeliveryAbsPress 5580;
BA_ "SPN" SG_ 2566709246 EngineFuelFilterDegradation 5584;
BA_ "SPN" SG_ 2566709246 EngineFuelReturnPressure 6816;
BA_ "SPN" SG_ 2566709246 EngineThrottleValve2DiffPressure 7595;
BA_ "SPN" SG_ 2566709246 EngFuelSupplyPumpIntkAbsPressure 7472;
BA_ "SPN" SG_ 2566709502 Aft1DslPFIntkTemperatuRstPoint 5501;
BA_ "SPN" SG_ 2566709502 EngineUnburnedFuelPercentage 5502;
BA_ "SPN" SG_ 2566709502 Aftertreatment1FuelMassRate 5503;
BA_ "SPN" SG_ 2566709502 Aftertreatment2FuelMassRate 5834;
BA_ "SPN" SG_ 2566709758 EngineFuelRate 1600;
BA_ "SPN" SG_ 2566709758 EngineDieselFuelDemandRate 7596;
BA_ "SPN" SG_ 2566710014 SupplementalFanEnableStatus 5556;
BA_ "SPN" SG_ 2566710014 SupplementalFanDirectionStatus 5557;
BA_ "SPN" SG_ 2566710014 SupplementalFanVelocityStatus 5558;
BA_ "SPN" SG_ 2566710014 SupplementalFanCtrllerTempStat 5559;
BA_ "SPN" SG_ 2566710014 SupplementalFanDriveStatus 5560;
BA_ "SPN" SG_ 2566710014 SupplementalFanCtrllerECUTemp 5561;
BA_ "SPN" SG_ 2566710014 SupplementalFanSpeed 5562;
BA_ "SPN" SG_ 2566710014 SupplementalFanCurrent 5563;
BA_ "SPN" SG_ 2566710014 SupplementalFanPower 5564;
BA_ "SPN" SG_ 2432492542 EngTurbocharger1TurbineOtltPress 5541;
BA_ "SPN" SG_ 2432492542 EngTurbo1TurbineDsrdOtltPress 5542;
BA_ "SPN" SG_ 2432492542 EngineExhaustBrakeActrCommand 5543;
BA_ "SPN" SG_ 2432492542 EngTurbocharger2TurbineOtltPress 5544;
BA_ "SPN" SG_ 2432492542 EngTurbo2TurbineDsrdOtltPress 5545;
BA_ "SPN" SG_ 2566710526 EngineFuelDynamicViscosity 5537;
BA_ "SPN" SG_ 2566710526 EngineFuelDensity 5538;
BA_ "SPN" SG_ 2566710526 EngineFuelDielectricity 5539;
BA_ "SPN" SG_ 2566710526 EngineFuelTemperature 5540;
BA_ "SPN" SG_ 2566710782 HydraulicOilDynamicViscosity 5533;
BA_ "SPN" SG_ 2566710782 HydraulicOilDensity 5534;
BA_ "SPN" SG_ 2566710782 HydrOilRelativeDielectricity 5535;
BA_ "SPN" SG_ 2566710782 HydraulicOilTemperature 5536;
BA_ "SPN" SG_ 2566711038 LubricationCycleModeLockStatus 5515;
BA_ "SPN" SG_ 2566711038 LubricationCycleModeStatus 5516;
BA_ "SPN" SG_ 2566711038 LubricationOperationModeStatus 5517;
BA_ "SPN" SG_ 2566711038 LubricationPumpEnableStatus 5518;
BA_ "SPN" SG_ 2566711038 LubricationReservoirLevel 5519;
BA_ "SPN" SG_ 2566711038 LubricationTimingCycleStatus 5520;
BA_ "SPN" SG_ 2566711294 EngFrictionPrcntTrqAtIdl_Point1 5471;
BA_ "SPN" SG_ 2566711294 EngFrictionPercentTorque_Point2 5472;
BA_ "SPN" SG_ 2566711294 EngFrictionPercentTorque_Point3 5473;
BA_ "SPN" SG_ 2566711294 EngFrictionPercentTorque_Point4 5474;
BA_ "SPN" SG_ 2566711294 EngFrictionPercentTorque_Point5 5475;
BA_ "SPN" SG_ 2566711294 EngFrictionPercentTorque_Point6 5476;
BA_ "SPN" SG_ 2566711294 EngFrictionPercentTorque_Point7 5477;
BA_ "SPN" SG_ 2566711550 IntkVlvActSysOilPrs1SolenoidCtrl 5499;
BA_ "SPN" SG_ 2566711550 IntkVlvActSysOilPrs2SolenoidCtrl 5500;
BA_ "SPN" SG_ 2566711806 Armrest1Switch1 1503;
BA_ "SPN" SG_ 2566711806 Armrest1Switch2 5492;
BA_ "SPN" SG_ 2566711806 Armrest2Switch1 5493;
BA_ "SPN" SG_ 2566711806 Armrest2Switch2 5494;
BA_ "SPN" SG_ 2566712318 Aftrtrtmnt2NOxAdsorberRegenStat 5460;
BA_ "SPN" SG_ 2566712318 Aft2NOxAdsorberDesulfationStat 5462;
BA_ "SPN" SG_ 2566712574 Aftrtrtmnt1NOxAdsorberRegenStat 5459;
BA_ "SPN" SG_ 2566712574 Aft1NOxAdsorberDesulfationStat 5461;
BA_ "SPN" SG_ 2566712830 Aft2WarmUpDslOxidtnCtlystIntkTmp 5315;
BA_ "SPN" SG_ 2566712830 Aft2WarmUpDslOxidtnCtlystOtltTmp 5316;
BA_ "SPN" SG_ 2499604222 BladeElevationDeviationLeft 5410;
BA_ "SPN" SG_ 2499604222 BladeElevationDeviationRight 5411;
BA_ "SPN" SG_ 2499604222 BldReferenceElevationOffsetLeft 5412;
BA_ "SPN" SG_ 2499604222 BldReferenceElevationOffsetRight 5413;
BA_ "SPN" SG_ 2499604478 EngExhstGasRecirc1IntkAbsPress 5430;
BA_ "SPN" SG_ 2499604478 EngExhstGasRecirc1OtltAbsPress 5431;
BA_ "SPN" SG_ 2499604478 EngineOilPressure 7468;
BA_ "SPN" SG_ 2499604478 EngineFuelDeliveryPressure 7469;
BA_ "SPN" SG_ 2566713598 EngFuelFilterIntakeAbsPressure 5417;
BA_ "SPN" SG_ 2566713598 EngineFuelFilterDegradation 6716;
BA_ "SPN" SG_ 2566713598 FuelTankTransferPump 4010;
BA_ "SPN" SG_ 2566713598 FuelTankTransferPumpPressure 7395;
BA_ "SPN" SG_ 2566713854 EngTurboWastegateActr2PrelimFMI 5384;
BA_ "SPN" SG_ 2566713854 EngTurboWastegateActr2TempStat 5385;
BA_ "SPN" SG_ 2566713854 EngTurboWastegateActr1OpStat 5451;
BA_ "SPN" SG_ 2566713854 EngTurboWastegateActr2OpStat 5452;
BA_ "SPN" SG_ 2566713854 EngExhstPressureRegulatorPos 5625;
BA_ "SPN" SG_ 2566713854 EngExhstPressRegulatorPrelimFMI 5626;
BA_ "SPN" SG_ 2566713854 EngExhstPressRgltrTempStat 5627;
BA_ "SPN" SG_ 2566713854 EngExhstPressRgltrCtrlOpStatus 5628;
BA_ "SPN" SG_ 2566713854 EngTurboWastegateActr1Temp 5788;
BA_ "SPN" SG_ 2566713854 EngExhstPressureActr1DsrdPos 5789;
BA_ "SPN" SG_ 2566713854 EngExhstPressureActr1Temperature 5790;
BA_ "SPN" SG_ 2566714110 EngineDsrdThrottleValve1Position 5374;
BA_ "SPN" SG_ 2566714110 EngThrottleValve1PreliminaryFMI 5375;
BA_ "SPN" SG_ 2566714110 EngThrottleValve1TemperatureStat 5376;
BA_ "SPN" SG_ 2566714110 EngineDsrdThrottleValve2Position 5377;
BA_ "SPN" SG_ 2566714110 EngThrottleValve2PreliminaryFMI 5378;
BA_ "SPN" SG_ 2566714110 EngThrottleValve2TemperatureStat 5379;
BA_ "SPN" SG_ 2566714110 EngineFuelValve1PreliminaryFMI 5380;
BA_ "SPN" SG_ 2566714110 EngFuelValve1TemperatureStatus 5381;
BA_ "SPN" SG_ 2566714110 EngineFuelValve2PreliminaryFMI 5382;
BA_ "SPN" SG_ 2566714110 EngFuelValve2TemperatureStatus 5383;
BA_ "SPN" SG_ 2566714110 EngThrottleValve1OperationStatus 5445;
BA_ "SPN" SG_ 2566714110 EngThrottleValve2OperationStatus 5446;
BA_ "SPN" SG_ 2566714110 EngineFuelValve1OperationStatus 5447;
BA_ "SPN" SG_ 2566714110 EngineFuelValve2OperationStatus 5448;
BA_ "SPN" SG_ 2566714366 EngTurboCmprssorBypssActr2Pos 5388;
BA_ "SPN" SG_ 2566714366 EngTurboCmprBypssActr2DsrdPos 5389;
BA_ "SPN" SG_ 2566714366 EngTurboCmprBypssActr2PrelimFMI 5390;
BA_ "SPN" SG_ 2566714366 EngTurboCmprBypssActr2TempStat 5391;
BA_ "SPN" SG_ 2566714366 EngTurboCmprssorBypssActr1OpStat 5449;
BA_ "SPN" SG_ 2566714366 EngTurboCmprssorBypssActr2OpStat 5450;
BA_ "SPN" SG_ 2566714366 EngTurboCmprssorBypssActr1Temp 5791;
BA_ "SPN" SG_ 2566714366 EngTurboCmprssorBypssActr2Temp 5792;
BA_ "SPN" SG_ 2566714622 EngChargeAirCool2IntkTemperature 5289;
BA_ "SPN" SG_ 2566714622 EngChargeAirCool2OtltTemperature 5290;
BA_ "SPN" SG_ 2566714622 EngChargeAirCool2AmbientAirTemp 5291;
BA_ "SPN" SG_ 2566714622 EngineChargeAirCooler2Efficiency 5292;
BA_ "SPN" SG_ 2566714878 EngChargeAirCool2PreCoolIntkTemp 5286;
BA_ "SPN" SG_ 2566714878 EngChargeAirCool2PreCoolOtltTemp 5287;
BA_ "SPN" SG_ 2566714878 EngineChargeAirCool2PreCoolEff 5288;
BA_ "SPN" SG_ 2566715134 EngChargeAirCool1IntkTemperature 5283;
BA_ "SPN" SG_ 2566715134 EngChargeAirCool1AmbientAirTemp 5284;
BA_ "SPN" SG_ 2566715134 EngineChargeAirCooler1Efficiency 5285;
BA_ "SPN" SG_ 2566715390 EngChargeAirCool1PreCoolIntkTemp 5280;
BA_ "SPN" SG_ 2566715390 EngChargeAirCool1PreCoolOtltTemp 5281;
BA_ "SPN" SG_ 2566715390 EngineChargeAirCool1PreCoolEff 5282;
BA_ "SPN" SG_ 2566715646 Aftrtrtmnt2DslPFSootSigStdDviat 5269;
BA_ "SPN" SG_ 2566715646 Aftrtrtmnt2DslPFSootSignalMax 5270;
BA_ "SPN" SG_ 2566715646 Aftrtrtmnt2DslPFSootSignalMin 5271;
BA_ "SPN" SG_ 2566715902 Aftrtrtmnt1DslPFSootSigStdDviat 5266;
BA_ "SPN" SG_ 2566715902 Aftrtrtmnt1DslPFSootSignalMax 5267;
BA_ "SPN" SG_ 2566715902 Aftrtrtmnt1DslPFSootSignalMin 5268;
BA_ "SPN" SG_ 2633825022 EngExhstGasRecirc2Valve1Ctrl 5264;
BA_ "SPN" SG_ 2633825022 EngExhstGasRecirc2Valve2Ctrl 5265;
BA_ "SPN" SG_ 2633825022 EngExhstGasRecirc2Valve1PosError 5831;
BA_ "SPN" SG_ 2633825022 EngExhstGasRecirc2Valve2PosError 5832;
BA_ "SPN" SG_ 2499607550 EngExhstMnfldBnk1FlwBalVlvActrPs 5277;
BA_ "SPN" SG_ 2499607550 EngExhstMnfldBnk2FlwBalVlvActrPs 5279;
BA_ "SPN" SG_ 2633825534 EngExhstMfBnk1FlwBalVlvActrCtrl 5276;
BA_ "SPN" SG_ 2633825534 EngExhstMfBnk2FlwBalVlvActrCtrl 5278;
BA_ "SPN" SG_ 2432499198 EngExhstGasRecirc2ValvePos 5262;
BA_ "SPN" SG_ 2432499198 EngExhstGasRecirc2Valve2Pos 5263;
BA_ "SPN" SG_ 2432499198 CommandedEngineFuelRailPressure 5313;
BA_ "SPN" SG_ 2432499198 CmdedEngFuelInjectionCtrlPress 5314;
BA_ "SPN" SG_ 2633826046 EngExhstGasRecirc2CoolIntkTemp 5258;
BA_ "SPN" SG_ 2633826046 EngExhstGsRecirc2ClIntkGsAbsPrs 5259;
BA_ "SPN" SG_ 2633826046 EngExhstGasRecirculation2CoolEff 5260;
BA_ "SPN" SG_ 2633826046 EngExhstGasRecirc2ClBypssActrPos 5261;
BA_ "SPN" SG_ 2566717438 EngExhstGasRecirc2Temperature 5255;
BA_ "SPN" SG_ 2566717438 EngExhstGasRecirc2MixerIntkTemp 5256;
BA_ "SPN" SG_ 2499608830 EngExhstGasRecirc2DiffPress 5252;
BA_ "SPN" SG_ 2499608830 EngExhstGasRecirc2IntkPress 5253;
BA_ "SPN" SG_ 2499608830 EngExhstGasRecirc2OtltAbsPress 5254;
BA_ "SPN" SG_ 2499608830 EngExhstGasRecirc2IntkAbsPress 5429;
BA_ "SPN" SG_ 2499608830 EngineCoolantPressure2 5708;
BA_ "SPN" SG_ 2566717950 LowVltgDiscnnctManDiscnnctStat 5141;
BA_ "SPN" SG_ 2566717950 LowVoltageDiscnnctManConnectStat 5142;
BA_ "SPN" SG_ 2566717950 LowVltgDiscnnctCurrentOprtngMde 5143;
BA_ "SPN" SG_ 2566717950 LowVoltageDisconnectOutput3State 5144;
BA_ "SPN" SG_ 2566717950 LowVoltageDisconnectOutput2State 5145;
BA_ "SPN" SG_ 2566717950 LowVoltageDisconnectOutput1State 5146;
BA_ "SPN" SG_ 2566717950 LowVoltageDiscnnctVoutOutptState 5147;
BA_ "SPN" SG_ 2566717950 LowVoltageDisconnectTemperature 5148;
BA_ "SPN" SG_ 2566718718 VehicleBatteryVoltageLowLampData 5104;
BA_ "SPN" SG_ 2566718718 VehicleFuelLevelLowLampData 5105;
BA_ "SPN" SG_ 2566718718 VehicleAirPressureLowLampData 5106;
BA_ "SPN" SG_ 2566718718 VehicleHVACRecirculationLampData 5107;
BA_ "SPN" SG_ 2566718718 VehicleBatteryChargingLampData 5108;
BA_ "SPN" SG_ 2566718718 HillHolderLampData 1848;
BA_ "SPN" SG_ 2566718974 EngineProtectLampData 5093;
BA_ "SPN" SG_ 2566718974 EngineAmberWarningLampData 5094;
BA_ "SPN" SG_ 2566718974 EngineRedStopLampData 5095;
BA_ "SPN" SG_ 2566718974 OBDMalfunctionIndicatorLampData 5096;
BA_ "SPN" SG_ 2566718974 EngineBrakeActiveLampData 5097;
BA_ "SPN" SG_ 2566718974 ComPrsionBrkEnblSwIndictrLampDat 5098;
BA_ "SPN" SG_ 2566718974 EngineOilPressureLowLampData 5099;
BA_ "SPN" SG_ 2566718974 EngCoolntTemperatureHighLampDat 5100;
BA_ "SPN" SG_ 2566718974 EngineCoolantLevelLowLampData 5101;
BA_ "SPN" SG_ 2566718974 EngineIdleManagementActvLampData 5102;
BA_ "SPN" SG_ 2566718974 EngAirFilterRestrictionLampDat 5103;
BA_ "SPN" SG_ 2566718974 EngFuelFilterRestrictedLampDat 5470;
BA_ "SPN" SG_ 2566718974 EngCtrlModule1ReadyForUseLampDat 6202;
BA_ "SPN" SG_ 2566718974 EngCtrlModule2ReadyForUseLampDat 6203;
BA_ "SPN" SG_ 2566718974 EngCtrlModule3ReadyForUseLampDat 6204;
BA_ "SPN" SG_ 2566718974 EngineSpeedHighLampData 6711;
BA_ "SPN" SG_ 2566718974 EngineSpeedVeryHighLampData 6712;
BA_ "SPN" SG_ 2566718974 VehicleAccltnRateLimitLampData 6900;
BA_ "SPN" SG_ 2566718974 EngineWaitToStartLampData 5416;
BA_ "SPN" SG_ 2566719230 VehicleBatteryVoltageLowLampCmd 5087;
BA_ "SPN" SG_ 2566719230 VehicleFuelLevelLowLampCommand 5088;
BA_ "SPN" SG_ 2566719230 VehicleAirPressureLowLampCommand 5089;
BA_ "SPN" SG_ 2566719230 VehicleHVACRecirculationLampCmd 5090;
BA_ "SPN" SG_ 2566719230 VehicleBatteryChargingLampCmd 5091;
BA_ "SPN" SG_ 2566719230 HillHolderLampCommand 1847;
BA_ "SPN" SG_ 2566719486 EngineProtectLampCommand 5077;
BA_ "SPN" SG_ 2566719486 EngineAmberWarningLampCommand 5078;
BA_ "SPN" SG_ 2566719486 EngineRedStopLampCommand 5079;
BA_ "SPN" SG_ 2566719486 OBDMalfunctionIndicatorLampCmd 5080;
BA_ "SPN" SG_ 2566719486 EngineBrakeActiveLampCommand 5081;
BA_ "SPN" SG_ 2566719486 ComPrsionBrkEnblSwIndictrLampCmd 3987;
BA_ "SPN" SG_ 2566719486 EngineOilPressureLowLampCommand 5082;
BA_ "SPN" SG_ 2566719486 EngCoolntTemperatureHighLampCmd 5083;
BA_ "SPN" SG_ 2566719486 EngineCoolantLevelLowLampCommand 5084;
BA_ "SPN" SG_ 2566719486 EngineIdleManagementActvLampCmd 5085;
BA_ "SPN" SG_ 2566719486 EngAirFilterRestrictionLampCmd 5086;
BA_ "SPN" SG_ 2566719486 EngFuelFilterRestrictedLampCmd 5469;
BA_ "SPN" SG_ 2566719486 EngCtrlModule1ReadyForUseLampCmd 6205;
BA_ "SPN" SG_ 2566719486 EngCtrlModule2ReadyForUseLampCmd 6206;
BA_ "SPN" SG_ 2566719486 EngCtrlModule3ReadyForUseLampCmd 6207;
BA_ "SPN" SG_ 2566719486 EngineSpeedHighLampCommand 6709;
BA_ "SPN" SG_ 2566719486 EngineSpeedVeryHighLampCommand 6710;
BA_ "SPN" SG_ 2566719486 VehicleAccltnRateLimitLampCmd 6899;
BA_ "SPN" SG_ 2633828606 EngineOilViscosity 5055;
BA_ "SPN" SG_ 2633828606 EngineOilDensity 5056;
BA_ "SPN" SG_ 2633828606 EngineOilRelativeDielectricity 5468;
BA_ "SPN" SG_ 2633828606 EngineOilTemperature3 5925;
BA_ "SPN" SG_ 2566719998 EngineTripFuel 5053;
BA_ "SPN" SG_ 2566719998 EngineTotalFuelUsed 5054;
BA_ "SPN" SG_ 2365393662 Aft2OtltNOxSnsrO2PressCorrctn 5048;
BA_ "SPN" SG_ 2365393662 Aft2OtltNOxSnsrNOxPressCorrctn 5049;
BA_ "SPN" SG_ 2365393662 Aftrtrtmnt2OtltNOxSnsrNO2Corrctn 5050;
BA_ "SPN" SG_ 2365393662 Aftrtrtmnt2OtltNOxSnsrNH3Corrctn 5051;
BA_ "SPN" SG_ 2365393662 Aft2OtltNOxSnsrSelfDiagssFinalRs 5719;
BA_ "SPN" SG_ 2365393662 Aftrtrtmnt2OutletCorrectedNOx 7352;
BA_ "SPN" SG_ 2365393918 Aftrtrtmnt2OtltNOxSensorHtrRatio 5045;
BA_ "SPN" SG_ 2365393918 Aft2OtltNOxSnsrNwPrtDviatNOxGain 5046;
BA_ "SPN" SG_ 2365393918 Aft2OtltNOxSnsrNPDviatNOxOffst 5047;
BA_ "SPN" SG_ 2365393918 Aftrtrtmnt2OtltNOxSensorOpHours 5723;
BA_ "SPN" SG_ 2365394174 Aft2IntkNOxSnsrO2PressCorrctn 5041;
BA_ "SPN" SG_ 2365394174 Aft2IntkNOxSnsrNOxPressCorrctn 5042;
BA_ "SPN" SG_ 2365394174 Aftrtrtmnt2IntkNOxSnsrNO2Corrctn 5043;
BA_ "SPN" SG_ 2365394174 Aftrtrtmnt2IntkNOxSnsrNH3Corrctn 5044;
BA_ "SPN" SG_ 2365394174 Aft2IntkNOxSnsrSelfDiagssFinalRs 5720;
BA_ "SPN" SG_ 2365394174 Aftrtrtmnt2SCRIntakeCorrectedNOx 7354;
BA_ "SPN" SG_ 2365394430 Aftrtrtmnt2IntkNOxSensorHtrRatio 5038;
BA_ "SPN" SG_ 2365394430 Aft2IntkNOxSnsrNwPrtDviatNOxGain 5039;
BA_ "SPN" SG_ 2365394430 Aft2IntkNOxSnsrNPDviatNOxOffst 5040;
BA_ "SPN" SG_ 2365394430 Aftrtrtmnt2IntkNOxSensorOpHours 5724;
BA_ "SPN" SG_ 2365394686 Aft1OtltNOxSnsrO2PressCorrctn 5034;
BA_ "SPN" SG_ 2365394686 Aft1OtltNOxSnsrNOxPressCorrctn 5035;
BA_ "SPN" SG_ 2365394686 Aftrtrtmnt1OtltNOxSnsrNO2Corrctn 5036;
BA_ "SPN" SG_ 2365394686 Aftrtrtmnt1OtltNOxSnsrNH3Corrctn 5037;
BA_ "SPN" SG_ 2365394686 Aft1OtltNOxSnsrSelfDiagssFinalRs 5717;
BA_ "SPN" SG_ 2365394686 Aftrtrtmnt1OutletCorrectedNOx 7351;
BA_ "SPN" SG_ 2365394942 Aftrtrtmnt1OtltNOxSensorHtrRatio 5031;
BA_ "SPN" SG_ 2365394942 Aft1OtltNOxSnsrNwPrtDviatNOxGain 5032;
BA_ "SPN" SG_ 2365394942 Aft1OtltNOxSnsrNPDviatNOxOffst 5033;
BA_ "SPN" SG_ 2365394942 Aftrtrtmnt1OtltNOxSensorOpHours 5721;
BA_ "SPN" SG_ 2365395198 Aft1IntkNOxSnsrO2PressCorrctn 5027;
BA_ "SPN" SG_ 2365395198 Aft1IntkNOxSnsrNOxPressCorrctn 5028;
BA_ "SPN" SG_ 2365395198 Aftrtrtmnt1IntkNOxSnsrNO2Corrctn 5029;
BA_ "SPN" SG_ 2365395198 Aftrtrtmnt1IntkNOxSnsrNH3Corrctn 5030;
BA_ "SPN" SG_ 2365395198 Aft1IntkNOxSnsrSelfDiagssFinalRs 5718;
BA_ "SPN" SG_ 2365395198 Aftrtrtmnt1SCRIntakeCorrectedNOx 7353;
BA_ "SPN" SG_ 2365395454 Aftrtrtmnt1IntkNOxSensorHtrRatio 5024;
BA_ "SPN" SG_ 2365395454 Aft1IntkNOxSnsrNwPrtDviatNOxGain 5025;
BA_ "SPN" SG_ 2365395454 Aft1IntkNOxSnsrNPDviatNOxOffst 5026;
BA_ "SPN" SG_ 2365395454 Aftrtrtmnt1IntkNOxSensorOpHours 5722;
BA_ "SPN" SG_ 2566722302 GeneratorOverheatStatus 5000;
BA_ "SPN" SG_ 2566722302 GensetSystemOutptVoltageRngStat 5001;
BA_ "SPN" SG_ 2566722302 GrappleMagnetSelectionSwitch 5003;
BA_ "SPN" SG_ 2566722302 GensetSoftstartActiveStatus 5004;
BA_ "SPN" SG_ 2566722302 ReverseCurrentRangeSetting 5002;
BA_ "SPN" SG_ 2566722302 GensetEnableActiveStatus 5005;
BA_ "SPN" SG_ 2566722302 VoltageMonitorActiveStatus 5006;
BA_ "SPN" SG_ 2566722302 GeneratorDutyCycleExceededStatus 5007;
BA_ "SPN" SG_ 2566722558 MagnetBoostTime 4998;
BA_ "SPN" SG_ 2566722558 MagnetRatedPower 4999;
BA_ "SPN" SG_ 2566722814 BatteryCharger2State 4994;
BA_ "SPN" SG_ 2566722814 BatteryCharger2PowerLineState 4995;
BA_ "SPN" SG_ 2566722814 BatteryCharger2OutputVoltage 4996;
BA_ "SPN" SG_ 2566722814 BatteryCharger2OutputCurrent 4997;
BA_ "SPN" SG_ 2566723070 BatteryCharger1State 4990;
BA_ "SPN" SG_ 2566723070 BatteryCharger1PowerLineState 4991;
BA_ "SPN" SG_ 2566723070 BatteryCharger1OutputVoltage 4992;
BA_ "SPN" SG_ 2566723070 BatteryCharger1OutputCurrent 4993;
BA_ "SPN" SG_ 2499614462 DrvrOccupantClssfctnSystemStatus 4963;
BA_ "SPN" SG_ 2499614462 PassngOccupntClssfctnSystemStat 4964;
BA_ "SPN" SG_ 2499614462 OccupantClssfctnSystem3Status 4965;
BA_ "SPN" SG_ 2499614462 OccupantClssfctnSystem4Status 4966;
BA_ "SPN" SG_ 2499614462 OccupantClssfctnSystem5Status 4967;
BA_ "SPN" SG_ 2499614462 OccupantClssfctnSystem6Status 4968;
BA_ "SPN" SG_ 2499614462 OccupantClssfctnSystem7Status 4969;
BA_ "SPN" SG_ 2499614462 OccupantClssfctnSystem8Status 4970;
BA_ "SPN" SG_ 2499614462 OccupantClssfctnSystem9Status 4971;
BA_ "SPN" SG_ 2499614462 OccupantClssfctnSystem10Status 4972;
BA_ "SPN" SG_ 2499614718 DriverBeltlockStatus 4952;
BA_ "SPN" SG_ 2499614718 PassengerBeltlockStatus 4953;
BA_ "SPN" SG_ 2499614718 Beltlock3Status 4954;
BA_ "SPN" SG_ 2499614718 Beltlock4Status 4955;
BA_ "SPN" SG_ 2499614718 Beltlock5Status 4956;
BA_ "SPN" SG_ 2499614718 Beltlock6Status 4957;
BA_ "SPN" SG_ 2499614718 Beltlock7Status 4958;
BA_ "SPN" SG_ 2499614718 Beltlock8Status 4959;
BA_ "SPN" SG_ 2499614718 Beltlock9Status 4960;
BA_ "SPN" SG_ 2499614718 Beltlock10Status 4961;
BA_ "SPN" SG_ 2499614718 PassngAirbgDeActvtnSwitchStatus 4962;
BA_ "SPN" SG_ 2633832702 FrontalCollisionSensor1Type 4918;
BA_ "SPN" SG_ 2633832702 FrontalCollisionSensor2Type 4919;
BA_ "SPN" SG_ 2633832702 FrontalCollisionSensor3Type 4920;
BA_ "SPN" SG_ 2633832702 FrontalCollisionSensor4Type 4921;
BA_ "SPN" SG_ 2633832702 SideCollisionSensorFrontLeftType 4922;
BA_ "SPN" SG_ 2633832702 SideCollsnSensorMidFrontLeftType 4923;
BA_ "SPN" SG_ 2633832702 SideCollsnSensorMidRearLeftType 4924;
BA_ "SPN" SG_ 2633832702 SideCollisionSensorRearLeftType 4925;
BA_ "SPN" SG_ 2633832702 SideCollsnSensorFrontRightType 4926;
BA_ "SPN" SG_ 2633832702 SideCollsnSensorMidFrntRightType 4927;
BA_ "SPN" SG_ 2633832702 SideCollsnSensorMidRearRightType 4928;
BA_ "SPN" SG_ 2633832702 SideCollisionSensorRearRightType 4929;
BA_ "SPN" SG_ 2633832702 RearCollisionSensor1Type 4930;
BA_ "SPN" SG_ 2633832702 RearCollisionSensor2Type 4931;
BA_ "SPN" SG_ 2633832702 RearCollisionSensor3Type 4932;
BA_ "SPN" SG_ 2633832702 RearCollisionSensor4Type 4933;
BA_ "SPN" SG_ 2633832702 RolloverSensorType 4934;
BA_ "SPN" SG_ 2633832958 DrvrAirbgIgntrLp1stStageResist 4818;
BA_ "SPN" SG_ 2633832958 PassngAirbgIgntrLp1stStageResist 4819;
BA_ "SPN" SG_ 2633832958 DrvrAirbgIgntrLp2ndStageResist 4820;
BA_ "SPN" SG_ 2633832958 PassngAirbgIgntrLp2ndStageResist 4821;
BA_ "SPN" SG_ 2633832958 DrvrBeltTensionerIgntrLpResist 4822;
BA_ "SPN" SG_ 2633832958 PassngBeltTensionerIgntrLpResist 4823;
BA_ "SPN" SG_ 2633832958 SideBagIgntrLoop1LeftResistance 4824;
BA_ "SPN" SG_ 2633832958 SideBagIgntrLoop2LeftResistance 4825;
BA_ "SPN" SG_ 2633832958 SideBagIgntrLoop1RightResistance 4826;
BA_ "SPN" SG_ 2633832958 SideBagIgntrLoop2RightResistance 4827;
BA_ "SPN" SG_ 2633832958 SpecialIgnitorLoop1Resistance 4828;
BA_ "SPN" SG_ 2633832958 SpecialIgnitorLoop2Resistance 4829;
BA_ "SPN" SG_ 2633832958 SpecialIgnitorLoop3Resistance 4830;
BA_ "SPN" SG_ 2633832958 SpecialIgnitorLoop4Resistance 4831;
BA_ "SPN" SG_ 2633832958 SpecialIgnitorLoop5Resistance 4832;
BA_ "SPN" SG_ 2633832958 SpecialIgnitorLoop6Resistance 4833;
BA_ "SPN" SG_ 2633832958 SpecialIgnitorLoop7Resistance 4834;
BA_ "SPN" SG_ 2633832958 SpecialIgnitorLoop8Resistance 4835;
BA_ "SPN" SG_ 2633832958 SpecialIgnitorLoop9Resistance 4836;
BA_ "SPN" SG_ 2633832958 SpecialIgnitorLoop10Resistance 4837;
BA_ "SPN" SG_ 2633832958 SpecialIgnitorLoop11Resistance 4838;
BA_ "SPN" SG_ 2633832958 SpecialIgnitorLoop12Resistance 4839;
BA_ "SPN" SG_ 2633832958 SpecialIgnitorLoop13Resistance 4840;
BA_ "SPN" SG_ 2633832958 SpecialIgnitorLoop14Resistance 4841;
BA_ "SPN" SG_ 2633832958 SpecialIgnitorLoop15Resistance 4842;
BA_ "SPN" SG_ 2633832958 SpecialIgnitorLoop16Resistance 4843;
BA_ "SPN" SG_ 2633832958 SpecialIgnitorLoop17Resistance 4844;
BA_ "SPN" SG_ 2633832958 SpecialIgnitorLoop18Resistance 4845;
BA_ "SPN" SG_ 2633832958 SpecialIgnitorLoop19Resistance 4846;
BA_ "SPN" SG_ 2633832958 SpecialIgnitorLoop20Resistance 4847;
BA_ "SPN" SG_ 2633832958 SpecialIgnitorLoop21Resistance 4848;
BA_ "SPN" SG_ 2633832958 SpecialIgnitorLoop22Resistance 4849;
BA_ "SPN" SG_ 2633832958 SpecialIgnitorLoop23Resistance 4850;
BA_ "SPN" SG_ 2633832958 SpecialIgnitorLoop24Resistance 4851;
BA_ "SPN" SG_ 2633832958 SpecialIgnitorLoop25Resistance 4852;
BA_ "SPN" SG_ 2633832958 SpecialIgnitorLoop26Resistance 4853;
BA_ "SPN" SG_ 2633832958 SpecialIgnitorLoop27Resistance 4854;
BA_ "SPN" SG_ 2633832958 SpecialIgnitorLoop28Resistance 4855;
BA_ "SPN" SG_ 2633832958 SpecialIgnitorLoop29Resistance 4856;
BA_ "SPN" SG_ 2633832958 SpecialIgnitorLoop30Resistance 4857;
BA_ "SPN" SG_ 2633832958 SpecialIgnitorLoop31Resistance 4858;
BA_ "SPN" SG_ 2633832958 SpecialIgnitorLoop32Resistance 4859;
BA_ "SPN" SG_ 2633832958 SpecialIgnitorLoop33Resistance 4860;
BA_ "SPN" SG_ 2633832958 SpecialIgnitorLoop34Resistance 4861;
BA_ "SPN" SG_ 2633832958 SpecialIgnitorLoop35Resistance 4862;
BA_ "SPN" SG_ 2633832958 SpecialIgnitorLoop36Resistance 4863;
BA_ "SPN" SG_ 2633832958 SpecialIgnitorLoop37Resistance 4864;
BA_ "SPN" SG_ 2633832958 SpecialIgnitorLoop38Resistance 4865;
BA_ "SPN" SG_ 2633832958 SpecialIgnitorLoop39Resistance 4866;
BA_ "SPN" SG_ 2633832958 SpecialIgnitorLoop40Resistance 4867;
BA_ "SPN" SG_ 2633832958 SpecialIgnitorLoop41Resistance 4868;
BA_ "SPN" SG_ 2633832958 SpecialIgnitorLoop42Resistance 4869;
BA_ "SPN" SG_ 2633832958 SpecialIgnitorLoop43Resistance 4870;
BA_ "SPN" SG_ 2633832958 SpecialIgnitorLoop44Resistance 4871;
BA_ "SPN" SG_ 2633832958 SpecialIgnitorLoop45Resistance 4872;
BA_ "SPN" SG_ 2633832958 SpecialIgnitorLoop46Resistance 4873;
BA_ "SPN" SG_ 2633832958 SpecialIgnitorLoop47Resistance 4874;
BA_ "SPN" SG_ 2633832958 SpecialIgnitorLoop48Resistance 4875;
BA_ "SPN" SG_ 2633832958 SpecialIgnitorLoop49Resistance 4876;
BA_ "SPN" SG_ 2633832958 SpecialIgnitorLoop50Resistance 4877;
BA_ "SPN" SG_ 2633832958 SpecialIgnitorLoop51Resistance 4878;
BA_ "SPN" SG_ 2633832958 SpecialIgnitorLoop52Resistance 4879;
BA_ "SPN" SG_ 2633832958 SpecialIgnitorLoop53Resistance 4880;
BA_ "SPN" SG_ 2633832958 SpecialIgnitorLoop54Resistance 4881;
BA_ "SPN" SG_ 2633832958 SpecialIgnitorLoop55Resistance 4882;
BA_ "SPN" SG_ 2633832958 SpecialIgnitorLoop56Resistance 4883;
BA_ "SPN" SG_ 2633832958 SpecialIgnitorLoop57Resistance 4884;
BA_ "SPN" SG_ 2633832958 SpecialIgnitorLoop58Resistance 4885;
BA_ "SPN" SG_ 2633832958 SpecialIgnitorLoop59Resistance 4886;
BA_ "SPN" SG_ 2633832958 SpecialIgnitorLoop60Resistance 4887;
BA_ "SPN" SG_ 2633832958 SpecialIgnitorLoop61Resistance 4888;
BA_ "SPN" SG_ 2633832958 SpecialIgnitorLoop62Resistance 4889;
BA_ "SPN" SG_ 2633832958 SpecialIgnitorLoop63Resistance 4890;
BA_ "SPN" SG_ 2633832958 SpecialIgnitorLoop64Resistance 4891;
BA_ "SPN" SG_ 2633832958 SpecialIgnitorLoop65Resistance 4892;
BA_ "SPN" SG_ 2633832958 SpecialIgnitorLoop66Resistance 4893;
BA_ "SPN" SG_ 2633832958 SpecialIgnitorLoop67Resistance 4894;
BA_ "SPN" SG_ 2633832958 SpecialIgnitorLoop68Resistance 4895;
BA_ "SPN" SG_ 2633832958 SpecialIgnitorLoop69Resistance 4896;
BA_ "SPN" SG_ 2633832958 SpecialIgnitorLoop70Resistance 4897;
BA_ "SPN" SG_ 2633832958 SpecialIgnitorLoop71Resistance 4898;
BA_ "SPN" SG_ 2633832958 SpecialIgnitorLoop72Resistance 4899;
BA_ "SPN" SG_ 2633832958 SpecialIgnitorLoop73Resistance 4900;
BA_ "SPN" SG_ 2633832958 SpecialIgnitorLoop74Resistance 4901;
BA_ "SPN" SG_ 2633832958 SpecialIgnitorLoop75Resistance 4902;
BA_ "SPN" SG_ 2633832958 SpecialIgnitorLoop76Resistance 4903;
BA_ "SPN" SG_ 2633832958 SpecialIgnitorLoop77Resistance 4904;
BA_ "SPN" SG_ 2633832958 SpecialIgnitorLoop78Resistance 4905;
BA_ "SPN" SG_ 2633832958 SpecialIgnitorLoop79Resistance 4906;
BA_ "SPN" SG_ 2633832958 SpecialIgnitorLoop80Resistance 4907;
BA_ "SPN" SG_ 2633832958 SpecialIgnitorLoop81Resistance 4908;
BA_ "SPN" SG_ 2633832958 SpecialIgnitorLoop82Resistance 4909;
BA_ "SPN" SG_ 2633832958 SpecialIgnitorLoop83Resistance 4910;
BA_ "SPN" SG_ 2633832958 SpecialIgnitorLoop84Resistance 4911;
BA_ "SPN" SG_ 2633832958 SpecialIgnitorLoop85Resistance 4912;
BA_ "SPN" SG_ 2633832958 SpecialIgnitorLoop86Resistance 4913;
BA_ "SPN" SG_ 2633832958 SpecialIgnitorLoop87Resistance 4914;
BA_ "SPN" SG_ 2633832958 SpecialIgnitorLoop88Resistance 4915;
BA_ "SPN" SG_ 2633832958 SpecialIgnitorLoop89Resistance 4916;
BA_ "SPN" SG_ 2633832958 SpecialIgnitorLoop90Resistance 4917;
BA_ "SPN" SG_ 2566724350 Aft1WarmUpDslOxidtnCtlystIntkTmp 4809;
BA_ "SPN" SG_ 2566724350 Aft1WarmUpDslOxidtnCtlystOtltTmp 4810;
BA_ "SPN" SG_ 2566724606 Aftrtrtmnt2DslPFSootMass 4786;
BA_ "SPN" SG_ 2566724606 Aftrtrtmnt2DslPFSootDensity 4787;
BA_ "SPN" SG_ 2566724606 Aftrtrtmnt2DslPFMeanSootSignal 4788;
BA_ "SPN" SG_ 2566724606 Aftrtrtmnt2DslPFMedianSootSignal 4789;
BA_ "SPN" SG_ 2566724606 Aft2DslPFSootSnsrPrelimFMI 4790;
BA_ "SPN" SG_ 2566724606 DslPF2SootSnsrECUInternalTemp 5570;
BA_ "SPN" SG_ 2566724862 Aftrtrtmnt1DslPFSootMass 4781;
BA_ "SPN" SG_ 2566724862 Aftrtrtmnt1DslPFSootDensity 4782;
BA_ "SPN" SG_ 2566724862 Aftrtrtmnt1DslPFMeanSootSignal 4783;
BA_ "SPN" SG_ 2566724862 Aftrtrtmnt1DslPFMedianSootSignal 4784;
BA_ "SPN" SG_ 2566724862 Aft1DslPFSootSnsrPrelimFMI 4785;
BA_ "SPN" SG_ 2566724862 DslPF1SootSnsrECUInternalTemp 5569;
BA_ "SPN" SG_ 2566725118 Aftrtrtmnt13WyCtlystDiffTemp 4779;
BA_ "SPN" SG_ 2566725118 Aftrtrtmnt23WyCtlystDiffTemp 4780;
BA_ "SPN" SG_ 2566725374 Aft1GasOxidtnCtlystDiffTemp 4777;
BA_ "SPN" SG_ 2566725374 Aft2GasOxidtnCtlystDiffTemp 4778;
BA_ "SPN" SG_ 2566725630 Aft2DslOxidtnCtlystIntkTemp 4771;
BA_ "SPN" SG_ 2566725630 Aft2DslOxidtnCtlystOtltTemp 4772;
BA_ "SPN" SG_ 2566725630 Aft2DslOxidtnCtlystDiffPress 4773;
BA_ "SPN" SG_ 2566725630 Aft2DslOxidtnCatIntkTmpPrlmFMI 4774;
BA_ "SPN" SG_ 2566725630 Aft2DslOxidtnCatOtltTmpPrlmFMI 4775;
BA_ "SPN" SG_ 2566725630 Aft2DslOxidtnCatDiffPressPrlmFMI 4776;
BA_ "SPN" SG_ 2566725886 Aft1DslOxidtnCtlystIntkTemp 4765;
BA_ "SPN" SG_ 2566725886 Aft1DslOxidtnCtlystOtltTemp 4766;
BA_ "SPN" SG_ 2566725886 Aft1DslOxidtnCtlystDiffPress 4767;
BA_ "SPN" SG_ 2566725886 Aft1DslOxidtnCatIntkTmpPrlmFMI 4768;
BA_ "SPN" SG_ 2566725886 Aft1DslOxidtnCatOtltTmpPrlmFMI 4769;
BA_ "SPN" SG_ 2566725886 Aft1DslOxidtnCatDiffPressPrlmFMI 4770;
BA_ "SPN" SG_ 2566726142 Aft2GasOxidtnCtlystIntkTemp 4759;
BA_ "SPN" SG_ 2566726142 Aft2GasOxidtnCtlystOtltTemp 4760;
BA_ "SPN" SG_ 2566726142 Aft2GasOxidtnCtlystDiffPress 4761;
BA_ "SPN" SG_ 2566726142 Aft2GsOxidtnCtlystIntkTmpPrlmFMI 4762;
BA_ "SPN" SG_ 2566726142 Aft2GsOxidtnCtlystOtltTmpPrlmFMI 4763;
BA_ "SPN" SG_ 2566726142 Aft2GsOxidtnCatDiffPressPrlmFMI 4764;
BA_ "SPN" SG_ 2566726398 Aft1GasOxidtnCtlystIntkTemp 4753;
BA_ "SPN" SG_ 2566726398 Aft1GasOxidtnCtlystOtltTemp 4754;
BA_ "SPN" SG_ 2566726398 Aft1GasOxidtnCtlystDiffPress 4755;
BA_ "SPN" SG_ 2566726398 Aft1GsOxidtnCtlystIntkTmpPrlmFMI 4756;
BA_ "SPN" SG_ 2566726398 Aft1GsOxidtnCtlystOtltTmpPrlmFMI 4757;
BA_ "SPN" SG_ 2566726398 Aft1GsOxidtnCatDiffPressPrlmFMI 4758;
BA_ "SPN" SG_ 2365400062 Jystck10GrpXAxsNtrlPosStatus 4735;
BA_ "SPN" SG_ 2365400062 Jystck10GrpXAxsLvrLftNegPosStat 4736;
BA_ "SPN" SG_ 2365400062 Jystck10GrpXAxsLvrRghtPstvPsStat 4737;
BA_ "SPN" SG_ 2365400062 Joystick10GripXAxisPosition 4738;
BA_ "SPN" SG_ 2365400062 Jystck10GrpYAxsNtrlPosStatus 4739;
BA_ "SPN" SG_ 2365400062 Jystck10GrpYAxsLvrBackNegPosStat 4740;
BA_ "SPN" SG_ 2365400062 Jystck10GrpYAxsLvrFrwdPstvPsStat 4741;
BA_ "SPN" SG_ 2365400062 Joystick10GripYAxisPosition 4742;
BA_ "SPN" SG_ 2365400062 Jystck10ThetaAxsNtrlPosStatus 4743;
BA_ "SPN" SG_ 2365400062 Jystck10ThtAxsCntrClckwsNgPsStat 4744;
BA_ "SPN" SG_ 2365400062 Jystck10ThtAxsClckwsPstvPosStat 4745;
BA_ "SPN" SG_ 2365400062 Joystick10ThetaAxisPosition 4746;
BA_ "SPN" SG_ 2365400062 Jystck10ThetaAxsDetentPosStatus 4747;
BA_ "SPN" SG_ 2365400062 Jystck10GrpYAxsDetentPosStatus 4748;
BA_ "SPN" SG_ 2365400062 Jystck10GrpXAxsDetentPosStatus 4749;
BA_ "SPN" SG_ 2365400062 Joystick10Button16PressedStatus 6770;
BA_ "SPN" SG_ 2365400062 Joystick10Button15PressedStatus 6769;
BA_ "SPN" SG_ 2365400062 Joystick10Button14PressedStatus 6768;
BA_ "SPN" SG_ 2365400062 Joystick10Button13PressedStatus 6767;
BA_ "SPN" SG_ 2365400318 Jystck10XAxsNtrlPositionStatus 4713;
BA_ "SPN" SG_ 2365400318 Jystck10XAxsLvrLftNegPosStatus 4714;
BA_ "SPN" SG_ 2365400318 Jystck10XAxsLvrRghtPstvPosStatus 4715;
BA_ "SPN" SG_ 2365400318 Joystick10XAxisPosition 4716;
BA_ "SPN" SG_ 2365400318 Jystck10YAxsNtrlPositionStatus 4717;
BA_ "SPN" SG_ 2365400318 Jystck10YAxsLvrBackNegPosStatus 4718;
BA_ "SPN" SG_ 2365400318 Jystck10YAxsLvrFrwdPstvPosStatus 4719;
BA_ "SPN" SG_ 2365400318 Joystick10YAxisPosition 4720;
BA_ "SPN" SG_ 2365400318 Jystck10YAxsDetentPositionStatus 4721;
BA_ "SPN" SG_ 2365400318 Jystck10XAxsDetentPositionStatus 4722;
BA_ "SPN" SG_ 2365400318 Joystick10Button4PressedStatus 4723;
BA_ "SPN" SG_ 2365400318 Joystick10Button3PressedStatus 4724;
BA_ "SPN" SG_ 2365400318 Joystick10Button2PressedStatus 4725;
BA_ "SPN" SG_ 2365400318 Joystick10Button1PressedStatus 4726;
BA_ "SPN" SG_ 2365400318 Joystick10Button8PressedStatus 4727;
BA_ "SPN" SG_ 2365400318 Joystick10Button7PressedStatus 4728;
BA_ "SPN" SG_ 2365400318 Joystick10Button6PressedStatus 4729;
BA_ "SPN" SG_ 2365400318 Joystick10Button5PressedStatus 4730;
BA_ "SPN" SG_ 2365400318 Joystick10Button12PressedStatus 4731;
BA_ "SPN" SG_ 2365400318 Joystick10Button11PressedStatus 4732;
BA_ "SPN" SG_ 2365400318 Joystick10Button10PressedStatus 4733;
BA_ "SPN" SG_ 2365400318 Joystick10Button9PressedStatus 4734;
BA_ "SPN" SG_ 2365400574 Jystck9GrpXAxsNtrlPositionStatus 4698;
BA_ "SPN" SG_ 2365400574 Jystck9GrpXAxsLvrLftNegPosStatus 4699;
BA_ "SPN" SG_ 2365400574 Jystck9GrpXAxsLvrRghtPstvPosStat 4700;
BA_ "SPN" SG_ 2365400574 Joystick9GripXAxisPosition 4701;
BA_ "SPN" SG_ 2365400574 Jystck9GrpYAxsNtrlPositionStatus 4702;
BA_ "SPN" SG_ 2365400574 Jystck9GrpYAxsLvrBackNegPosStat 4703;
BA_ "SPN" SG_ 2365400574 Jystck9GrpYAxsLvrFrwdPstvPosStat 4704;
BA_ "SPN" SG_ 2365400574 Joystick9GripYAxisPosition 4705;
BA_ "SPN" SG_ 2365400574 Jystck9ThetaAxsNtrlPosStatus 4706;
BA_ "SPN" SG_ 2365400574 Jystck9ThtAxsCntrClckwsNegPsStat 4707;
BA_ "SPN" SG_ 2365400574 Jystck9ThetaAxsClckwsPstvPosStat 4708;
BA_ "SPN" SG_ 2365400574 Joystick9ThetaAxisPosition 4709;
BA_ "SPN" SG_ 2365400574 Jystck9ThetaAxsDetentPosStatus 4710;
BA_ "SPN" SG_ 2365400574 Jystck9GrpYAxsDetentPosStatus 4711;
BA_ "SPN" SG_ 2365400574 Jystck9GrpXAxsDetentPosStatus 4712;
BA_ "SPN" SG_ 2365400574 Joystick9Button16PressedStatus 6766;
BA_ "SPN" SG_ 2365400574 Joystick9Button15PressedStatus 6765;
BA_ "SPN" SG_ 2365400574 Joystick9Button14PressedStatus 6764;
BA_ "SPN" SG_ 2365400574 Joystick9Button13PressedStatus 6763;
BA_ "SPN" SG_ 2365400830 Jystck9XAxsNeutralPositionStatus 4676;
BA_ "SPN" SG_ 2365400830 Jystck9XAxsLvrLftNegPosStatus 4677;
BA_ "SPN" SG_ 2365400830 Jystck9XAxsLvrRightPstvPosStatus 4678;
BA_ "SPN" SG_ 2365400830 Joystick9XAxisPosition 4679;
BA_ "SPN" SG_ 2365400830 Jystck9YAxsNeutralPositionStatus 4680;
BA_ "SPN" SG_ 2365400830 Jystck9YAxsLvrBackNegPosStatus 4681;
BA_ "SPN" SG_ 2365400830 Jystck9YAxsLvrFrwdPstvPosStatus 4682;
BA_ "SPN" SG_ 2365400830 Joystick9YAxisPosition 4683;
BA_ "SPN" SG_ 2365400830 Jystck9YAxsDetentPositionStatus 4684;
BA_ "SPN" SG_ 2365400830 Jystck9XAxsDetentPositionStatus 4685;
BA_ "SPN" SG_ 2365400830 Joystick9Button4PressedStatus 4686;
BA_ "SPN" SG_ 2365400830 Joystick9Button3PressedStatus 4687;
BA_ "SPN" SG_ 2365400830 Joystick9Button2PressedStatus 4688;
BA_ "SPN" SG_ 2365400830 Joystick9Button1PressedStatus 4689;
BA_ "SPN" SG_ 2365400830 Joystick9Button8PressedStatus 4690;
BA_ "SPN" SG_ 2365400830 Joystick9Button7PressedStatus 4691;
BA_ "SPN" SG_ 2365400830 Joystick9Button6PressedStatus 4692;
BA_ "SPN" SG_ 2365400830 Joystick9Button5PressedStatus 4693;
BA_ "SPN" SG_ 2365400830 Joystick9Button12PressedStatus 4694;
BA_ "SPN" SG_ 2365400830 Joystick9Button11PressedStatus 4695;
BA_ "SPN" SG_ 2365400830 Joystick9Button10PressedStatus 4696;
BA_ "SPN" SG_ 2365400830 Joystick9Button9PressedStatus 4697;
BA_ "SPN" SG_ 2365401086 Jystck8GrpXAxsNtrlPositionStatus 4661;
BA_ "SPN" SG_ 2365401086 Jystck8GrpXAxsLvrLftNegPosStatus 4662;
BA_ "SPN" SG_ 2365401086 Jystck8GrpXAxsLvrRghtPstvPosStat 4663;
BA_ "SPN" SG_ 2365401086 Joystick8GripXAxisPosition 4664;
BA_ "SPN" SG_ 2365401086 Jystck8GrpYAxsNtrlPositionStatus 4665;
BA_ "SPN" SG_ 2365401086 Jystck8GrpYAxsLvrBackNegPosStat 4666;
BA_ "SPN" SG_ 2365401086 Jystck8GrpYAxsLvrFrwdPstvPosStat 4667;
BA_ "SPN" SG_ 2365401086 Joystick8GripYAxisPosition 4668;
BA_ "SPN" SG_ 2365401086 Jystck8ThetaAxsNtrlPosStatus 4669;
BA_ "SPN" SG_ 2365401086 Jystck8ThtAxsCntrClckwsNegPsStat 4670;
BA_ "SPN" SG_ 2365401086 Jystck8ThetaAxsClckwsPstvPosStat 4671;
BA_ "SPN" SG_ 2365401086 Joystick8ThetaAxisPosition 4672;
BA_ "SPN" SG_ 2365401086 Jystck8ThetaAxsDetentPosStatus 4673;
BA_ "SPN" SG_ 2365401086 Jystck8GrpYAxsDetentPosStatus 4674;
BA_ "SPN" SG_ 2365401086 Jystck8GrpXAxsDetentPosStatus 4675;
BA_ "SPN" SG_ 2365401086 Joystick8Button16PressedStatus 6762;
BA_ "SPN" SG_ 2365401086 Joystick8Button15PressedStatus 6761;
BA_ "SPN" SG_ 2365401086 Joystick8Button14PressedStatus 6760;
BA_ "SPN" SG_ 2365401086 Joystick8Button13PressedStatus 6759;
BA_ "SPN" SG_ 2365401342 Jystck8XAxsNeutralPositionStatus 4639;
BA_ "SPN" SG_ 2365401342 Jystck8XAxsLvrLftNegPosStatus 4640;
BA_ "SPN" SG_ 2365401342 Jystck8XAxsLvrRightPstvPosStatus 4641;
BA_ "SPN" SG_ 2365401342 Joystick8XAxisPosition 4642;
BA_ "SPN" SG_ 2365401342 Jystck8YAxsNeutralPositionStatus 4643;
BA_ "SPN" SG_ 2365401342 Jystck8YAxsLvrBackNegPosStatus 4644;
BA_ "SPN" SG_ 2365401342 Jystck8YAxsLvrFrwdPstvPosStatus 4645;
BA_ "SPN" SG_ 2365401342 Joystick8YAxisPosition 4646;
BA_ "SPN" SG_ 2365401342 Jystck8YAxsDetentPositionStatus 4647;
BA_ "SPN" SG_ 2365401342 Jystck8XAxsDetentPositionStatus 4648;
BA_ "SPN" SG_ 2365401342 Joystick8Button4PressedStatus 4649;
BA_ "SPN" SG_ 2365401342 Joystick8Button3PressedStatus 4650;
BA_ "SPN" SG_ 2365401342 Joystick8Button2PressedStatus 4651;
BA_ "SPN" SG_ 2365401342 Joystick8Button1PressedStatus 4652;
BA_ "SPN" SG_ 2365401342 Joystick8Button8PressedStatus 4653;
BA_ "SPN" SG_ 2365401342 Joystick8Button7PressedStatus 4654;
BA_ "SPN" SG_ 2365401342 Joystick8Button6PressedStatus 4655;
BA_ "SPN" SG_ 2365401342 Joystick8Button5PressedStatus 4656;
BA_ "SPN" SG_ 2365401342 Joystick8Button12PressedStatus 4657;
BA_ "SPN" SG_ 2365401342 Joystick8Button11PressedStatus 4658;
BA_ "SPN" SG_ 2365401342 Joystick8Button10PressedStatus 4659;
BA_ "SPN" SG_ 2365401342 Joystick8Button9PressedStatus 4660;
BA_ "SPN" SG_ 2365401598 Jystck7GrpXAxsNtrlPositionStatus 4624;
BA_ "SPN" SG_ 2365401598 Jystck7GrpXAxsLvrLftNegPosStatus 4625;
BA_ "SPN" SG_ 2365401598 Jystck7GrpXAxsLvrRghtPstvPosStat 4626;
BA_ "SPN" SG_ 2365401598 Joystick7GripXAxisPosition 4627;
BA_ "SPN" SG_ 2365401598 Jystck7GrpYAxsNtrlPositionStatus 4628;
BA_ "SPN" SG_ 2365401598 Jystck7GrpYAxsLvrBackNegPosStat 4629;
BA_ "SPN" SG_ 2365401598 Jystck7GrpYAxsLvrFrwdPstvPosStat 4630;
BA_ "SPN" SG_ 2365401598 Joystick7GripYAxisPosition 4631;
BA_ "SPN" SG_ 2365401598 Jystck7ThetaAxsNtrlPosStatus 4632;
BA_ "SPN" SG_ 2365401598 Jystck7ThtAxsCntrClckwsNegPsStat 4633;
BA_ "SPN" SG_ 2365401598 Jystck7ThetaAxsClckwsPstvPosStat 4634;
BA_ "SPN" SG_ 2365401598 Joystick7ThetaAxisPosition 4635;
BA_ "SPN" SG_ 2365401598 Jystck7ThetaAxsDetentPosStatus 4636;
BA_ "SPN" SG_ 2365401598 Jystck7GrpYAxsDetentPosStatus 4637;
BA_ "SPN" SG_ 2365401598 Jystck7GrpXAxsDetentPosStatus 4638;
BA_ "SPN" SG_ 2365401598 Joystick7Button16PressedStatus 6758;
BA_ "SPN" SG_ 2365401598 Joystick7Button15PressedStatus 6757;
BA_ "SPN" SG_ 2365401598 Joystick7Button14PressedStatus 6756;
BA_ "SPN" SG_ 2365401598 Joystick7Button13PressedStatus 6755;
BA_ "SPN" SG_ 2365401854 Jystck7XAxsNeutralPositionStatus 4602;
BA_ "SPN" SG_ 2365401854 Jystck7XAxsLvrLftNegPosStatus 4603;
BA_ "SPN" SG_ 2365401854 Jystck7XAxsLvrRightPstvPosStatus 4604;
BA_ "SPN" SG_ 2365401854 Joystick7XAxisPosition 4605;
BA_ "SPN" SG_ 2365401854 Jystck7YAxsNeutralPositionStatus 4606;
BA_ "SPN" SG_ 2365401854 Jystck7YAxsLvrBackNegPosStatus 4607;
BA_ "SPN" SG_ 2365401854 Jystck7YAxsLvrFrwdPstvPosStatus 4608;
BA_ "SPN" SG_ 2365401854 Joystick7YAxisPosition 4609;
BA_ "SPN" SG_ 2365401854 Jystck7YAxsDetentPositionStatus 4610;
BA_ "SPN" SG_ 2365401854 Jystck7XAxsDetentPositionStatus 4611;
BA_ "SPN" SG_ 2365401854 Joystick7Button4PressedStatus 4612;
BA_ "SPN" SG_ 2365401854 Joystick7Button3PressedStatus 4613;
BA_ "SPN" SG_ 2365401854 Joystick7Button2PressedStatus 4614;
BA_ "SPN" SG_ 2365401854 Joystick7Button1PressedStatus 4615;
BA_ "SPN" SG_ 2365401854 Joystick7Button8PressedStatus 4616;
BA_ "SPN" SG_ 2365401854 Joystick7Button7PressedStatus 4617;
BA_ "SPN" SG_ 2365401854 Joystick7Button6PressedStatus 4618;
BA_ "SPN" SG_ 2365401854 Joystick7Button5PressedStatus 4619;
BA_ "SPN" SG_ 2365401854 Joystick7Button12PressedStatus 4620;
BA_ "SPN" SG_ 2365401854 Joystick7Button11PressedStatus 4621;
BA_ "SPN" SG_ 2365401854 Joystick7Button10PressedStatus 4622;
BA_ "SPN" SG_ 2365401854 Joystick7Button9PressedStatus 4623;
BA_ "SigType" SG_ 2566703102 ModelYear 3;
BA_ "SigType" SG_ 2566703102 CertificationEngineFamilyName 3;
VAL_ 2566698238 SwitchedOutput4 0 "Output off" 1 "Output on" 2 "Reserved" 3 "Take no action" ;
VAL_ 2566698238 SwitchedOutput3 0 "Output off" 1 "Output on" 2 "Reserved" 3 "Take no action" ;
VAL_ 2566698238 SwitchedOutput2 0 "Output off" 1 "Output on" 2 "Reserved" 3 "Take no action" ;
VAL_ 2566698238 SwitchedOutput1 0 "Output off" 1 "Output on" 2 "Reserved" 3 "Take no action" ;
VAL_ 2566698238 SwitchedOutput8 0 "Output off" 1 "Output on" 2 "Reserved" 3 "Take no action" ;
VAL_ 2566698238 SwitchedOutput7 0 "Output off" 1 "Output on" 2 "Reserved" 3 "Take no action" ;
VAL_ 2566698238 SwitchedOutput6 0 "Output off" 1 "Output on" 2 "Reserved" 3 "Take no action" ;
VAL_ 2566698238 SwitchedOutput5 0 "Output off" 1 "Output on" 2 "Reserved" 3 "Take no action" ;
VAL_ 2566698238 SwitchedOutput12 0 "Output off" 1 "Output on" 2 "Reserved" 3 "Take no action" ;
VAL_ 2566698238 SwitchedOutput11 0 "Output off" 1 "Output on" 2 "Reserved" 3 "Take no action" ;
VAL_ 2566698238 SwitchedOutput10 0 "Output off" 1 "Output on" 2 "Reserved" 3 "Take no action" ;
VAL_ 2566698238 SwitchedOutput9 0 "Output off" 1 "Output on" 2 "Reserved" 3 "Take no action" ;
VAL_ 2566698238 SwitchedOutput16 0 "Output off" 1 "Output on" 2 "Reserved" 3 "Take no action" ;
VAL_ 2566698238 SwitchedOutput15 0 "Output off" 1 "Output on" 2 "Reserved" 3 "Take no action" ;
VAL_ 2566698238 SwitchedOutput14 0 "Output off" 1 "Output on" 2 "Reserved" 3 "Take no action" ;
VAL_ 2566698238 SwitchedOutput13 0 "Output off" 1 "Output on" 2 "Reserved" 3 "Take no action" ;
VAL_ 2566698238 SwitchedOutput20 0 "Output off" 1 "Output on" 2 "Reserved" 3 "Take no action" ;
VAL_ 2566698238 SwitchedOutput19 0 "Output off" 1 "Output on" 2 "Reserved" 3 "Take no action" ;
VAL_ 2566698238 SwitchedOutput18 0 "Output off" 1 "Output on" 2 "Reserved" 3 "Take no action" ;
VAL_ 2566698238 SwitchedOutput17 0 "Output off" 1 "Output on" 2 "Reserved" 3 "Take no action" ;
VAL_ 2566698238 SwitchedOutput24 0 "Output off" 1 "Output on" 2 "Reserved" 3 "Take no action" ;
VAL_ 2566698238 SwitchedOutput23 0 "Output off" 1 "Output on" 2 "Reserved" 3 "Take no action" ;
VAL_ 2566698238 SwitchedOutput22 0 "Output off" 1 "Output on" 2 "Reserved" 3 "Take no action" ;
VAL_ 2566698238 SwitchedOutput21 0 "Output off" 1 "Output on" 2 "Reserved" 3 "Take no action" ;
VAL_ 2566698238 SwitchedOutput28 0 "Output off" 1 "Output on" 2 "Reserved" 3 "Take no action" ;
VAL_ 2566698238 SwitchedOutput27 0 "Output off" 1 "Output on" 2 "Reserved" 3 "Take no action" ;
VAL_ 2566698238 SwitchedOutput26 0 "Output off" 1 "Output on" 2 "Reserved" 3 "Take no action" ;
VAL_ 2566698238 SwitchedOutput25 0 "Output off" 1 "Output on" 2 "Reserved" 3 "Take no action" ;
VAL_ 2566698238 SwitchedOutput32 0 "Output off" 1 "Output on" 2 "Reserved" 3 "Take no action" ;
VAL_ 2566698238 SwitchedOutput31 0 "Output off" 1 "Output on" 2 "Reserved" 3 "Take no action" ;
VAL_ 2566698238 SwitchedOutput30 0 "Output off" 1 "Output on" 2 "Reserved" 3 "Take no action" ;
VAL_ 2566698238 SwitchedOutput29 0 "Output off" 1 "Output on" 2 "Reserved" 3 "Take no action" ;
VAL_ 2566698494 FusedOutput4 0 "Output not powered" 1 "Output powered" 2 "Reserved" 3 "Take no action" ;
VAL_ 2566698494 FusedOutput3 0 "Output not powered" 1 "Output powered" 2 "Reserved" 3 "Take no action" ;
VAL_ 2566698494 FusedOutput2 0 "Output not powered" 1 "Output powered" 2 "Reserved" 3 "Take no action" ;
VAL_ 2566698494 FusedOutput1 0 "Output not powered" 1 "Output powered" 2 "Reserved" 3 "Take no action" ;
VAL_ 2566698494 FusedOutput8 0 "Output not powered" 1 "Output powered" 2 "Reserved" 3 "Take no action" ;
VAL_ 2566698494 FusedOutput7 0 "Output not powered" 1 "Output powered" 2 "Reserved" 3 "Take no action" ;
VAL_ 2566698494 FusedOutput6 0 "Output not powered" 1 "Output powered" 2 "Reserved" 3 "Take no action" ;
VAL_ 2566698494 FusedOutput5 0 "Output not powered" 1 "Output powered" 2 "Reserved" 3 "Take no action" ;
VAL_ 2566698494 FusedOutput12 0 "Output not powered" 1 "Output powered" 2 "Reserved" 3 "Take no action" ;
VAL_ 2566698494 FusedOutput11 0 "Output not powered" 1 "Output powered" 2 "Reserved" 3 "Take no action" ;
VAL_ 2566698494 FusedOutput10 0 "Output not powered" 1 "Output powered" 2 "Reserved" 3 "Take no action" ;
VAL_ 2566698494 FusedOutput9 0 "Output not powered" 1 "Output powered" 2 "Reserved" 3 "Take no action" ;
VAL_ 2566698494 FusedOutput16 0 "Output not powered" 1 "Output powered" 2 "Reserved" 3 "Take no action" ;
VAL_ 2566698494 FusedOutput15 0 "Output not powered" 1 "Output powered" 2 "Reserved" 3 "Take no action" ;
VAL_ 2566698494 FusedOutput14 0 "Output not powered" 1 "Output powered" 2 "Reserved" 3 "Take no action" ;
VAL_ 2566698494 FusedOutput13 0 "Output not powered" 1 "Output powered" 2 "Reserved" 3 "Take no action" ;
VAL_ 2566698494 FusedOutput20 0 "Output not powered" 1 "Output powered" 2 "Reserved" 3 "Take no action" ;
VAL_ 2566698494 FusedOutput19 0 "Output not powered" 1 "Output powered" 2 "Reserved" 3 "Take no action" ;
VAL_ 2566698494 FusedOutput18 0 "Output not powered" 1 "Output powered" 2 "Reserved" 3 "Take no action" ;
VAL_ 2566698494 FusedOutput17 0 "Output not powered" 1 "Output powered" 2 "Reserved" 3 "Take no action" ;
VAL_ 2566698494 FusedOutput24 0 "Output not powered" 1 "Output powered" 2 "Reserved" 3 "Take no action" ;
VAL_ 2566698494 FusedOutput23 0 "Output not powered" 1 "Output powered" 2 "Reserved" 3 "Take no action" ;
VAL_ 2566698494 FusedOutput22 0 "Output not powered" 1 "Output powered" 2 "Reserved" 3 "Take no action" ;
VAL_ 2566698494 FusedOutput21 0 "Output not powered" 1 "Output powered" 2 "Reserved" 3 "Take no action" ;
VAL_ 2566698494 FusedOutput28 0 "Output not powered" 1 "Output powered" 2 "Reserved" 3 "Take no action" ;
VAL_ 2566698494 FusedOutput27 0 "Output not powered" 1 "Output powered" 2 "Reserved" 3 "Take no action" ;
VAL_ 2566698494 FusedOutput26 0 "Output not powered" 1 "Output powered" 2 "Reserved" 3 "Take no action" ;
VAL_ 2566698494 FusedOutput25 0 "Output not powered" 1 "Output powered" 2 "Reserved" 3 "Take no action" ;
VAL_ 2566698494 FusedOutput32 0 "Output not powered" 1 "Output powered" 2 "Reserved" 3 "Take no action" ;
VAL_ 2566698494 FusedOutput31 0 "Output not powered" 1 "Output powered" 2 "Reserved" 3 "Take no action" ;
VAL_ 2566698494 FusedOutput30 0 "Output not powered" 1 "Output powered" 2 "Reserved" 3 "Take no action" ;
VAL_ 2566698494 FusedOutput29 0 "Output not powered" 1 "Output powered" 2 "Reserved" 3 "Take no action" ;
VAL_ 2566699774 Aft2DslExhstFldCtrlMdulRelayCtrl 0 "Off" 1 "On" 2 "Error" 3 "Unavailable" ;
VAL_ 2566699774 Aft2DslExhstFldCtrlMdulPwrSupply 0 "Off" 1 "On" 2 "Error" 3 "Unavailable" ;
VAL_ 2566699774 Aft2DslExhstFldCtrlMdulPwrSuply2 0 "Off" 1 "On" 2 "Error" 3 "Unavailable" ;
VAL_ 2566699774 Aft2DslExhstFldCtrlMdulCircBrkr 0 "Off" 1 "On" 2 "Error" 3 "Not available" ;
VAL_ 2566699774 Aft2DslExhstFldCtrlMdul2RelyCtrl 0 "Off" 1 "On" 2 "Error" 3 "Unavailable" ;
VAL_ 2566699774 Aft2DslExhstFldCtrlMdul2PwrSupp1 0 "Off" 1 "On" 2 "Error" 3 "Unavailable" ;
VAL_ 2566699774 Aft2DslExhstFldCtrlMdul2PwrSupp2 0 "Off" 1 "On" 2 "Error" 3 "Unavailable" ;
VAL_ 2566700030 Aft1DslExhstFldCtrlMdulRelayCtrl 0 "Off" 1 "On" 2 "Error" 3 "Unavailable" ;
VAL_ 2566700030 Aft1DslExhstFldCtrlMdulPwrSupply 0 "Off" 1 "On" 2 "Error" 3 "Unavailable" ;
VAL_ 2566700030 Aft1DslExhstFldCtrlMdulPwrSuply2 0 "Off" 1 "On" 2 "Error" 3 "Unavailable" ;
VAL_ 2566700030 Aft1DslExhstFldCtrlMdulCircBrkr 0 "Off" 1 "On" 2 "Error" 3 "Not available" ;
VAL_ 2566700030 Aft1DslExhstFldCtrlMdul2RelyCtrl 0 "Off" 1 "On" 2 "Error" 3 "Unavailable" ;
VAL_ 2566700030 Aft1DslExhstFldCtrlMdul2PwrSupp1 0 "Off" 1 "On" 2 "Error" 3 "Unavailable" ;
VAL_ 2566700030 Aft1DslExhstFldCtrlMdul2PwrSupp2 0 "Off" 1 "On" 2 "Error" 3 "Unavailable" ;
VAL_ 2499592190 TrnsmCltch1CoolingActrStat 0 "Off" 1 "On" 2 "Error" 3 "Not available" ;
VAL_ 2499592190 TrnsmCltch2CoolingActrStat 0 "Off" 1 "On" 2 "Error" 3 "Not available" ;
VAL_ 2499592190 TransmissionShiftRail1ActrStatus 0 "Off" 1 "On" 2 "Error" 3 "Not available" ;
VAL_ 2499592190 TransmissionShiftRail2ActrStatus 0 "Off" 1 "On" 2 "Error" 3 "Not available" ;
VAL_ 2499592190 TransmissionShiftRail3ActrStatus 0 "Off" 1 "On" 2 "Error" 3 "Not available" ;
VAL_ 2499592190 TransmissionShiftRail4ActrStatus 0 "Off" 1 "On" 2 "Error" 3 "Not available" ;
VAL_ 2499592190 TransmissionShiftRail5ActrStatus 0 "Off" 1 "On" 2 "Error" 3 "Not available" ;
VAL_ 2499592190 TransmissionShiftRail6ActrStatus 0 "Off" 1 "On" 2 "Error" 3 "Not available" ;
VAL_ 2566701822 HybridSystemWarningIndicator 0 "Hybrid System Warning Indicator is off" 1 "Hybrid System Warning Indicator is on continuously" 2 "Hybrid System Warning Indicator is flashing" 3 "Not available" ;
VAL_ 2566701822 HybridSystemOverheatIndicator 0 "Hybrid System Temperature Indicator is off" 1 "Hybrid System Temperature Indicator is on continuously" 2 "Hybrid System Temperature Indicator is flashing" 3 "Not available" ;
VAL_ 2566701822 HybridSystemStopIndicator 0 "Hybrid System Stop Indicator is off" 1 "Hybrid System Stop Indicator is on continuously" 2 "Hybrid System Stop Indicator is flashing" 3 "Not available" ;
VAL_ 2566701822 HybridSystemOBDRelatedDTCStatus 0 "Hybrid System does not have an active OBD related DTC" 1 "Hybrid System has an active OBD related DTC" 2 "SAE Reserved" 3 "Not available" ;
VAL_ 2566701822 PropulsionSystemActive 0 "Propulsion System is not ready to move vehicle if commanded by operator" 1 "Propulsion System is ready to move, or is moving the vehicle as commanded by operator" 2 "SAE Reserved" 3 "Not Available" ;
VAL_ 2566701822 HybridSystemEngineAssistStatus 0 "Hybrid system is not mechanically assisting engine rotation" 1 "Hybrid system may or may not mechanically assist engine rotation" 2 "Error" 3 "Not Available" ;
VAL_ 2566701822 HybridSystemServiceIndicator 0 "Hybrid Service Indicator is off" 1 "Hybrid Service Indicator is on continously" 2 "Hybrid Service Indicator is flashing" 3 "Not Available" ;
VAL_ 2566701822 HybridSystemMtrOverspeedIndictr 0 "Hybrid System Motor Overspeed Indicator is off" 1 "Hybrid System Motor Overspeed Indicator is on continously" 2 "Hybrid System Motor Overspeed Indicator is flashing" 3 "Not Available" ;
VAL_ 2566701822 HybridSysMtrOverspdAudibleAlarm 0 "Motor Overspeed Audible Alarm is off" 1 "Motor Overspeed Audible Alarm is on" 2 "Error" 3 "Not Available" ;
VAL_ 2566701822 HybridSysElectricAltrntrIndictr 0 "Alternator Indicator is off" 1 "Alternator Indicator is on" 2 "Alternator Indicator is flashing" 3 "Not Available" ;
VAL_ 2566701822 HybridSystemRegativeBrkngIndictr 0 "Regenerative braking is inactive" 1 "Regenerative braking is active" 2 "Regenerative braking is disabled or faulted " 3 "Not Available" ;
VAL_ 2566701822 HybridSystemInitIndictr 0 "Hybrid System Initialization Indicator is not active" 1 "Hybrid System Initialization Indicator is active" 2 "Error" 3 "Not Available" ;
VAL_ 2566701822 HybridSysHghVltgExposureIndictr 0 "System is operational and intact" 1 "System is operational and has detected a compromise" 2 "Error" 3 "Not Available" ;
VAL_ 2566701822 StoredEnergySourceOnlyModeAllwd 0 "Mode NOT allowed" 1 "Mode allowed" 2 "Error" 3 "Not available" ;
VAL_ 2566701822 StoredEnergySrcIncreasngMdeAllwd 0 "Mode NOT allowed" 1 "Mode allowed" 2 "Error" 3 "Not available" ;
VAL_ 2566701822 StoredEnergySourceLevel 0 "State of charge is below the minimum HVES useable capacity" 100 "State of charge is above the maximum HVES useable capacity" ;
VAL_ 2566701822 HybridPropulsionModeStatus 0 "No mode requested" 1 "Stored Energy Source Sustaining" 2 "Stored Energy Source Increasing" 3 "Stored Energy Source Depleting" 4 "Stored Energy Source Offline" 5 "Stored Energy Source Only" 14 "Error" 15 "Not Available" ;
VAL_ 2566701822 HybridProplsnMdeTransitionStatus 0 "No transition requested" 1 "Transition requested and in process" 2 "Requested mode denied - Requested mode not available" 3 "Requested mode denied - Vehicle Speed unacceptable for requested mode" 4 "Requested mode denied - HVES State of Charge unacceptable for requested mode" 5 "Requested mode denied - Temporary limit exceeded" 6 "Requested mode denied - HVES temporary limit threshold exceeded for one or more HVES" 13 "Requested mode denied- reason not specified" 14 "Error" 15 "Not available" ;
VAL_ 2566701822 ExtEnergySourceConnectnStatus 0 "No Connection" 1 "Connection 1 - Error (Verification failed)" 2 "Connection 1 - Verification in Process" 3 "Connection 1 - Energy Source and Drain" 4 "Connection 1 - Energy Source" 5 "Connection 1 - Energy Drain" 6 "Connection 2 - Error (Verification failed)" 7 "Connection 2 - Verification in Process" 8 "Connection 2 - Energy Source and Drain" 9 "Connection 2 - Energy Source" 10 "Connection 2 - Energy Drain" 14 "Error" 15 "Not Available" ;
VAL_ 2566701822 HybridSystemProplsnDisablStatus 0 "Propulsion not disabled" 1 "Propulsion is disabled" 2 "Error" 3 "Not Available" ;
VAL_ 2566702846 EngineOBDWarmUpSequence 0 "Warm-up cycle not occurred" 1 "Warm-up cycle occurred" 2 "SAE reserved" 3 "Not supported or not available" ;
VAL_ 2566703358 FeedbackEngineFuelingState 0 "Fueling inhibited" 1 "Engine kept running" 2 "No active request" 3 "Not Supported" ;
VAL_ 2566703358 EngineFuelingInhibitAllowed 0 "Engine not stop fueling" 1 "Engine stop fueling" 2 "SAE Reserved" 3 "Not Supported" ;
VAL_ 2566703358 EngFuelingInhibitPreventedReason 0 "Fueling inhibit allowed" 1 "Aftertreatment regeneration is active or preparing to be active" 2 "Oil Distribution in engine is incomplete" 3 "Engine is cold" 4 "Service Override" 5 "Aftertreatment system is cold" 6 "Aftertreatment Protection" 7 "Engine load too high" 8 "Engine protection" 9 "Insufficient SLI battery charge" 10 "Maximum number of engine fueling inhibit requests" 11 "Engine driven fan request" 12 "Low idle governor operation required" 13 "Vehicle speed is greater than zero" 14 "See Engine Fueling Inhibit Prevented Reason Extension" 15 "Not Supported" ;
VAL_ 2566703358 EngineDualFuelMode 0 "Actual dual fuel mode off" 1 "Actual dual fuel mode on" 2 "Reserved" 3 "Not available" ;
VAL_ 2566703358 EngFuelngInhbtPrevntdRsnExtsion 0 "Fueling inhibit allowed" 1 "Aftertreatment regeneration is active or preparing to be active" 2 "Oil Distribution in engine is incomplete" 3 "Engine is cold" 4 "Service Override" 5 "Aftertreatment system is cold" 6 "Aftertreatment Protection" 7 "Engine load too high" 8 "Engine protection" 9 "Insufficient SLI battery charge" 10 "Maximum number of engine fueling inhibit requests temporary limit exceeded" 11 "Engine driven fan request" 12 "Low idle governor operation required" 13 "Vehicle speed is greater than zero" 14 "Service brake pedal is not depressed" 15 "Parking brake is not applied" 16 "Transmission is in Reverse" 17 "Clutch pedal is not depressed" 18 "PTO is active" 19 "Stability/Slip Control event is active" 20 "Stability/Slip Control system has a fault" 21 "Interlock is active" 63 "Not Supported" ;
VAL_ 2566703358 EngineFuelingInhibitRequestCount 11 "More than 10 active fueling inhibit requests" 15 "Not available" ;
VAL_ 2566703358 EngineFuelingDesiredRequestCount 11 "More than 10 active fueling desired requests" 15 "Not available" ;
VAL_ 2566703870 EngExhstGasRecirc2Actr1TempStat 0 "High Most severe" 1 "High Least severe" 2 "In Range " 3 "Low Least severe" 4 "Low Most severe" 5 "Not Defined" 6 "Error" 7 "Not available" ;
VAL_ 2566703870 EngExhstGasRecirc2Actr2TempStat 0 "High Most severe" 1 "High Least severe" 2 "In Range " 3 "Low Least severe" 4 "Low Most severe" 5 "Not Defined" 6 "Error" 7 "Not available" ;
VAL_ 2566703870 EngExhstGasRecirc2Actr1OpStatus 0 "Normal" 1 "Alarm" 2 "Alarm High Severity" 3 "Derate Active" 4 "Controlled Shutdown Active" 5 "Uncontrolled Shutdown Active" 14 "Error" 15 "Not available" ;
VAL_ 2566703870 EngExhstGasRecirc2Actr2OpStatus 0 "Normal" 1 "Alarm" 2 "Alarm High Severity" 3 "Derate Active" 4 "Controlled Shutdown Active" 5 "Uncontrolled Shutdown Active" 14 "Error" 15 "Not available" ;
VAL_ 2566704126 EngExhstGasRecirc1Actr1TempStat 0 "High Most severe" 1 "High Least severe" 2 "In Range " 3 "Low Least severe" 4 "Low Most severe" 5 "Not Defined" 6 "Error" 7 "Not available" ;
VAL_ 2566704126 EngExhstGasRecirc1Actr2TempStat 0 "High Most severe" 1 "High Least severe" 2 "In Range " 3 "Low Least severe" 4 "Low Most severe" 5 "Not Defined" 6 "Error" 7 "Not available" ;
VAL_ 2566704126 EngExhstGasRecirc1Actr1OpStatus 0 "Normal" 1 "Alarm" 2 "Alarm High Severity" 3 "Derate Active" 4 "Controlled Shutdown Active" 5 "Uncontrolled Shutdown Active" 14 "Error" 15 "Not available" ;
VAL_ 2566704126 EngExhstGasRecirc1Actr2OpStatus 0 "Normal" 1 "Alarm" 2 "Alarm High Severity" 3 "Derate Active" 4 "Controlled Shutdown Active" 5 "Uncontrolled Shutdown Active" 14 "Error" 15 "Not available" ;
VAL_ 2566704382 Aftrtrtmnt1IntkGasSnsrPwrSupply 0 "Off" 1 "On" 2 "Error" 3 "Unavailable" ;
VAL_ 2566704382 Aftrtrtmnt1OtltGasSnsrPwrSupply 0 "Off" 1 "On" 2 "Error" 3 "Unavailable" ;
VAL_ 2566704382 Aftrtrtmnt2IntkGasSnsrPwrSupply 0 "Off" 1 "On" 2 "Error" 3 "Unavailable" ;
VAL_ 2566704382 Aftrtrtmnt2OtltGasSnsrPwrSupply 0 "Off" 1 "On" 2 "Error" 3 "Unavailable" ;
VAL_ 2566704382 Aftrtrtmnt1Intk2GsSnsrPwrSupply 0 "Off" 1 "On" 2 "Error" 3 "Unavailable" ;
VAL_ 2566704382 Aftrtrtmnt1Otlt2GsSnsrPwrSupply 0 "Off" 1 "On" 2 "Error" 3 "Unavailable" ;
VAL_ 2566705150 Aft1OtltNOxSnsrSelfDiagssTrigger 0 "Diagnostic mode disabled" 1 "Request at Lambda=1.0" 2 "Request at partial load" 3 "Request at fuel cut" 4 "Request at After Run" 15 "Not supported" ;
VAL_ 2566705150 Aft1IntkNOxSnsrSelfDiagssTrigger 0 "Diagnostic mode disabled" 1 "Request at Lambda=1.0" 2 "Request at partial load" 3 "Request at fuel cut" 4 "Request at After Run" 15 "Not supported" ;
VAL_ 2566705150 Aft2OtltNOxSnsrSelfDiagssTrigger 0 "Diagnostic mode disabled" 1 "Request at Lambda=1.0" 2 "Request at partial load" 3 "Request at fuel cut" 4 "Request at After Run" 15 "Not supported" ;
VAL_ 2566705150 Aft2IntkNOxSnsrSelfDiagssTrigger 0 "Diagnostic mode disabled" 1 "Request at Lambda=1.0" 2 "Request at partial load" 3 "Request at fuel cut" 4 "Request at After Run" 15 "Not supported" ;
VAL_ 2566705662 ProtectLamp 0 "Lamp Off" 1 "Lamp On" 2 "Reserved" 3 "Not available" ;
VAL_ 2566705662 AmberWarningLamp 0 "Lamp Off" 1 "Lamp On" 2 "Reserved" 3 "Not available" ;
VAL_ 2566705662 RedStopLamp 0 "Lamp Off" 1 "Lamp On" 2 "Reserved" 3 "Not available" ;
VAL_ 2566705662 MalfunctionIndicatorLamp 0 "Lamp Off" 1 "Lamp On" 2 "Short MIL for WWH OBD" 3 "Not available" ;
VAL_ 2566705662 FlashProtectLamp 0 "Slow Flash (1 Hz, 50 % duty cycle)" 1 "Fast Flash (2 Hz or faster, 50% duty cycle)" 2 "Reserved" 3 "Unavailable / Do Not Flash" ;
VAL_ 2566705662 FlashAmberWarningLamp 0 "Slow Flash (1 Hz, 50 % duty cycle)" 1 "Fast Flash (2 Hz or faster, 50% duty cycle)" 2 "Reserved" 3 "Unavailable / Do Not Flash" ;
VAL_ 2566705662 FlashRedStopLamp 0 "Slow Flash (1 Hz, 50 % duty cycle)" 1 "Fast Flash (2 Hz or faster, 50% duty cycle)" 2 "Reserved" 3 "Unavailable / Do Not Flash" ;
VAL_ 2566705662 FlashMalfunctionIndicatorLamp 0 "Slow Flash (1 Hz, 50 % duty cycle)" 1 "Fast Flash (2 Hz or faster, 50% duty cycle)" 2 "Class C DTC  " 3 "Unavailable / Do Not Flash" ;
VAL_ 2566705662 SPNConversionMethod 0 "Convert SPN per Version 4" 1 "Convert SPN per Version 1, 2 or 3" ;
VAL_ 2566705918 ProtectLamp 0 "Lamp Off" 1 "Lamp On" 2 "Reserved" 3 "Not available" ;
VAL_ 2566705918 AmberWarningLamp 0 "Lamp Off" 1 "Lamp On" 2 "Reserved" 3 "Not available" ;
VAL_ 2566705918 RedStopLamp 0 "Lamp Off" 1 "Lamp On" 2 "Reserved" 3 "Not available" ;
VAL_ 2566705918 MalfunctionIndicatorLamp 0 "Lamp Off" 1 "Lamp On" 2 "Short MIL for WWH OBD" 3 "Not available" ;
VAL_ 2566705918 FlashProtectLamp 0 "Slow Flash (1 Hz, 50 % duty cycle)" 1 "Fast Flash (2 Hz or faster, 50% duty cycle)" 2 "Reserved" 3 "Unavailable / Do Not Flash" ;
VAL_ 2566705918 FlashRedStopLamp 0 "Slow Flash (1 Hz, 50 % duty cycle)" 1 "Fast Flash (2 Hz or faster, 50% duty cycle)" 2 "Reserved" 3 "Unavailable / Do Not Flash" ;
VAL_ 2566705918 FlashMalfunctionIndicatorLamp 0 "Slow Flash (1 Hz, 50 % duty cycle)" 1 "Fast Flash (2 Hz or faster, 50% duty cycle)" 2 "Class C DTC  " 3 "Unavailable / Do Not Flash" ;
VAL_ 2566705918 SPNConversionMethod 0 "Convert SPN per Version 4" 1 "Convert SPN per Version 1, 2 or 3" ;
VAL_ 2566706686 Aft1DslExhstFldDsngUnit1HtrRely 0 "Off" 1 "On" 2 "Error" 3 "Not available" ;
VAL_ 2566706686 Aftrtrtmnt1DslExhstFldPmpPwrSupp 0 "Off" 1 "On" 2 "Error" 3 "Unavailable" ;
VAL_ 2566708478 AdaptiveCruiseCtrlReadinessStat 0 "Off" 1 "On" 2 "Error Condition" 3 "Not Available/Not Supported" ;
VAL_ 2566708478 CruiseControlSystemCommandState 0 "No Cruise Control System Command" 1 "Disabled by Cruise Control Disable Command" 2 "Disabled by Cruise Control Pause Command" 3 "Re-activated by Cruise Control Resume Command" 4 "Received a Cruise Control Resume Command" 7 "Not Supported" ;
VAL_ 2566708478 PredictCrsCtrlSetSpdOffstStatus 0 "Cruise Control Speed (SPN 7319) does not include Predictive Cruise Control Set Speed Offset (SPN 7316)" 1 "Cruise Control Speed (SPN 7319) includes Predictive Cruise Control Set Speed Offset (SPN 7316)" 2 "SAE Reserved" 3 "Not available" ;
VAL_ 2566708478 AEBSReadinessState 0 "Off" 1 "On" 2 "Condition exists" 3 "Not Available/Not Supported" ;
VAL_ 2566708478 CrsCtrlDriverCancellationStatus 0 "Driver action has not cancelled cruise control" 1 "Cruise control cancelled by driver action" 2 "Error" 3 "Not available" ;
VAL_ 2566710014 SupplementalFanEnableStatus 0 "Disabled" 1 "Enabled" 2 "Error" 3 "Not available/Not installed" ;
VAL_ 2566710014 SupplementalFanDirectionStatus 0 "Forward" 1 "Reverse" 2 "Error" 3 "Not available/Not installed" ;
VAL_ 2566710014 SupplementalFanVelocityStatus 0 "At Velocity" 1 "Velocity Error" 2 "Fan Spin Up" 3 "Fan Spin Down" 4 "Fan Stall" 14 "Error" 15 "Not available" ;
VAL_ 2566710014 SupplementalFanCtrllerTempStat 0 "High most severe " 1 "High Least severe " 2 "In Range " 3 "Low Least severe " 4 "Low Most severe " 5 "Not Defined " 6 "Error " 7 "Not available" ;
VAL_ 2566710014 SupplementalFanDriveStatus 0 "Normal" 1 "Alarm" 2 "Alarm High Severity" 3 "Derate Active" 4 "Controlled Shutdown Active" 5 "Uncontrolled Shutdown Active" 14 "Error" 15 "Not available" ;
VAL_ 2566711038 LubricationCycleModeLockStatus 0 "Not Locked" 1 "Locked" 2 "Error" 3 "Not available" ;
VAL_ 2566711038 LubricationCycleModeStatus 0 "Cycle mode # 1" 1 "Cycle mode # 2" 2 "Cycle mode # 3" 6 "Error" 7 "Not available" ;
VAL_ 2566711038 LubricationOperationModeStatus 0 "Automatic Mode" 1 "Manual Service Mode" 2 "Test Mode # 1" 3 "Test Mode # 2" 4 "Test Mode # 3" 5 "Reserved" 6 "Error" 7 "Not Available" ;
VAL_ 2566711038 LubricationPumpEnableStatus 0 "Disabled" 1 "Enabled" 2 "Error" 3 "Not available" ;
VAL_ 2566711038 LubricationReservoirLevel 0 "Reservoir Not Low" 1 "Reservoir Low" 2 "Error " 3 "Not available or not installed" ;
VAL_ 2566711038 LubricationTimingCycleStatus 0 "Paused " 1 "Enabled" 2 "Error " 3 "Not available or not installed" ;
VAL_ 2566711550 IntkVlvActSysOilPrs1SolenoidCtrl 0 "off" 1 "on" 2 "reserved for SAE assignment" 3 "not available" ;
VAL_ 2566711550 IntkVlvActSysOilPrs2SolenoidCtrl 0 "off" 1 "on" 2 "reserved for SAE assignment" 3 "not available" ;
VAL_ 2566711806 Armrest1Switch1 0 "Off" 2 "On" 4 "Reserved" 6 "Don't care/take no action" ;
VAL_ 2566711806 Armrest1Switch2 0 "Off" 2 "On" 4 "Reserved" 6 "Don't care/take no action" ;
VAL_ 2566711806 Armrest2Switch1 0 "Off" 2 "On" 4 "Reserved" 6 "Don't care/take no action" ;
VAL_ 2566711806 Armrest2Switch2 0 "Off" 2 "On" 4 "Reserved" 6 "Don't care/take no action" ;
VAL_ 2566712318 Aftrtrtmnt2NOxAdsorberRegenStat 0 "Inactive" 1 "Active" 2 "Error indicator" 3 "Not available" ;
VAL_ 2566712318 Aft2NOxAdsorberDesulfationStat 0 "Inactive" 1 "Active" 2 "Error indicator" 3 "Not available" ;
VAL_ 2566712574 Aftrtrtmnt1NOxAdsorberRegenStat 0 "Inactive" 1 "Active" 2 "Error indicator" 3 "Not available" ;
VAL_ 2566712574 Aft1NOxAdsorberDesulfationStat 0 "Inactive" 1 "Active" 2 "Error indicator" 3 "Not available" ;
VAL_ 2566713598 FuelTankTransferPump 0 "Off" 1 "On" 2 "Error" 3 "Not available" ;
VAL_ 2566713854 EngTurboWastegateActr2TempStat 0 "High Most severe" 1 "High Least severe" 2 "In Range" 3 "Low Least severe" 4 "Low Most severe" 5 "Not Defined" 6 "Error" 7 "Not available" ;
VAL_ 2566713854 EngTurboWastegateActr1OpStat 0 "Normal" 1 "Alarm" 2 "Alarm High Severity" 3 "Derate Active" 4 "Controlled Shutdown Active" 5 "Uncontrolled Shutdown Active" 6 "Calibration in Progress" 14 "Error" ;
VAL_ 2566713854 EngTurboWastegateActr2OpStat 0 "Normal" 1 "Alarm" 2 "Alarm High Severity" 3 "Derate Active" 4 "Controlled Shutdown Active" 5 "Uncontrolled Shutdown Active" 14 "Error" ;
VAL_ 2566713854 EngExhstPressRgltrTempStat 0 "High Most severe" 1 "High Least severe" 2 "In Range" 3 "Low Least severe" 4 "Low Most severe" 5 "Not Defined" 6 "Error" 7 "Not available" ;
VAL_ 2566713854 EngExhstPressRgltrCtrlOpStatus 0 "Normal" 1 "Alarm" 2 "Alarm High Severity" 3 "Derate Active" 4 "Controlled Shutdown Active" 5 "Uncontrolled Shutdown Active" 14 "Error" 15 "Not available" ;
VAL_ 2566714110 EngThrottleValve1TemperatureStat 0 "High Most severe" 1 "High Least severe" 2 "In Range" 3 "Low Least severe" 4 "Low Most severe" 5 "Not Defined" 6 "Error" 7 "Not available" ;
VAL_ 2566714110 EngThrottleValve2TemperatureStat 0 "High Most severe" 1 "High Least severe" 2 "In Range" 3 "Low Least severe" 4 "Low Most severe" 5 "Not Defined" 6 "Error" 7 "Not available" ;
VAL_ 2566714110 EngFuelValve1TemperatureStatus 0 "High Most severe" 1 "High Least severe" 2 "In Range" 3 "Low Least severe" 4 "Low Most severe" 5 "Not Defined" 6 "Error" 7 "Not available" ;
VAL_ 2566714110 EngFuelValve2TemperatureStatus 0 "High Most severe" 1 "High Least severe" 2 "In Range" 3 "Low Least severe" 4 "Low Most severe" 5 "Not Defined" 6 "Error" 7 "Not available" ;
VAL_ 2566714110 EngThrottleValve1OperationStatus 0 "Normal" 1 "Alarm" 2 "Alarm High Severity" 3 "Derate Active" 4 "Controlled Shutdown Active" 5 "Uncontrolled Shutdown Active" 6 "Calibration in Progress" 14 "Error" 15 "Not available" ;
VAL_ 2566714110 EngThrottleValve2OperationStatus 0 "Normal" 1 "Alarm" 2 "Alarm High Severity" 3 "Derate Active" 4 "Controlled Shutdown Active" 5 "Uncontrolled Shutdown Active" 14 "Error" ;
VAL_ 2566714110 EngineFuelValve1OperationStatus 0 "Normal" 1 "Alarm" 2 "Alarm High Severity" 3 "Derate Active" 4 "Controlled Shutdown Active" 5 "Uncontrolled Shutdown Active" 6 "Test Mode Active" 14 "Error" ;
VAL_ 2566714110 EngineFuelValve2OperationStatus 0 "Normal" 1 "Alarm" 2 "Alarm High Severity" 3 "Derate Active" 4 "Controlled Shutdown Active" 5 "Uncontrolled Shutdown Active" 6 "Test Mode Active" 14 "Error" ;
VAL_ 2566714366 EngTurboCmprBypssActr2TempStat 0 "High Most severe" 1 "High Least severe" 2 "In Range" 3 "Low Least severe" 4 "Low Most severe" 5 "Not Defined" 6 "Error" 7 "Not available" ;
VAL_ 2566714366 EngTurboCmprssorBypssActr1OpStat 0 "Normal" 1 "Alarm" 2 "Alarm High Severity" 3 "Derate Active" 4 "Controlled Shutdown Active" 5 "Uncontrolled Shutdown Active" 14 "Error" ;
VAL_ 2566714366 EngTurboCmprssorBypssActr2OpStat 0 "Normal" 1 "Alarm" 2 "Alarm High Severity" 3 "Derate Active" 4 "Controlled Shutdown Active" 5 "Uncontrolled Shutdown Active" 14 "Error" ;
VAL_ 2566717950 LowVltgDiscnnctManDiscnnctStat 0 "Input off" 1 "Input on" 2 "Error" 3 "Not installed" ;
VAL_ 2566717950 LowVoltageDiscnnctManConnectStat 0 "Input off" 1 "Input on" 2 "Error" 3 "Not installed" ;
VAL_ 2566717950 LowVltgDiscnnctCurrentOprtngMde 0 "Automatic" 4 "Manual Disconnect via J1939 request" 5 "Manual Connect via J1939 request" 8 "Manual Disconnect via hardwired input" 9 "Manual Connect via hardwired input" 15 "Not available" ;
VAL_ 2566717950 LowVoltageDisconnectOutput3State 0 "Output off or disconnected" 1 "Output on or connected" 2 "Disconnect alarm expired, output off or disconnected" 3 "Disconnect pending, alarm active" 4 "Connect pending, alarm active" 14 "Output fault" 15 "Not available or not installed" ;
VAL_ 2566717950 LowVoltageDisconnectOutput2State 0 "Output off or disconnected" 1 "Output on or connected" 2 "Disconnect alarm expired, output off or disconnected" 3 "Disconnect pending, alarm active" 4 "Connect pending, alarm active" 14 "Output fault" 15 "Not available or not installed" ;
VAL_ 2566717950 LowVoltageDisconnectOutput1State 0 "Output off or disconnected" 1 "Output on or connected" 2 "Disconnect alarm expired, output off or disconnected" 3 "Disconnect pending, alarm active" 4 "Connect pending, alarm active" 14 "Output fault" 15 "Not available or not installed" ;
VAL_ 2566717950 LowVoltageDiscnnctVoutOutptState 0 "Output off or disconnected" 1 "Output on or connected" 2 "Disconnect alarm expired, output off or disconnected" 3 "Disconnect pending, alarm active" 4 "Connect pending, alarm active" 14 "Output fault" 15 "Not available or not installed" ;
VAL_ 2566718718 VehicleBatteryVoltageLowLampData 0 "Lamp deactivated (Off)" 1 "Lamp activated (On)" 2 "Error" 3 "Not available" ;
VAL_ 2566718718 VehicleFuelLevelLowLampData 0 "Lamp deactivated (Off)" 1 "Lamp activated (On)" 2 "Error" 3 "Not available" ;
VAL_ 2566718718 VehicleAirPressureLowLampData 0 "Lamp deactivated (Off)" 1 "Lamp activated (On)" 2 "Error" 3 "Not available" ;
VAL_ 2566718718 VehicleHVACRecirculationLampData 0 "Lamp deactivated (Off)" 1 "Lamp activated (On)" 2 "Error" 3 "Not available" ;
VAL_ 2566718718 VehicleBatteryChargingLampData 0 "Lamp deactivated (Off)" 1 "Lamp activated (On)" 2 "Error" 3 "Not available" ;
VAL_ 2566718718 HillHolderLampData 0 "Lamp deactivated (Off)" 1 "Lamp activated (On)" 2 "Error" 3 "Not available" ;
VAL_ 2566718974 EngineProtectLampData 0 "Lamp deactivated (Off)" 1 "Lamp activated (On)" 2 "Error" 3 "Not available" ;
VAL_ 2566718974 EngineAmberWarningLampData 0 "Lamp deactivated (Off)" 1 "Lamp activated (On)" 2 "Error" 3 "Not available" ;
VAL_ 2566718974 EngineRedStopLampData 0 "Lamp deactivated (Off)" 1 "Lamp activated (On)" 2 "Error" 3 "Not available" ;
VAL_ 2566718974 OBDMalfunctionIndicatorLampData 0 "Lamp deactivated (Off)" 1 "Lamp activated (On)" 2 "Error" 3 "Not available" ;
VAL_ 2566718974 EngineBrakeActiveLampData 0 "Lamp deactivated (Off)" 1 "Lamp activated (On)" 2 "Error" 3 "Not available" ;
VAL_ 2566718974 ComPrsionBrkEnblSwIndictrLampDat 0 "Lamp deactivated (Off)" 1 "Lamp activated (On)" 2 "Error" 3 "Not available" ;
VAL_ 2566718974 EngineOilPressureLowLampData 0 "Lamp deactivated (Off)" 1 "Lamp activated (On)" 2 "Error" 3 "Not available" ;
VAL_ 2566718974 EngCoolntTemperatureHighLampDat 0 "Lamp deactivated (Off)" 1 "Lamp activated (On)" 2 "Error" 3 "Not available" ;
VAL_ 2566718974 EngineCoolantLevelLowLampData 0 "Lamp deactivated (Off)" 1 "Lamp activated (On)" 2 "Error" 3 "Not available" ;
VAL_ 2566718974 EngineIdleManagementActvLampData 0 "Lamp deactivated (Off)" 1 "Lamp activated (On)" 2 "Error" 3 "Not available" ;
VAL_ 2566718974 EngAirFilterRestrictionLampDat 0 "Lamp deactivated (Off)" 1 "Lamp activated (On)" 2 "Error" 3 "Not available" ;
VAL_ 2566718974 EngFuelFilterRestrictedLampDat 0 "Lamp deactivated (Off)" 1 "Lamp activated (On)" 2 "Error" 3 "Not available" ;
VAL_ 2566718974 EngCtrlModule1ReadyForUseLampDat 0 "Lamp deactivated (Off)" 1 "Lamp activated (On)" 2 "Error" 3 "Not available" ;
VAL_ 2566718974 EngCtrlModule2ReadyForUseLampDat 0 "Lamp deactivated (Off)" 1 "Lamp activated (On)" 2 "Error" 3 "Not available" ;
VAL_ 2566718974 EngCtrlModule3ReadyForUseLampDat 0 "Lamp deactivated (Off)" 1 "Lamp activated (On)" 2 "Error" 3 "Not available" ;
VAL_ 2566718974 EngineSpeedHighLampData 0 "Lamp deactivated (Off)" 1 "Lamp activated (On)" 2 "Error" 3 "Not available" ;
VAL_ 2566718974 EngineSpeedVeryHighLampData 0 "Lamp deactivated (Off)" 1 "Lamp activated (On)" 2 "Error" 3 "Not available" ;
VAL_ 2566718974 VehicleAccltnRateLimitLampData 0 "Lamp deactivated (Off)" 1 "Lamp activated (On)" 2 "Error" 3 "Not available" ;
VAL_ 2566718974 EngineWaitToStartLampData 1 "Lamp actived (on)" 2 "Error" 3 "Not available" ;
VAL_ 2566719230 VehicleBatteryVoltageLowLampCmd 0 "Lamp Off" 1 "Lamp On" 2 "Reserved" 3 "Not available" ;
VAL_ 2566719230 VehicleFuelLevelLowLampCommand 0 "Lamp Off" 1 "Lamp On" 2 "Reserved" 3 "Not available" ;
VAL_ 2566719230 VehicleAirPressureLowLampCommand 0 "Lamp Off" 1 "Lamp On" 2 "Reserved" 3 "Not available" ;
VAL_ 2566719230 VehicleHVACRecirculationLampCmd 0 "Lamp Off" 1 "Lamp On" 2 "Reserved" 3 "Not available" ;
VAL_ 2566719230 VehicleBatteryChargingLampCmd 0 "Lamp Off" 1 "Lamp On" 2 "Reserved" 3 "Not available" ;
VAL_ 2566719230 HillHolderLampCommand 0 "Lamp Off" 1 "Lamp On" 2 "Lamp Flash (1 Hz)" 3 "Not available" ;
VAL_ 2566719486 EngineProtectLampCommand 0 "Lamp Off" 1 "Lamp On" 2 "Reserved" 3 "Not available" ;
VAL_ 2566719486 EngineAmberWarningLampCommand 0 "Lamp Off" 1 "Lamp On" 2 "Reserved" 3 "Not available" ;
VAL_ 2566719486 EngineRedStopLampCommand 0 "Lamp Off" 1 "Lamp On" 2 "Reserved" 3 "Not available" ;
VAL_ 2566719486 OBDMalfunctionIndicatorLampCmd 0 "Lamp Off" 1 "Lamp On" 2 "Reserved" 3 "Not available" ;
VAL_ 2566719486 EngineBrakeActiveLampCommand 0 "Lamp Off" 1 "Lamp On" 2 "Reserved" 3 "Not available" ;
VAL_ 2566719486 ComPrsionBrkEnblSwIndictrLampCmd 0 "Lamp Off" 1 "Lamp On" 2 "Reserved" 3 "Not available" ;
VAL_ 2566719486 EngineOilPressureLowLampCommand 0 "Lamp Off" 1 "Lamp On" 2 "Reserved" 3 "Not available" ;
VAL_ 2566719486 EngCoolntTemperatureHighLampCmd 0 "Lamp Off" 1 "Lamp On" 2 "Reserved" 3 "Not available" ;
VAL_ 2566719486 EngineCoolantLevelLowLampCommand 0 "Lamp Off" 1 "Lamp On" 2 "Reserved" 3 "Not available" ;
VAL_ 2566719486 EngineIdleManagementActvLampCmd 0 "Lamp Off" 1 "Lamp On" 2 "Reserved" 3 "Not available" ;
VAL_ 2566719486 EngAirFilterRestrictionLampCmd 0 "Lamp Off" 1 "Lamp On" 2 "Reserved" 3 "Not available" ;
VAL_ 2566719486 EngFuelFilterRestrictedLampCmd 0 "Lamp Off" 1 "Lamp On" 2 "Reserved" 3 "Not available" ;
VAL_ 2566719486 EngCtrlModule1ReadyForUseLampCmd 0 "Lamp Off" 1 "Lamp On" 2 "Reserved" 3 "Not available" ;
VAL_ 2566719486 EngCtrlModule2ReadyForUseLampCmd 0 "Lamp Off" 1 "Lamp On" 2 "Reserved" 3 "Not available" ;
VAL_ 2566719486 EngCtrlModule3ReadyForUseLampCmd 0 "Lamp Off" 1 "Lamp On" 2 "Reserved" 3 "Not available" ;
VAL_ 2566719486 EngineSpeedHighLampCommand 0 "Lamp Off" 1 "Lamp On" 2 "Reserved" 3 "Not available" ;
VAL_ 2566719486 EngineSpeedVeryHighLampCommand 0 "Lamp Off" 1 "Lamp On" 2 "Reserved" 3 "Not available" ;
VAL_ 2566719486 VehicleAccltnRateLimitLampCmd 0 "Lamp Off" 1 "Lamp On" 2 "Reserved" 3 "Not available" ;
VAL_ 2566722302 GeneratorOverheatStatus 0 "Not Overheat" 1 "Overheat" 2 "Error" 3 "Not Available" ;
VAL_ 2566722302 GensetSystemOutptVoltageRngStat 0 "Out of Range " 1 "In Range" 2 "Error" 3 "Not Available" ;
VAL_ 2566722302 GrappleMagnetSelectionSwitch 0 "Grapple Selected" 1 "Magnet Selected" 2 "Error" 3 "Not Available" ;
VAL_ 2566722302 GensetSoftstartActiveStatus 0 "Off" 1 "On" 2 "Error" 3 "Not available" ;
VAL_ 2566722302 ReverseCurrentRangeSetting 0 "1" 1 "2" 2 "3" 3 "4" 4 "5" 5 "6" 6 "7" 7 "8" 8 "9" 9 "10" 10 "11" 11 "12" 12 "13" 13 "14" 14 "15" 15 "16" 30 "Error" 31 "Not Available" ;
VAL_ 2566722302 GensetEnableActiveStatus 0 "Not Enabled" 1 "Enabled" 2 "Error" 3 "Not Avaialble" ;
VAL_ 2566722302 VoltageMonitorActiveStatus 0 "Monitor is Off" 1 "Monitor is On" 2 "Error" 3 "Not Available" ;
VAL_ 2566722302 GeneratorDutyCycleExceededStatus 0 "Duty Cycle Not Exceed" 1 "Duty Cycle Exceed" 2 "Error" 3 "Not Avaiable" ;
VAL_ 2566722814 BatteryCharger2State 0 "Idling" 1 "Charging the battery." 2 "Stand-by or maintaining the battery charge." 13 "Battery failure" 14 "Charger failure" 15 "Not available." ;
VAL_ 2566722814 BatteryCharger2PowerLineState 0 "Disconnected" 1 "Connected" 2 "Error" 3 "Not available" ;
VAL_ 2566723070 BatteryCharger1State 0 "Idling" 1 "Charging the battery." 2 "Stand-by or maintaining the battery charge." 13 "Battery failure" 14 "Charger failure" 15 "Not available." ;
VAL_ 2566723070 BatteryCharger1PowerLineState 0 "Disconnected" 1 "Connected" 2 "Error" 3 "Not available" ;
VAL_ 2499614462 DrvrOccupantClssfctnSystemStatus 0 "empty" 1 "child" 2 "small adult" 3 "adult" 4 "large adult" 5 "reserved" 6 "Error" 7 "not available" ;
VAL_ 2499614462 PassngOccupntClssfctnSystemStat 0 "empty" 1 "child" 2 "small adult" 3 "adult" 4 "large adult" 5 "Error" 6 "reserved" 7 "not available" ;
VAL_ 2499614462 OccupantClssfctnSystem3Status 0 "empty" 1 "occupied" 2 "Error" 3 "not available" ;
VAL_ 2499614462 OccupantClssfctnSystem4Status 0 "empty" 1 "occupied" 2 "Error" 3 "not available" ;
VAL_ 2499614462 OccupantClssfctnSystem5Status 0 "empty" 1 "occupied" 2 "Error" 3 "not available" ;
VAL_ 2499614462 OccupantClssfctnSystem6Status 0 "empty" 1 "occupied" 2 "Error" 3 "not available" ;
VAL_ 2499614462 OccupantClssfctnSystem7Status 0 "empty" 1 "occupied" 2 "Error" 3 "not available" ;
VAL_ 2499614462 OccupantClssfctnSystem8Status 0 "empty" 1 "occupied" 2 "Error" 3 "not available" ;
VAL_ 2499614462 OccupantClssfctnSystem9Status 0 "empty" 1 "occupied" 2 "Error" 3 "not available" ;
VAL_ 2499614462 OccupantClssfctnSystem10Status 0 "empty" 1 "occupied" 2 "Error" 3 "not available" ;
VAL_ 2499614718 DriverBeltlockStatus 0 "Unlocked" 1 "Locked" 2 "Error" 3 "Not available" ;
VAL_ 2499614718 PassengerBeltlockStatus 0 "Unlocked" 1 "Locked" 2 "Error" 3 "Not available" ;
VAL_ 2499614718 Beltlock3Status 0 "Unlocked" 1 "Locked" 2 "Error" 3 "Not available" ;
VAL_ 2499614718 Beltlock4Status 0 "Unlocked" 1 "Locked" 2 "Error" 3 "Not available" ;
VAL_ 2499614718 Beltlock5Status 0 "Unlocked" 1 "Locked" 2 "Error" 3 "Not available" ;
VAL_ 2499614718 Beltlock6Status 0 "Unlocked" 1 "Locked" 2 "Error" 3 "Not available" ;
VAL_ 2499614718 Beltlock7Status 0 "Unlocked" 1 "Locked" 2 "Error" 3 "Not available" ;
VAL_ 2499614718 Beltlock8Status 0 "Unlocked" 1 "Locked" 2 "Error" 3 "Not available" ;
VAL_ 2499614718 Beltlock9Status 0 "Unlocked" 1 "Locked" 2 "Error" 3 "Not available" ;
VAL_ 2499614718 Beltlock10Status 0 "Unlocked" 1 "Locked" 2 "Error" 3 "Not available" ;
VAL_ 2499614718 PassngAirbgDeActvtnSwitchStatus 0 "passenger airbag activated" 1 "passenger airbag deactivated" 2 "Error" 3 "not available" ;
VAL_ 2633832702 FrontalCollisionSensor1Type 0 "acceleration sensor" 1 "pressure sensor" 2 "rollrate sensor" 3 "sonic sensor" 4 "fiber-optic sensor" 5 "radar sensor" 6 "lidar sensor" 7 "optical sensor" 14 "Error" 15 "not available" ;
VAL_ 2633832702 FrontalCollisionSensor2Type 0 "acceleration sensor" 1 "pressure sensor" 2 "rollrate sensor" 3 "sonic sensor" 4 "fiber-optic sensor" 5 "radar sensor" 6 "lidar sensor" 7 "optical sensor" 14 "Error" 15 "not available" ;
VAL_ 2633832702 FrontalCollisionSensor3Type 0 "acceleration sensor" 1 "pressure sensor" 2 "rollrate sensor" 3 "sonic sensor" 4 "fiber-optic sensor" 5 "radar sensor" 6 "lidar sensor" 7 "optical sensor" 14 "Error" 15 "not available" ;
VAL_ 2633832702 FrontalCollisionSensor4Type 0 "acceleration sensor" 1 "pressure sensor" 2 "rollrate sensor" 3 "sonic sensor" 4 "fiber-optic sensor" 5 "radar sensor" 6 "lidar sensor" 7 "optical sensor" 14 "Error" 15 "not available" ;
VAL_ 2633832702 SideCollisionSensorFrontLeftType 0 "acceleration sensor" 1 "pressure sensor" 2 "rollrate sensor" 3 "sonic sensor" 4 "fiber-optic sensor" 5 "radar sensor" 6 "lidar sensor" 7 "optical sensor" 14 "Error" 15 "not available" ;
VAL_ 2633832702 SideCollsnSensorMidFrontLeftType 0 "acceleration sensor" 1 "pressure sensor" 2 "rollrate sensor" 3 "sonic sensor" 4 "fiber-optic sensor" 5 "radar sensor" 6 "lidar sensor" 7 "optical sensor" 14 "Error" 15 "not available" ;
VAL_ 2633832702 SideCollsnSensorMidRearLeftType 0 "acceleration sensor" 1 "pressure sensor" 2 "rollrate sensor" 3 "sonic sensor" 4 "fiber-optic sensor" 5 "radar sensor" 6 "lidar sensor" 7 "optical sensor" 14 "Error" 15 "not available" ;
VAL_ 2633832702 SideCollisionSensorRearLeftType 0 "acceleration sensor" 1 "pressure sensor" 2 "rollrate sensor" 3 "sonic sensor" 4 "fiber-optic sensor" 5 "radar sensor" 6 "lidar sensor" 7 "optical sensor" 14 "Error" 15 "not available" ;
VAL_ 2633832702 SideCollsnSensorFrontRightType 0 "acceleration sensor" 1 "pressure sensor" 2 "rollrate sensor" 3 "sonic sensor" 4 "fiber-optic sensor" 5 "radar sensor" 6 "lidar sensor" 7 "optical sensor" 14 "Error" 15 "not available" ;
VAL_ 2633832702 SideCollsnSensorMidFrntRightType 0 "acceleration sensor" 1 "pressure sensor" 2 "rollrate sensor" 3 "sonic sensor" 4 "fiber-optic sensor" 5 "radar sensor" 6 "lidar sensor" 7 "optical sensor" 14 "Error" 15 "not available" ;
VAL_ 2633832702 SideCollsnSensorMidRearRightType 0 "acceleration sensor" 1 "pressure sensor" 2 "rollrate sensor" 3 "sonic sensor" 4 "fiber-optic sensor" 5 "radar sensor" 6 "lidar sensor" 7 "optical sensor" 14 "Error" 15 "not available" ;
VAL_ 2633832702 SideCollisionSensorRearRightType 0 "acceleration sensor" 1 "pressure sensor" 2 "rollrate sensor" 3 "sonic sensor" 4 "fiber-optic sensor" 5 "radar sensor" 6 "lidar sensor" 7 "optical sensor" 14 "Error" 15 "not available" ;
VAL_ 2633832702 RearCollisionSensor1Type 0 "acceleration sensor" 1 "pressure sensor" 2 "rollrate sensor" 3 "sonic sensor" 4 "fiber-optic sensor" 5 "radar sensor" 6 "lidar sensor" 7 "optical sensor" 14 "Error" 15 "not available" ;
VAL_ 2633832702 RearCollisionSensor2Type 0 "acceleration sensor" 1 "pressure sensor" 2 "rollrate sensor" 3 "sonic sensor" 4 "fiber-optic sensor" 5 "radar sensor" 6 "lidar sensor" 7 "optical sensor" 14 "Error" 15 "not available" ;
VAL_ 2633832702 RearCollisionSensor3Type 0 "acceleration sensor" 1 "pressure sensor" 2 "rollrate sensor" 3 "sonic sensor" 4 "fiber-optic sensor" 5 "radar sensor" 6 "lidar sensor" 7 "optical sensor" 14 "Error" 15 "not available" ;
VAL_ 2633832702 RearCollisionSensor4Type 0 "acceleration sensor" 1 "pressure sensor" 2 "rollrate sensor" 3 "sonic sensor" 4 "fiber-optic sensor" 5 "radar sensor" 6 "lidar sensor" 7 "optical sensor" 14 "Error" 15 "not available" ;
VAL_ 2633832702 RolloverSensorType 0 "acceleration sensor" 1 "pressure sensor" 2 "rollrate sensor" 3 "sonic sensor" 4 "fiber-optic sensor" 5 "radar sensor" 6 "lidar sensor" 7 "optical sensor" 14 "Error" 15 "not available" ;
VAL_ 2365400062 Jystck10GrpXAxsNtrlPosStatus 0 "Not in Neutral Position" 1 "In Neutral Position" 2 "Error Indicator" 3 "Not Available" ;
VAL_ 2365400062 Jystck10GrpXAxsLvrLftNegPosStat 0 "Not on negative side of Neutral" 1 "On negative side of Neutral" 2 "Error Indicator" 3 "Not Available" ;
VAL_ 2365400062 Jystck10GrpXAxsLvrRghtPstvPsStat 0 "Not on Positive side of Neutral" 1 "On positive side of Neutral" 2 "Error Indicator" 3 "Not Available" ;
VAL_ 2365400062 Jystck10GrpYAxsNtrlPosStatus 0 "Not in Neutral Position" 1 "In Neutral Position" 2 "Error Indicator" 3 "Not Available" ;
VAL_ 2365400062 Jystck10GrpYAxsLvrBackNegPosStat 0 "Not on negative side of Neutral" 1 "On negative side of Neutral" 2 "Error Indicator" 3 "Not Available" ;
VAL_ 2365400062 Jystck10GrpYAxsLvrFrwdPstvPsStat 0 "Not on Positive side of Neutral" 1 "On positive side of Neutral" 2 "Error Indicator" 3 "Not Available" ;
VAL_ 2365400062 Jystck10ThetaAxsNtrlPosStatus 0 "Not in Neutral Position" 1 "In Neutral Position" 2 "Error Indicator" 3 "Not Available" ;
VAL_ 2365400062 Jystck10ThtAxsCntrClckwsNgPsStat 0 "Not on negative side of Neutral" 1 "On negative side of Neutral" 2 "Error Indicator" 3 "Not Available" ;
VAL_ 2365400062 Jystck10ThtAxsClckwsPstvPosStat 0 "Not on Positive side of Neutral" 1 "On positive side of Neutral" 2 "Error Indicator" 3 "Not Available" ;
VAL_ 2365400062 Jystck10ThetaAxsDetentPosStatus 0 "Not in the Detent Position" 1 "In the Detent Position" 2 "Error Indicator" 3 "Not Available" ;
VAL_ 2365400062 Jystck10GrpYAxsDetentPosStatus 0 "Not in the Detent Position" 1 "In the Detent Position" 2 "Error Indicator" 3 "Not Available" ;
VAL_ 2365400062 Jystck10GrpXAxsDetentPosStatus 0 "Not in the Detent Position" 1 "In the Detent Position" 2 "Error Indicator" 3 "Not Available" ;
VAL_ 2365400062 Joystick10Button16PressedStatus 0 "Button not pressed" 1 "Button pressed" 2 "Error Indicator" 3 "Not Available" ;
VAL_ 2365400062 Joystick10Button15PressedStatus 0 "Button not pressed" 1 "Button pressed" 2 "Error Indicator" 3 "Not Available" ;
VAL_ 2365400062 Joystick10Button14PressedStatus 0 "Button not pressed" 1 "Button pressed" 2 "Error Indicator" 3 "Not Available" ;
VAL_ 2365400062 Joystick10Button13PressedStatus 0 "Button not pressed" 1 "Button pressed" 2 "Error Indicator" 3 "Not Available" ;
VAL_ 2365400318 Jystck10XAxsNtrlPositionStatus 0 "Not in Neutral Position" 1 "In Neutral Position" 2 "Error Indicator" 3 "Not Available" ;
VAL_ 2365400318 Jystck10XAxsLvrLftNegPosStatus 0 "Not on negative side of Neutral" 1 "On negative side of Neutral" 2 "Error Indicator" 3 "Not Available" ;
VAL_ 2365400318 Jystck10XAxsLvrRghtPstvPosStatus 0 "Not on Positive side of Neutral" 1 "On positive side of Neutral" 2 "Error Indicator" 3 "Not Available" ;
VAL_ 2365400318 Jystck10YAxsNtrlPositionStatus 0 "Not in Neutral Position" 1 "In Neutral Position" 2 "Error Indicator" 3 "Not Available" ;
VAL_ 2365400318 Jystck10YAxsLvrBackNegPosStatus 0 "Not on negative side of Neutral" 1 "On negative side of Neutral" 2 "Error Indicator" 3 "Not Available" ;
VAL_ 2365400318 Jystck10YAxsLvrFrwdPstvPosStatus 0 "Not on Positive side of Neutral" 1 "On positive side of Neutral" 2 "Error Indicator" 3 "Not Available" ;
VAL_ 2365400318 Jystck10YAxsDetentPositionStatus 0 "Not in the Detent Position" 1 "In the Detent Position" 2 "Error Indicator" 3 "Not Available" ;
VAL_ 2365400318 Jystck10XAxsDetentPositionStatus 0 "Not in the Detent Position" 1 "In the Detent Position" 2 "Error Indicator" 3 "Not Available" ;
VAL_ 2365400318 Joystick10Button4PressedStatus 0 "Button not pressed" 1 "Button pressed" 2 "Error Indicator" 3 "Not Available" ;
VAL_ 2365400318 Joystick10Button3PressedStatus 0 "Button not pressed" 1 "Button pressed" 2 "Error Indicator" 3 "Not Available" ;
VAL_ 2365400318 Joystick10Button2PressedStatus 0 "Button not pressed" 1 "Button pressed" 2 "Error Indicator" 3 "Not Available" ;
VAL_ 2365400318 Joystick10Button1PressedStatus 0 "Button not pressed" 1 "Button pressed" 2 "Error Indicator" 3 "Not Available" ;
VAL_ 2365400318 Joystick10Button8PressedStatus 0 "Button not pressed" 1 "Button pressed" 2 "Error Indicator" 3 "Not Available" ;
VAL_ 2365400318 Joystick10Button7PressedStatus 0 "Button not pressed" 1 "Button pressed" 2 "Error Indicator" 3 "Not Available" ;
VAL_ 2365400318 Joystick10Button6PressedStatus 0 "Button not pressed" 1 "Button pressed" 2 "Error Indicator" 3 "Not Available" ;
VAL_ 2365400318 Joystick10Button5PressedStatus 0 "Button not pressed" 1 "Button pressed" 2 "Error Indicator" 3 "Not Available" ;
VAL_ 2365400318 Joystick10Button12PressedStatus 0 "Button not pressed" 1 "Button pressed" 2 "Error Indicator" 3 "Not Available" ;
VAL_ 2365400318 Joystick10Button11PressedStatus 0 "Button not pressed" 1 "Button pressed" 2 "Error Indicator" 3 "Not Available" ;
VAL_ 2365400318 Joystick10Button10PressedStatus 0 "Button not pressed" 1 "Button pressed" 2 "Error Indicator" 3 "Not Available" ;
VAL_ 2365400318 Joystick10Button9PressedStatus 0 "Button not pressed" 1 "Button pressed" 2 "Error Indicator" 3 "Not Available" ;
VAL_ 2365400574 Jystck9GrpXAxsNtrlPositionStatus 0 "Not in Neutral Position" 1 "In Neutral Position" 2 "Error Indicator" 3 "Not Available" ;
VAL_ 2365400574 Jystck9GrpXAxsLvrLftNegPosStatus 0 "Not on negative side of Neutral" 1 "On negative side of Neutral" 2 "Error Indicator" 3 "Not Available" ;
VAL_ 2365400574 Jystck9GrpXAxsLvrRghtPstvPosStat 0 "Not on Positive side of Neutral" 1 "On positive side of Neutral" 2 "Error Indicator" 3 "Not Available" ;
VAL_ 2365400574 Jystck9GrpYAxsNtrlPositionStatus 0 "Not in Neutral Position" 1 "In Neutral Position" 2 "Error Indicator" 3 "Not Available" ;
VAL_ 2365400574 Jystck9GrpYAxsLvrBackNegPosStat 0 "Not on negative side of Neutral" 1 "On negative side of Neutral" 2 "Error Indicator" 3 "Not Available" ;
VAL_ 2365400574 Jystck9GrpYAxsLvrFrwdPstvPosStat 0 "Not on Positive side of Neutral" 1 "On positive side of Neutral" 2 "Error Indicator" 3 "Not Available" ;
VAL_ 2365400574 Jystck9ThetaAxsNtrlPosStatus 0 "Not in Neutral Position" 1 "In Neutral Position" 2 "Error Indicator" 3 "Not Available" ;
VAL_ 2365400574 Jystck9ThtAxsCntrClckwsNegPsStat 0 "Not on negative side of Neutral" 1 "On negative side of Neutral" 2 "Error Indicator" 3 "Not Available" ;
VAL_ 2365400574 Jystck9ThetaAxsClckwsPstvPosStat 0 "Not on Positive side of Neutral" 1 "On positive side of Neutral" 2 "Error Indicator" 3 "Not Available" ;
VAL_ 2365400574 Jystck9ThetaAxsDetentPosStatus 0 "Not in the Detent Position" 1 "In the Detent Position" 2 "Error Indicator" 3 "Not Available" ;
VAL_ 2365400574 Jystck9GrpYAxsDetentPosStatus 0 "Not in the Detent Position" 1 "In the Detent Position" 2 "Error Indicator" 3 "Not Available" ;
VAL_ 2365400574 Jystck9GrpXAxsDetentPosStatus 0 "Not in the Detent Position" 1 "In the Detent Position" 2 "Error Indicator" 3 "Not Available" ;
VAL_ 2365400574 Joystick9Button16PressedStatus 0 "Button not pressed" 1 "Button pressed" 2 "Error Indicator" 3 "Not Available" ;
VAL_ 2365400574 Joystick9Button15PressedStatus 0 "Button not pressed" 1 "Button pressed" 2 "Error Indicator" 3 "Not Available" ;
VAL_ 2365400574 Joystick9Button14PressedStatus 0 "Button not pressed" 1 "Button pressed" 2 "Error Indicator" 3 "Not Available" ;
VAL_ 2365400574 Joystick9Button13PressedStatus 0 "Button not pressed" 1 "Button pressed" 2 "Error Indicator" 3 "Not Available" ;
VAL_ 2365400830 Jystck9XAxsNeutralPositionStatus 0 "Not in Neutral Position" 1 "In Neutral Position" 2 "Error Indicator" 3 "Not Available" ;
VAL_ 2365400830 Jystck9XAxsLvrLftNegPosStatus 0 "Not on negative side of Neutral" 1 "On negative side of Neutral" 2 "Error Indicator" 3 "Not Available" ;
VAL_ 2365400830 Jystck9XAxsLvrRightPstvPosStatus 0 "Not on Positive side of Neutral" 1 "On positive side of Neutral" 2 "Error Indicator" 3 "Not Available" ;
VAL_ 2365400830 Jystck9YAxsNeutralPositionStatus 0 "Not in Neutral Position" 1 "In Neutral Position" 2 "Error Indicator" 3 "Not Available" ;
VAL_ 2365400830 Jystck9YAxsLvrBackNegPosStatus 0 "Not on negative side of Neutral" 1 "On negative side of Neutral" 2 "Error Indicator" 3 "Not Available" ;
VAL_ 2365400830 Jystck9YAxsLvrFrwdPstvPosStatus 0 "Not on Positive side of Neutral" 1 "On positive side of Neutral" 2 "Error Indicator" 3 "Not Available" ;
VAL_ 2365400830 Jystck9YAxsDetentPositionStatus 0 "Not in the Detent Position" 1 "In the Detent Position" 2 "Error Indicator" 3 "Not Available" ;
VAL_ 2365400830 Jystck9XAxsDetentPositionStatus 0 "Not in the Detent Position" 1 "In the Detent Position" 2 "Error Indicator" 3 "Not Available" ;
VAL_ 2365400830 Joystick9Button4PressedStatus 0 "Button not pressed" 1 "Button pressed" 2 "Error Indicator" 3 "Not Available" ;
VAL_ 2365400830 Joystick9Button3PressedStatus 0 "Button not pressed" 1 "Button pressed" 2 "Error Indicator" 3 "Not Available" ;
VAL_ 2365400830 Joystick9Button2PressedStatus 0 "Button not pressed" 1 "Button pressed" 2 "Error Indicator" 3 "Not Available" ;
VAL_ 2365400830 Joystick9Button1PressedStatus 0 "Button not pressed" 1 "Button pressed" 2 "Error Indicator" 3 "Not Available" ;
VAL_ 2365400830 Joystick9Button8PressedStatus 0 "Button not pressed" 1 "Button pressed" 2 "Error Indicator" 3 "Not Available" ;
VAL_ 2365400830 Joystick9Button7PressedStatus 0 "Button not pressed" 1 "Button pressed" 2 "Error Indicator" 3 "Not Available" ;
VAL_ 2365400830 Joystick9Button6PressedStatus 0 "Button not pressed" 1 "Button pressed" 2 "Error Indicator" 3 "Not Available" ;
VAL_ 2365400830 Joystick9Button5PressedStatus 0 "Button not pressed" 1 "Button pressed" 2 "Error Indicator" 3 "Not Available" ;
VAL_ 2365400830 Joystick9Button12PressedStatus 0 "Button not pressed" 1 "Button pressed" 2 "Error Indicator" 3 "Not Available" ;
VAL_ 2365400830 Joystick9Button11PressedStatus 0 "Button not pressed" 1 "Button pressed" 2 "Error Indicator" 3 "Not Available" ;
VAL_ 2365400830 Joystick9Button10PressedStatus 0 "Button not pressed" 1 "Button pressed" 2 "Error Indicator" 3 "Not Available" ;
VAL_ 2365400830 Joystick9Button9PressedStatus 0 "Button not pressed" 1 "Button pressed" 2 "Error Indicator" 3 "Not Available" ;
VAL_ 2365401086 Jystck8GrpXAxsNtrlPositionStatus 0 "Not in Neutral Position" 1 "In Neutral Position" 2 "Error Indicator" 3 "Not Available" ;
VAL_ 2365401086 Jystck8GrpXAxsLvrLftNegPosStatus 0 "Not on negative side of Neutral" 1 "On negative side of Neutral" 2 "Error Indicator" 3 "Not Available" ;
VAL_ 2365401086 Jystck8GrpXAxsLvrRghtPstvPosStat 0 "Not on Positive side of Neutral" 1 "On positive side of Neutral" 2 "Error Indicator" 3 "Not Available" ;
VAL_ 2365401086 Jystck8GrpYAxsNtrlPositionStatus 0 "Not in Neutral Position" 1 "In Neutral Position" 2 "Error Indicator" 3 "Not Available" ;
VAL_ 2365401086 Jystck8GrpYAxsLvrBackNegPosStat 0 "Not on negative side of Neutral" 1 "On negative side of Neutral" 2 "Error Indicator" 3 "Not Available" ;
VAL_ 2365401086 Jystck8GrpYAxsLvrFrwdPstvPosStat 0 "Not on Positive side of Neutral" 1 "On positive side of Neutral" 2 "Error Indicator" 3 "Not Available" ;
VAL_ 2365401086 Jystck8ThetaAxsNtrlPosStatus 0 "Not in Neutral Position" 1 "In Neutral Position" 2 "Error Indicator" 3 "Not Available" ;
VAL_ 2365401086 Jystck8ThtAxsCntrClckwsNegPsStat 0 "Not on negative side of Neutral" 1 "On negative side of Neutral" 2 "Error Indicator" 3 "Not Available" ;
VAL_ 2365401086 Jystck8ThetaAxsClckwsPstvPosStat 0 "Not on Positive side of Neutral" 1 "On positive side of Neutral" 2 "Error Indicator" 3 "Not Available" ;
VAL_ 2365401086 Jystck8ThetaAxsDetentPosStatus 0 "Not in the Detent Position" 1 "In the Detent Position" 2 "Error Indicator" 3 "Not Available" ;
VAL_ 2365401086 Jystck8GrpYAxsDetentPosStatus 0 "Not in the Detent Position" 1 "In the Detent Position" 2 "Error Indicator" 3 "Not Available" ;
VAL_ 2365401086 Jystck8GrpXAxsDetentPosStatus 0 "Not in the Detent Position" 1 "In the Detent Position" 2 "Error Indicator" 3 "Not Available" ;
VAL_ 2365401086 Joystick8Button16PressedStatus 0 "Button not pressed" 1 "Button pressed" 2 "Error Indicator" 3 "Not Available" ;
VAL_ 2365401086 Joystick8Button15PressedStatus 0 "Button not pressed" 1 "Button pressed" 2 "Error Indicator" 3 "Not Available" ;
VAL_ 2365401086 Joystick8Button14PressedStatus 0 "Button not pressed" 1 "Button pressed" 2 "Error Indicator" 3 "Not Available" ;
VAL_ 2365401086 Joystick8Button13PressedStatus 0 "Button not pressed" 1 "Button pressed" 2 "Error Indicator" 3 "Not Available" ;
VAL_ 2365401342 Jystck8XAxsNeutralPositionStatus 0 "Not in Neutral Position" 1 "In Neutral Position" 2 "Error Indicator" 3 "Not Available" ;
VAL_ 2365401342 Jystck8XAxsLvrLftNegPosStatus 0 "Not on negative side of Neutral" 1 "On negative side of Neutral" 2 "Error Indicator" 3 "Not Available" ;
VAL_ 2365401342 Jystck8XAxsLvrRightPstvPosStatus 0 "Not on Positive side of Neutral" 1 "On positive side of Neutral" 2 "Error Indicator" 3 "Not Available" ;
VAL_ 2365401342 Jystck8YAxsNeutralPositionStatus 0 "Not in Neutral Position" 1 "In Neutral Position" 2 "Error Indicator" 3 "Not Available" ;
VAL_ 2365401342 Jystck8YAxsLvrBackNegPosStatus 0 "Not on negative side of Neutral" 1 "On negative side of Neutral" 2 "Error Indicator" 3 "Not Available" ;
VAL_ 2365401342 Jystck8YAxsLvrFrwdPstvPosStatus 0 "Not on Positive side of Neutral" 1 "On positive side of Neutral" 2 "Error Indicator" 3 "Not Available" ;
VAL_ 2365401342 Jystck8YAxsDetentPositionStatus 0 "Not in the Detent Position" 1 "In the Detent Position" 2 "Error Indicator" 3 "Not Available" ;
VAL_ 2365401342 Jystck8XAxsDetentPositionStatus 0 "Not in the Detent Position" 1 "In the Detent Position" 2 "Error Indicator" 3 "Not Available" ;
VAL_ 2365401342 Joystick8Button4PressedStatus 0 "Button not pressed" 1 "Button pressed" 2 "Error Indicator" 3 "Not Available" ;
VAL_ 2365401342 Joystick8Button3PressedStatus 0 "Button not pressed" 1 "Button pressed" 2 "Error Indicator" 3 "Not Available" ;
VAL_ 2365401342 Joystick8Button2PressedStatus 0 "Button not pressed" 1 "Button pressed" 2 "Error Indicator" 3 "Not Available" ;
VAL_ 2365401342 Joystick8Button1PressedStatus 0 "Button not pressed" 1 "Button pressed" 2 "Error Indicator" 3 "Not Available" ;
VAL_ 2365401342 Joystick8Button8PressedStatus 0 "Button not pressed" 1 "Button pressed" 2 "Error Indicator" 3 "Not Available" ;
VAL_ 2365401342 Joystick8Button7PressedStatus 0 "Button not pressed" 1 "Button pressed" 2 "Error Indicator" 3 "Not Available" ;
VAL_ 2365401342 Joystick8Button6PressedStatus 0 "Button not pressed" 1 "Button pressed" 2 "Error Indicator" 3 "Not Available" ;
VAL_ 2365401342 Joystick8Button5PressedStatus 0 "Button not pressed" 1 "Button pressed" 2 "Error Indicator" 3 "Not Available" ;
VAL_ 2365401342 Joystick8Button12PressedStatus 0 "Button not pressed" 1 "Button pressed" 2 "Error Indicator" 3 "Not Available" ;
VAL_ 2365401342 Joystick8Button11PressedStatus 0 "Button not pressed" 1 "Button pressed" 2 "Error Indicator" 3 "Not Available" ;
VAL_ 2365401342 Joystick8Button10PressedStatus 0 "Button not pressed" 1 "Button pressed" 2 "Error Indicator" 3 "Not Available" ;
VAL_ 2365401342 Joystick8Button9PressedStatus 0 "Button not pressed" 1 "Button pressed" 2 "Error Indicator" 3 "Not Available" ;
VAL_ 2365401598 Jystck7GrpXAxsNtrlPositionStatus 0 "Not in Neutral Position" 1 "In Neutral Position" 2 "Error Indicator" 3 "Not Available" ;
VAL_ 2365401598 Jystck7GrpXAxsLvrLftNegPosStatus 0 "Not on negative side of Neutral" 1 "On negative side of Neutral" 2 "Error Indicator" 3 "Not Available" ;
VAL_ 2365401598 Jystck7GrpXAxsLvrRghtPstvPosStat 0 "Not on Positive side of Neutral" 1 "On positive side of Neutral" 2 "Error Indicator" 3 "Not Available" ;
VAL_ 2365401598 Jystck7GrpYAxsNtrlPositionStatus 0 "Not in Neutral Position" 1 "In Neutral Position" 2 "Error Indicator" 3 "Not Available" ;
VAL_ 2365401598 Jystck7GrpYAxsLvrBackNegPosStat 0 "Not on negative side of Neutral" 1 "On negative side of Neutral" 2 "Error Indicator" 3 "Not Available" ;
VAL_ 2365401598 Jystck7GrpYAxsLvrFrwdPstvPosStat 0 "Not on Positive side of Neutral" 1 "On positive side of Neutral" 2 "Error Indicator" 3 "Not Available" ;
VAL_ 2365401598 Jystck7ThetaAxsNtrlPosStatus 0 "Not in Neutral Position" 1 "In Neutral Position" 2 "Error Indicator" 3 "Not Available" ;
VAL_ 2365401598 Jystck7ThtAxsCntrClckwsNegPsStat 0 "Not on negative side of Neutral" 1 "On negative side of Neutral" 2 "Error Indicator" 3 "Not Available" ;
VAL_ 2365401598 Jystck7ThetaAxsClckwsPstvPosStat 0 "Not on Positive side of Neutral" 1 "On positive side of Neutral" 2 "Error Indicator" 3 "Not Available" ;
VAL_ 2365401598 Jystck7ThetaAxsDetentPosStatus 0 "Not in the Detent Position" 1 "In the Detent Position" 2 "Error Indicator" 3 "Not Available" ;
VAL_ 2365401598 Jystck7GrpYAxsDetentPosStatus 0 "Not in the Detent Position" 1 "In the Detent Position" 2 "Error Indicator" 3 "Not Available" ;
VAL_ 2365401598 Jystck7GrpXAxsDetentPosStatus 0 "Not in the Detent Position" 1 "In the Detent Position" 2 "Error Indicator" 3 "Not Available" ;
VAL_ 2365401598 Joystick7Button16PressedStatus 0 "Button not pressed" 1 "Button pressed" 2 "Error Indicator" 3 "Not Available" ;
VAL_ 2365401598 Joystick7Button15PressedStatus 0 "Button not pressed" 1 "Button pressed" 2 "Error Indicator" 3 "Not Available" ;
VAL_ 2365401598 Joystick7Button14PressedStatus 0 "Button not pressed" 1 "Button pressed" 2 "Error Indicator" 3 "Not Available" ;
VAL_ 2365401598 Joystick7Button13PressedStatus 0 "Button not pressed" 1 "Button pressed" 2 "Error Indicator" 3 "Not Available" ;
VAL_ 2365401854 Jystck7XAxsNeutralPositionStatus 0 "Not in Neutral Position" 1 "In Neutral Position" 2 "Error Indicator" 3 "Not Available" ;
VAL_ 2365401854 Jystck7XAxsLvrLftNegPosStatus 0 "Not on negative side of Neutral" 1 "On negative side of Neutral" 2 "Error Indicator" 3 "Not Available" ;
VAL_ 2365401854 Jystck7XAxsLvrRightPstvPosStatus 0 "Not on Positive side of Neutral" 1 "On positive side of Neutral" 2 "Error Indicator" 3 "Not Available" ;
VAL_ 2365401854 Jystck7YAxsNeutralPositionStatus 0 "Not in Neutral Position" 1 "In Neutral Position" 2 "Error Indicator" 3 "Not Available" ;
VAL_ 2365401854 Jystck7YAxsLvrBackNegPosStatus 0 "Not on negative side of Neutral" 1 "On negative side of Neutral" 2 "Error Indicator" 3 "Not Available" ;
VAL_ 2365401854 Jystck7YAxsLvrFrwdPstvPosStatus 0 "Not on Positive side of Neutral" 1 "On positive side of Neutral" 2 "Error Indicator" 3 "Not Available" ;
VAL_ 2365401854 Jystck7YAxsDetentPositionStatus 0 "Not in the Detent Position" 1 "In the Detent Position" 2 "Error Indicator" 3 "Not Available" ;
VAL_ 2365401854 Jystck7XAxsDetentPositionStatus 0 "Not in the Detent Position" 1 "In the Detent Position" 2 "Error Indicator" 3 "Not Available" ;
VAL_ 2365401854 Joystick7Button4PressedStatus 0 "Button not pressed" 1 "Button pressed" 2 "Error Indicator" 3 "Not Available" ;
VAL_ 2365401854 Joystick7Button3PressedStatus 0 "Button not pressed" 1 "Button pressed" 2 "Error Indicator" 3 "Not Available" ;
VAL_ 2365401854 Joystick7Button2PressedStatus 0 "Button not pressed" 1 "Button pressed" 2 "Error Indicator" 3 "Not Available" ;
VAL_ 2365401854 Joystick7Button1PressedStatus 0 "Button not pressed" 1 "Button pressed" 2 "Error Indicator" 3 "Not Available" ;
VAL_ 2365401854 Joystick7Button8PressedStatus 0 "Button not pressed" 1 "Button pressed" 2 "Error Indicator" 3 "Not Available" ;
VAL_ 2365401854 Joystick7Button7PressedStatus 0 "Button not pressed" 1 "Button pressed" 2 "Error Indicator" 3 "Not Available" ;
VAL_ 2365401854 Joystick7Button6PressedStatus 0 "Button not pressed" 1 "Button pressed" 2 "Error Indicator" 3 "Not Available" ;
VAL_ 2365401854 Joystick7Button5PressedStatus 0 "Button not pressed" 1 "Button pressed" 2 "Error Indicator" 3 "Not Available" ;
VAL_ 2365401854 Joystick7Button12PressedStatus 0 "Button not pressed" 1 "Button pressed" 2 "Error Indicator" 3 "Not Available" ;
VAL_ 2365401854 Joystick7Button11PressedStatus 0 "Button not pressed" 1 "Button pressed" 2 "Error Indicator" 3 "Not Available" ;
VAL_ 2365401854 Joystick7Button10PressedStatus 0 "Button not pressed" 1 "Button pressed" 2 "Error Indicator" 3 "Not Available" ;
VAL_ 2365401854 Joystick7Button9PressedStatus 0 "Button not pressed" 1 "Button pressed" 2 "Error Indicator" 3 "Not Available" ;
